VERSION ""

NS_ :

BS_:

BU_: Gateway_25 FCM_A0 FLR SRR_RL External_Tool SRR_FL Steering_E4 VCU_47 CLS_17 ESC_0B EMS_00

BO_ 662 SRR_FL_DETECTION_089_092: 64 SRR_FL
 SG_ DET_RANGE_089 : 24|15@1+ (0.015625,0) [0|500] "m"  SRR_RL
 SG_ DET_RANGE_ERR_089 : 40|7@1+ (0.0075,0) [0|0.9525] "m"  SRR_RL
 SG_ DET_RANGE_VELOCITY_089 : 48|15@1+ (0.0078125,-128) [-128|127.9921875] "m/s"  SRR_RL
 SG_ DET_RANGE_VELOCITY_ERR_089 : 64|8@1+ (0.003,0) [0|0.765] "m/s"  SRR_RL
 SG_ DET_AZIMUTH_089 : 88|13@1+ (0.0004,-1.5708) [-1.5708|1.5708] "rad"  SRR_RL
 SG_ DET_AZIMUTH_ERR_089 : 105|7@1+ (0.00087267,0) [0|0.11082909] "rad"  SRR_RL
 SG_ DET_ELEVATION_089 : 72|8@1+ (0.00275,-0.34925) [-0.34925|0.34925] "rad"  SRR_RL
 SG_ DET_ELEVATION_ERR_089 : 80|6@1+ (0.00174533,0) [0|0.10995579] "rad"  SRR_RL
 SG_ DET_RCS_089 : 128|8@1+ (0.5,-64) [-64|63.5] "dBsm"  SRR_RL
 SG_ DET_BI_STATIC_FLAG_089 : 104|1@1+ (1,0) [0|1] ""  SRR_RL
 SG_ DET_SUPER_RES_TARGET_089 : 87|1@1+ (1,0) [0|1] ""  SRR_RL
 SG_ DET_SNR_089 : 120|8@1+ (0.35156,0) [0|89.6478] "dB"  SRR_RL
 SG_ DET_EXISTENCE_PROB_089 : 112|6@1+ (1.588,0) [0|100] "%"  SRR_RL
 SG_ DET_HVC_FLAG_089 : 86|1@1+ (1,0) [0|1] ""  SRR_RL
 SG_ DET_CONFD_AZIMUTH_089 : 118|2@1+ (1,0) [0|3] ""  SRR_RL
 SG_ DET_CONFD_ELEVATION_089 : 101|2@1+ (1,0) [0|3] ""  SRR_RL
 SG_ DET_PROB_1STAZHYPO_089 : 103|1@1+ (1,0) [0|1] ""  SRR_RL
 SG_ DET_IDM_089 : 63|1@1+ (1,0) [0|1] ""  SRR_RL
 SG_ DET_MTD_089 : 47|1@1+ (1,0) [0|1] ""  SRR_RL
 SG_ DET_BELOW_RAIN_THOLD_089 : 39|1@1+ (1,0) [0|1] ""  SRR_RL
 SG_ DET_RANGE_090 : 136|15@1+ (0.015625,0) [0|500] "m"  SRR_RL
 SG_ DET_RANGE_ERR_090 : 152|7@1+ (0.0075,0) [0|0.9525] "m"  SRR_RL
 SG_ DET_RANGE_VELOCITY_090 : 160|15@1+ (0.0078125,-128) [-128|127.9921875] "m/s"  SRR_RL
 SG_ DET_RANGE_VELOCITY_ERR_090 : 176|8@1+ (0.003,0) [0|0.765] "m/s"  SRR_RL
 SG_ DET_AZIMUTH_090 : 200|13@1+ (0.0004,-1.5708) [-1.5708|1.5708] "rad"  SRR_RL
 SG_ DET_AZIMUTH_ERR_090 : 217|7@1+ (0.00087267,0) [0|0.11082909] "rad"  SRR_RL
 SG_ DET_ELEVATION_090 : 184|8@1+ (0.00275,-0.34925) [-0.34925|0.34925] "rad"  SRR_RL
 SG_ DET_ELEVATION_ERR_090 : 192|6@1+ (0.00174533,0) [0|0.10995579] "rad"  SRR_RL
 SG_ DET_RCS_090 : 240|8@1+ (0.5,-64) [-64|63.5] "dBsm"  SRR_RL
 SG_ DET_BI_STATIC_FLAG_090 : 216|1@1+ (1,0) [0|1] ""  SRR_RL
 SG_ DET_SUPER_RES_TARGET_090 : 199|1@1+ (1,0) [0|1] ""  SRR_RL
 SG_ DET_SNR_090 : 232|8@1+ (0.35156,0) [0|89.6478] "dB"  SRR_RL
 SG_ DET_EXISTENCE_PROB_090 : 224|6@1+ (1.588,0) [0|100] "%"  SRR_RL
 SG_ DET_HVC_FLAG_090 : 198|1@1+ (1,0) [0|1] ""  SRR_RL
 SG_ DET_CONFD_AZIMUTH_090 : 230|2@1+ (1,0) [0|3] ""  SRR_RL
 SG_ DET_CONFD_ELEVATION_090 : 213|2@1+ (1,0) [0|3] ""  SRR_RL
 SG_ DET_PROB_1STAZHYPO_090 : 215|1@1+ (1,0) [0|1] ""  SRR_RL
 SG_ DET_IDM_090 : 175|1@1+ (1,0) [0|1] ""  SRR_RL
 SG_ DET_MTD_090 : 159|1@1+ (1,0) [0|1] ""  SRR_RL
 SG_ DET_BELOW_RAIN_THOLD_090 : 151|1@1+ (1,0) [0|1] ""  SRR_RL
 SG_ DET_RANGE_091 : 248|15@1+ (0.015625,0) [0|500] "m"  SRR_RL
 SG_ DET_RANGE_ERR_091 : 264|7@1+ (0.0075,0) [0|0.9525] "m"  SRR_RL
 SG_ DET_RANGE_VELOCITY_091 : 272|15@1+ (0.0078125,-128) [-128|127.9921875] "m/s"  SRR_RL
 SG_ DET_RANGE_VELOCITY_ERR_091 : 288|8@1+ (0.003,0) [0|0.765] "m/s"  SRR_RL
 SG_ DET_AZIMUTH_091 : 312|13@1+ (0.0004,-1.5708) [-1.5708|1.5708] "rad"  SRR_RL
 SG_ DET_AZIMUTH_ERR_091 : 329|7@1+ (0.00087267,0) [0|0.11082909] "rad"  SRR_RL
 SG_ DET_ELEVATION_091 : 296|8@1+ (0.00275,-0.34925) [-0.34925|0.34925] "rad"  SRR_RL
 SG_ DET_ELEVATION_ERR_091 : 304|6@1+ (0.00174533,0) [0|0.10995579] "rad"  SRR_RL
 SG_ DET_RCS_091 : 352|8@1+ (0.5,-64) [-64|63.5] "dBsm"  SRR_RL
 SG_ DET_BI_STATIC_FLAG_091 : 328|1@1+ (1,0) [0|1] ""  SRR_RL
 SG_ DET_SUPER_RES_TARGET_091 : 311|1@1+ (1,0) [0|1] ""  SRR_RL
 SG_ DET_SNR_091 : 344|8@1+ (0.35156,0) [0|89.6478] "dB"  SRR_RL
 SG_ DET_EXISTENCE_PROB_091 : 336|6@1+ (1.588,0) [0|100] "%"  SRR_RL
 SG_ DET_HVC_FLAG_091 : 310|1@1+ (1,0) [0|1] ""  SRR_RL
 SG_ DET_CONFD_AZIMUTH_091 : 342|2@1+ (1,0) [0|3] ""  SRR_RL
 SG_ DET_CONFD_ELEVATION_091 : 325|2@1+ (1,0) [0|3] ""  SRR_RL
 SG_ DET_PROB_1STAZHYPO_091 : 327|1@1+ (1,0) [0|1] ""  SRR_RL
 SG_ DET_IDM_091 : 287|1@1+ (1,0) [0|1] ""  SRR_RL
 SG_ DET_MTD_091 : 271|1@1+ (1,0) [0|1] ""  SRR_RL
 SG_ DET_BELOW_RAIN_THOLD_091 : 263|1@1+ (1,0) [0|1] ""  SRR_RL
 SG_ DET_RANGE_092 : 360|15@1+ (0.015625,0) [0|500] "m"  SRR_RL
 SG_ DET_RANGE_ERR_092 : 376|7@1+ (0.0075,0) [0|0.9525] "m"  SRR_RL
 SG_ DET_RANGE_VELOCITY_092 : 384|15@1+ (0.0078125,-128) [-128|127.9921875] "m/s"  SRR_RL
 SG_ DET_RANGE_VELOCITY_ERR_092 : 400|8@1+ (0.003,0) [0|0.765] "m/s"  SRR_RL
 SG_ DET_AZIMUTH_092 : 424|13@1+ (0.0004,-1.5708) [-1.5708|1.5708] "rad"  SRR_RL
 SG_ DET_AZIMUTH_ERR_092 : 441|7@1+ (0.00087267,0) [0|0.11082909] "rad"  SRR_RL
 SG_ DET_ELEVATION_092 : 408|8@1+ (0.00275,-0.34925) [-0.34925|0.34925] "rad"  SRR_RL
 SG_ DET_ELEVATION_ERR_092 : 416|6@1+ (0.00174533,0) [0|0.10995579] "rad"  SRR_RL
 SG_ DET_RCS_092 : 464|8@1+ (0.5,-64) [-64|63.5] "dBsm"  SRR_RL
 SG_ DET_BI_STATIC_FLAG_092 : 440|1@1+ (1,0) [0|1] ""  SRR_RL
 SG_ DET_SUPER_RES_TARGET_092 : 423|1@1+ (1,0) [0|1] ""  SRR_RL
 SG_ DET_SNR_092 : 456|8@1+ (0.35156,0) [0|89.6478] "dB"  SRR_RL
 SG_ DET_EXISTENCE_PROB_092 : 448|6@1+ (1.588,0) [0|100] "%"  SRR_RL
 SG_ DET_HVC_FLAG_092 : 422|1@1+ (1,0) [0|1] ""  SRR_RL
 SG_ DET_CONFD_AZIMUTH_092 : 454|2@1+ (1,0) [0|3] ""  SRR_RL
 SG_ DET_CONFD_ELEVATION_092 : 437|2@1+ (1,0) [0|3] ""  SRR_RL
 SG_ DET_MH_SCAN_INDEX_4LSB_089_092 : 476|4@1+ (1,0) [0|15] ""  SRR_RL
 SG_ DET_MH_CYCLE_COUNTER_089_092 : 16|8@1+ (1,0) [0|255] ""  SRR_RL
 SG_ DET_MH_CRC16_089_092 : 0|16@1+ (1,0) [0|65535] ""  SRR_RL
 SG_ DET_PROB_1STAZHYPO_092 : 439|1@1+ (1,0) [0|1] ""  SRR_RL
 SG_ DET_IDM_092 : 399|1@1+ (1,0) [0|1] ""  SRR_RL
 SG_ DET_MTD_092 : 383|1@1+ (1,0) [0|1] ""  SRR_RL
 SG_ DET_BELOW_RAIN_THOLD_092 : 375|1@1+ (1,0) [0|1] ""  SRR_RL

BO_ 663 SRR_FL_DETECTION_093_096: 64 SRR_FL
 SG_ DET_RANGE_093 : 24|15@1+ (0.015625,0) [0|500] "m"  SRR_RL
 SG_ DET_RANGE_ERR_093 : 40|7@1+ (0.0075,0) [0|0.9525] "m"  SRR_RL
 SG_ DET_RANGE_VELOCITY_093 : 48|15@1+ (0.0078125,-128) [-128|127.9921875] "m/s"  SRR_RL
 SG_ DET_RANGE_VELOCITY_ERR_093 : 64|8@1+ (0.003,0) [0|0.765] "m/s"  SRR_RL
 SG_ DET_AZIMUTH_093 : 88|13@1+ (0.0004,-1.5708) [-1.5708|1.5708] "rad"  SRR_RL
 SG_ DET_AZIMUTH_ERR_093 : 105|7@1+ (0.00087267,0) [0|0.11082909] "rad"  SRR_RL
 SG_ DET_ELEVATION_093 : 72|8@1+ (0.00275,-0.34925) [-0.34925|0.34925] "rad"  SRR_RL
 SG_ DET_ELEVATION_ERR_093 : 80|6@1+ (0.00174533,0) [0|0.10995579] "rad"  SRR_RL
 SG_ DET_RCS_093 : 128|8@1+ (0.5,-64) [-64|63.5] "dBsm"  SRR_RL
 SG_ DET_BI_STATIC_FLAG_093 : 104|1@1+ (1,0) [0|1] ""  SRR_RL
 SG_ DET_SUPER_RES_TARGET_093 : 87|1@1+ (1,0) [0|1] ""  SRR_RL
 SG_ DET_SNR_093 : 120|8@1+ (0.35156,0) [0|89.6478] "dB"  SRR_RL
 SG_ DET_EXISTENCE_PROB_093 : 112|6@1+ (1.588,0) [0|100] "%"  SRR_RL
 SG_ DET_HVC_FLAG_093 : 86|1@1+ (1,0) [0|1] ""  SRR_RL
 SG_ DET_CONFD_AZIMUTH_093 : 118|2@1+ (1,0) [0|3] ""  SRR_RL
 SG_ DET_CONFD_ELEVATION_093 : 101|2@1+ (1,0) [0|3] ""  SRR_RL
 SG_ DET_PROB_1STAZHYPO_093 : 103|1@1+ (1,0) [0|1] ""  SRR_RL
 SG_ DET_IDM_093 : 63|1@1+ (1,0) [0|1] ""  SRR_RL
 SG_ DET_MTD_093 : 47|1@1+ (1,0) [0|1] ""  SRR_RL
 SG_ DET_BELOW_RAIN_THOLD_093 : 39|1@1+ (1,0) [0|1] ""  SRR_RL
 SG_ DET_RANGE_094 : 136|15@1+ (0.015625,0) [0|500] "m"  SRR_RL
 SG_ DET_RANGE_ERR_094 : 152|7@1+ (0.0075,0) [0|0.9525] "m"  SRR_RL
 SG_ DET_RANGE_VELOCITY_094 : 160|15@1+ (0.0078125,-128) [-128|127.9921875] "m/s"  SRR_RL
 SG_ DET_RANGE_VELOCITY_ERR_094 : 176|8@1+ (0.003,0) [0|0.765] "m/s"  SRR_RL
 SG_ DET_AZIMUTH_094 : 200|13@1+ (0.0004,-1.5708) [-1.5708|1.5708] "rad"  SRR_RL
 SG_ DET_AZIMUTH_ERR_094 : 217|7@1+ (0.00087267,0) [0|0.11082909] "rad"  SRR_RL
 SG_ DET_ELEVATION_094 : 184|8@1+ (0.00275,-0.34925) [-0.34925|0.34925] "rad"  SRR_RL
 SG_ DET_ELEVATION_ERR_094 : 192|6@1+ (0.00174533,0) [0|0.10995579] "rad"  SRR_RL
 SG_ DET_RCS_094 : 240|8@1+ (0.5,-64) [-64|63.5] "dBsm"  SRR_RL
 SG_ DET_BI_STATIC_FLAG_094 : 216|1@1+ (1,0) [0|1] ""  SRR_RL
 SG_ DET_SUPER_RES_TARGET_094 : 199|1@1+ (1,0) [0|1] ""  SRR_RL
 SG_ DET_SNR_094 : 232|8@1+ (0.35156,0) [0|89.6478] "dB"  SRR_RL
 SG_ DET_EXISTENCE_PROB_094 : 224|6@1+ (1.588,0) [0|100] "%"  SRR_RL
 SG_ DET_HVC_FLAG_094 : 198|1@1+ (1,0) [0|1] ""  SRR_RL
 SG_ DET_CONFD_AZIMUTH_094 : 230|2@1+ (1,0) [0|3] ""  SRR_RL
 SG_ DET_CONFD_ELEVATION_094 : 213|2@1+ (1,0) [0|3] ""  SRR_RL
 SG_ DET_PROB_1STAZHYPO_094 : 215|1@1+ (1,0) [0|1] ""  SRR_RL
 SG_ DET_IDM_094 : 175|1@1+ (1,0) [0|1] ""  SRR_RL
 SG_ DET_MTD_094 : 159|1@1+ (1,0) [0|1] ""  SRR_RL
 SG_ DET_BELOW_RAIN_THOLD_094 : 151|1@1+ (1,0) [0|1] ""  SRR_RL
 SG_ DET_RANGE_095 : 248|15@1+ (0.015625,0) [0|500] "m"  SRR_RL
 SG_ DET_RANGE_ERR_095 : 264|7@1+ (0.0075,0) [0|0.9525] "m"  SRR_RL
 SG_ DET_RANGE_VELOCITY_095 : 272|15@1+ (0.0078125,-128) [-128|127.9921875] "m/s"  SRR_RL
 SG_ DET_RANGE_VELOCITY_ERR_095 : 288|8@1+ (0.003,0) [0|0.765] "m/s"  SRR_RL
 SG_ DET_AZIMUTH_095 : 312|13@1+ (0.0004,-1.5708) [-1.5708|1.5708] "rad"  SRR_RL
 SG_ DET_AZIMUTH_ERR_095 : 329|7@1+ (0.00087267,0) [0|0.11082909] "rad"  SRR_RL
 SG_ DET_ELEVATION_095 : 296|8@1+ (0.00275,-0.34925) [-0.34925|0.34925] "rad"  SRR_RL
 SG_ DET_ELEVATION_ERR_095 : 304|6@1+ (0.00174533,0) [0|0.10995579] "rad"  SRR_RL
 SG_ DET_RCS_095 : 352|8@1+ (0.5,-64) [-64|63.5] "dBsm"  SRR_RL
 SG_ DET_BI_STATIC_FLAG_095 : 328|1@1+ (1,0) [0|1] ""  SRR_RL
 SG_ DET_SUPER_RES_TARGET_095 : 311|1@1+ (1,0) [0|1] ""  SRR_RL
 SG_ DET_SNR_095 : 344|8@1+ (0.35156,0) [0|89.6478] "dB"  SRR_RL
 SG_ DET_EXISTENCE_PROB_095 : 336|6@1+ (1.588,0) [0|100] "%"  SRR_RL
 SG_ DET_HVC_FLAG_095 : 310|1@1+ (1,0) [0|1] ""  SRR_RL
 SG_ DET_CONFD_AZIMUTH_095 : 342|2@1+ (1,0) [0|3] ""  SRR_RL
 SG_ DET_CONFD_ELEVATION_095 : 325|2@1+ (1,0) [0|3] ""  SRR_RL
 SG_ DET_PROB_1STAZHYPO_095 : 327|1@1+ (1,0) [0|1] ""  SRR_RL
 SG_ DET_IDM_095 : 287|1@1+ (1,0) [0|1] ""  SRR_RL
 SG_ DET_MTD_095 : 271|1@1+ (1,0) [0|1] ""  SRR_RL
 SG_ DET_BELOW_RAIN_THOLD_095 : 263|1@1+ (1,0) [0|1] ""  SRR_RL
 SG_ DET_RANGE_096 : 360|15@1+ (0.015625,0) [0|500] "m"  SRR_RL
 SG_ DET_RANGE_ERR_096 : 376|7@1+ (0.0075,0) [0|0.9525] "m"  SRR_RL
 SG_ DET_RANGE_VELOCITY_096 : 384|15@1+ (0.0078125,-128) [-128|127.9921875] "m/s"  SRR_RL
 SG_ DET_RANGE_VELOCITY_ERR_096 : 400|8@1+ (0.003,0) [0|0.765] "m/s"  SRR_RL
 SG_ DET_AZIMUTH_096 : 424|13@1+ (0.0004,-1.5708) [-1.5708|1.5708] "rad"  SRR_RL
 SG_ DET_AZIMUTH_ERR_096 : 441|7@1+ (0.00087267,0) [0|0.11082909] "rad"  SRR_RL
 SG_ DET_ELEVATION_096 : 408|8@1+ (0.00275,-0.34925) [-0.34925|0.34925] "rad"  SRR_RL
 SG_ DET_ELEVATION_ERR_096 : 416|6@1+ (0.00174533,0) [0|0.10995579] "rad"  SRR_RL
 SG_ DET_RCS_096 : 464|8@1+ (0.5,-64) [-64|63.5] "dBsm"  SRR_RL
 SG_ DET_BI_STATIC_FLAG_096 : 440|1@1+ (1,0) [0|1] ""  SRR_RL
 SG_ DET_SUPER_RES_TARGET_096 : 423|1@1+ (1,0) [0|1] ""  SRR_RL
 SG_ DET_SNR_096 : 456|8@1+ (0.35156,0) [0|89.6478] "dB"  SRR_RL
 SG_ DET_EXISTENCE_PROB_096 : 448|6@1+ (1.588,0) [0|100] "%"  SRR_RL
 SG_ DET_HVC_FLAG_096 : 422|1@1+ (1,0) [0|1] ""  SRR_RL
 SG_ DET_CONFD_AZIMUTH_096 : 454|2@1+ (1,0) [0|3] ""  SRR_RL
 SG_ DET_CONFD_ELEVATION_096 : 437|2@1+ (1,0) [0|3] ""  SRR_RL
 SG_ DET_MH_SCAN_INDEX_4LSB_093_096 : 476|4@1+ (1,0) [0|15] ""  SRR_RL
 SG_ DET_MH_CYCLE_COUNTER_093_096 : 16|8@1+ (1,0) [0|255] ""  SRR_RL
 SG_ DET_MH_CRC16_093_096 : 0|16@1+ (1,0) [0|65535] ""  SRR_RL
 SG_ DET_PROB_1STAZHYPO_096 : 439|1@1+ (1,0) [0|1] ""  SRR_RL
 SG_ DET_IDM_096 : 399|1@1+ (1,0) [0|1] ""  SRR_RL
 SG_ DET_MTD_096 : 383|1@1+ (1,0) [0|1] ""  SRR_RL
 SG_ DET_BELOW_RAIN_THOLD_096 : 375|1@1+ (1,0) [0|1] ""  SRR_RL

BO_ 664 SRR_FL_DETECTION_097_100: 64 SRR_FL
 SG_ DET_RANGE_097 : 24|15@1+ (0.015625,0) [0|500] "m"  SRR_RL
 SG_ DET_RANGE_ERR_097 : 40|7@1+ (0.0075,0) [0|0.9525] "m"  SRR_RL
 SG_ DET_RANGE_VELOCITY_097 : 48|15@1+ (0.0078125,-128) [-128|127.9921875] "m/s"  SRR_RL
 SG_ DET_RANGE_VELOCITY_ERR_097 : 64|8@1+ (0.003,0) [0|0.765] "m/s"  SRR_RL
 SG_ DET_AZIMUTH_097 : 88|13@1+ (0.0004,-1.5708) [-1.5708|1.5708] "rad"  SRR_RL
 SG_ DET_AZIMUTH_ERR_097 : 105|7@1+ (0.00087267,0) [0|0.11082909] "rad"  SRR_RL
 SG_ DET_ELEVATION_097 : 72|8@1+ (0.00275,-0.34925) [-0.34925|0.34925] "rad"  SRR_RL
 SG_ DET_ELEVATION_ERR_097 : 80|6@1+ (0.00174533,0) [0|0.10995579] "rad"  SRR_RL
 SG_ DET_RCS_097 : 128|8@1+ (0.5,-64) [-64|63.5] "dBsm"  SRR_RL
 SG_ DET_BI_STATIC_FLAG_097 : 104|1@1+ (1,0) [0|1] ""  SRR_RL
 SG_ DET_SUPER_RES_TARGET_097 : 87|1@1+ (1,0) [0|1] ""  SRR_RL
 SG_ DET_SNR_097 : 120|8@1+ (0.35156,0) [0|89.6478] "dB"  SRR_RL
 SG_ DET_EXISTENCE_PROB_097 : 112|6@1+ (1.588,0) [0|100] "%"  SRR_RL
 SG_ DET_HVC_FLAG_097 : 86|1@1+ (1,0) [0|1] ""  SRR_RL
 SG_ DET_CONFD_AZIMUTH_097 : 118|2@1+ (1,0) [0|3] ""  SRR_RL
 SG_ DET_CONFD_ELEVATION_097 : 101|2@1+ (1,0) [0|3] ""  SRR_RL
 SG_ DET_PROB_1STAZHYPO_097 : 103|1@1+ (1,0) [0|1] ""  SRR_RL
 SG_ DET_IDM_097 : 63|1@1+ (1,0) [0|1] ""  SRR_RL
 SG_ DET_MTD_097 : 47|1@1+ (1,0) [0|1] ""  SRR_RL
 SG_ DET_BELOW_RAIN_THOLD_097 : 39|1@1+ (1,0) [0|1] ""  SRR_RL
 SG_ DET_RANGE_098 : 136|15@1+ (0.015625,0) [0|500] "m"  SRR_RL
 SG_ DET_RANGE_ERR_098 : 152|7@1+ (0.0075,0) [0|0.9525] "m"  SRR_RL
 SG_ DET_RANGE_VELOCITY_098 : 160|15@1+ (0.0078125,-128) [-128|127.9921875] "m/s"  SRR_RL
 SG_ DET_RANGE_VELOCITY_ERR_098 : 176|8@1+ (0.003,0) [0|0.765] "m/s"  SRR_RL
 SG_ DET_AZIMUTH_098 : 200|13@1+ (0.0004,-1.5708) [-1.5708|1.5708] "rad"  SRR_RL
 SG_ DET_AZIMUTH_ERR_098 : 217|7@1+ (0.00087267,0) [0|0.11082909] "rad"  SRR_RL
 SG_ DET_ELEVATION_098 : 184|8@1+ (0.00275,-0.34925) [-0.34925|0.34925] "rad"  SRR_RL
 SG_ DET_ELEVATION_ERR_098 : 192|6@1+ (0.00174533,0) [0|0.10995579] "rad"  SRR_RL
 SG_ DET_RCS_098 : 240|8@1+ (0.5,-64) [-64|63.5] "dBsm"  SRR_RL
 SG_ DET_BI_STATIC_FLAG_098 : 216|1@1+ (1,0) [0|1] ""  SRR_RL
 SG_ DET_SUPER_RES_TARGET_098 : 199|1@1+ (1,0) [0|1] ""  SRR_RL
 SG_ DET_SNR_098 : 232|8@1+ (0.35156,0) [0|89.6478] "dB"  SRR_RL
 SG_ DET_EXISTENCE_PROB_098 : 224|6@1+ (1.588,0) [0|100] "%"  SRR_RL
 SG_ DET_HVC_FLAG_098 : 198|1@1+ (1,0) [0|1] ""  SRR_RL
 SG_ DET_CONFD_AZIMUTH_098 : 230|2@1+ (1,0) [0|3] ""  SRR_RL
 SG_ DET_CONFD_ELEVATION_098 : 213|2@1+ (1,0) [0|3] ""  SRR_RL
 SG_ DET_PROB_1STAZHYPO_098 : 215|1@1+ (1,0) [0|1] ""  SRR_RL
 SG_ DET_IDM_098 : 175|1@1+ (1,0) [0|1] ""  SRR_RL
 SG_ DET_MTD_098 : 159|1@1+ (1,0) [0|1] ""  SRR_RL
 SG_ DET_BELOW_RAIN_THOLD_098 : 151|1@1+ (1,0) [0|1] ""  SRR_RL
 SG_ DET_RANGE_099 : 248|15@1+ (0.015625,0) [0|500] "m"  SRR_RL
 SG_ DET_RANGE_ERR_099 : 264|7@1+ (0.0075,0) [0|0.9525] "m"  SRR_RL
 SG_ DET_RANGE_VELOCITY_099 : 272|15@1+ (0.0078125,-128) [-128|127.9921875] "m/s"  SRR_RL
 SG_ DET_RANGE_VELOCITY_ERR_099 : 288|8@1+ (0.003,0) [0|0.765] "m/s"  SRR_RL
 SG_ DET_AZIMUTH_099 : 312|13@1+ (0.0004,-1.5708) [-1.5708|1.5708] "rad"  SRR_RL
 SG_ DET_AZIMUTH_ERR_099 : 329|7@1+ (0.00087267,0) [0|0.11082909] "rad"  SRR_RL
 SG_ DET_ELEVATION_099 : 296|8@1+ (0.00275,-0.34925) [-0.34925|0.34925] "rad"  SRR_RL
 SG_ DET_ELEVATION_ERR_099 : 304|6@1+ (0.00174533,0) [0|0.10995579] "rad"  SRR_RL
 SG_ DET_RCS_099 : 352|8@1+ (0.5,-64) [-64|63.5] "dBsm"  SRR_RL
 SG_ DET_BI_STATIC_FLAG_099 : 328|1@1+ (1,0) [0|1] ""  SRR_RL
 SG_ DET_SUPER_RES_TARGET_099 : 311|1@1+ (1,0) [0|1] ""  SRR_RL
 SG_ DET_SNR_099 : 344|8@1+ (0.35156,0) [0|89.6478] "dB"  SRR_RL
 SG_ DET_EXISTENCE_PROB_099 : 336|6@1+ (1.588,0) [0|100] "%"  SRR_RL
 SG_ DET_HVC_FLAG_099 : 310|1@1+ (1,0) [0|1] ""  SRR_RL
 SG_ DET_CONFD_AZIMUTH_099 : 342|2@1+ (1,0) [0|3] ""  SRR_RL
 SG_ DET_CONFD_ELEVATION_099 : 325|2@1+ (1,0) [0|3] ""  SRR_RL
 SG_ DET_PROB_1STAZHYPO_099 : 327|1@1+ (1,0) [0|1] ""  SRR_RL
 SG_ DET_IDM_099 : 287|1@1+ (1,0) [0|1] ""  SRR_RL
 SG_ DET_MTD_099 : 271|1@1+ (1,0) [0|1] ""  SRR_RL
 SG_ DET_BELOW_RAIN_THOLD_099 : 263|1@1+ (1,0) [0|1] ""  SRR_RL
 SG_ DET_RANGE_100 : 360|15@1+ (0.015625,0) [0|500] "m"  SRR_RL
 SG_ DET_RANGE_ERR_100 : 376|7@1+ (0.0075,0) [0|0.9525] "m"  SRR_RL
 SG_ DET_RANGE_VELOCITY_100 : 384|15@1+ (0.0078125,-128) [-128|127.9921875] "m/s"  SRR_RL
 SG_ DET_RANGE_VELOCITY_ERR_100 : 400|8@1+ (0.003,0) [0|0.765] "m/s"  SRR_RL
 SG_ DET_AZIMUTH_100 : 424|13@1+ (0.0004,-1.5708) [-1.5708|1.5708] "rad"  SRR_RL
 SG_ DET_AZIMUTH_ERR_100 : 441|7@1+ (0.00087267,0) [0|0.11082909] "rad"  SRR_RL
 SG_ DET_ELEVATION_100 : 408|8@1+ (0.00275,-0.34925) [-0.34925|0.34925] "rad"  SRR_RL
 SG_ DET_ELEVATION_ERR_100 : 416|6@1+ (0.00174533,0) [0|0.10995579] "rad"  SRR_RL
 SG_ DET_RCS_100 : 464|8@1+ (0.5,-64) [-64|63.5] "dBsm"  SRR_RL
 SG_ DET_BI_STATIC_FLAG_100 : 440|1@1+ (1,0) [0|1] ""  SRR_RL
 SG_ DET_SUPER_RES_TARGET_100 : 423|1@1+ (1,0) [0|1] ""  SRR_RL
 SG_ DET_SNR_100 : 456|8@1+ (0.35156,0) [0|89.6478] "dB"  SRR_RL
 SG_ DET_EXISTENCE_PROB_100 : 448|6@1+ (1.588,0) [0|100] "%"  SRR_RL
 SG_ DET_HVC_FLAG_100 : 422|1@1+ (1,0) [0|1] ""  SRR_RL
 SG_ DET_CONFD_AZIMUTH_100 : 454|2@1+ (1,0) [0|3] ""  SRR_RL
 SG_ DET_CONFD_ELEVATION_100 : 437|2@1+ (1,0) [0|3] ""  SRR_RL
 SG_ DET_MH_SCAN_INDEX_4LSB_097_100 : 476|4@1+ (1,0) [0|15] ""  SRR_RL
 SG_ DET_MH_CYCLE_COUNTER_097_100 : 16|8@1+ (1,0) [0|255] ""  SRR_RL
 SG_ DET_MH_CRC16_097_100 : 0|16@1+ (1,0) [0|65535] ""  SRR_RL
 SG_ DET_PROB_1STAZHYPO_100 : 439|1@1+ (1,0) [0|1] ""  SRR_RL
 SG_ DET_IDM_100 : 399|1@1+ (1,0) [0|1] ""  SRR_RL
 SG_ DET_MTD_100 : 383|1@1+ (1,0) [0|1] ""  SRR_RL
 SG_ DET_BELOW_RAIN_THOLD_100 : 375|1@1+ (1,0) [0|1] ""  SRR_RL

BO_ 665 SRR_FL_DETECTION_101_104: 64 SRR_FL
 SG_ DET_RANGE_101 : 24|15@1+ (0.015625,0) [0|500] "m"  SRR_RL
 SG_ DET_RANGE_ERR_101 : 40|7@1+ (0.0075,0) [0|0.9525] "m"  SRR_RL
 SG_ DET_RANGE_VELOCITY_101 : 48|15@1+ (0.0078125,-128) [-128|127.9921875] "m/s"  SRR_RL
 SG_ DET_RANGE_VELOCITY_ERR_101 : 64|8@1+ (0.003,0) [0|0.765] "m/s"  SRR_RL
 SG_ DET_AZIMUTH_101 : 88|13@1+ (0.0004,-1.5708) [-1.5708|1.5708] "rad"  SRR_RL
 SG_ DET_AZIMUTH_ERR_101 : 105|7@1+ (0.00087267,0) [0|0.11082909] "rad"  SRR_RL
 SG_ DET_ELEVATION_101 : 72|8@1+ (0.00275,-0.34925) [-0.34925|0.34925] "rad"  SRR_RL
 SG_ DET_ELEVATION_ERR_101 : 80|6@1+ (0.00174533,0) [0|0.10995579] "rad"  SRR_RL
 SG_ DET_RCS_101 : 128|8@1+ (0.5,-64) [-64|63.5] "dBsm"  SRR_RL
 SG_ DET_BI_STATIC_FLAG_101 : 104|1@1+ (1,0) [0|1] ""  SRR_RL
 SG_ DET_SUPER_RES_TARGET_101 : 87|1@1+ (1,0) [0|1] ""  SRR_RL
 SG_ DET_SNR_101 : 120|8@1+ (0.35156,0) [0|89.6478] "dB"  SRR_RL
 SG_ DET_EXISTENCE_PROB_101 : 112|6@1+ (1.588,0) [0|100] "%"  SRR_RL
 SG_ DET_HVC_FLAG_101 : 86|1@1+ (1,0) [0|1] ""  SRR_RL
 SG_ DET_CONFD_AZIMUTH_101 : 118|2@1+ (1,0) [0|3] ""  SRR_RL
 SG_ DET_CONFD_ELEVATION_101 : 101|2@1+ (1,0) [0|3] ""  SRR_RL
 SG_ DET_PROB_1STAZHYPO_101 : 103|1@1+ (1,0) [0|1] ""  SRR_RL
 SG_ DET_IDM_101 : 63|1@1+ (1,0) [0|1] ""  SRR_RL
 SG_ DET_MTD_101 : 47|1@1+ (1,0) [0|1] ""  SRR_RL
 SG_ DET_BELOW_RAIN_THOLD_101 : 39|1@1+ (1,0) [0|1] ""  SRR_RL
 SG_ DET_RANGE_102 : 136|15@1+ (0.015625,0) [0|500] "m"  SRR_RL
 SG_ DET_RANGE_ERR_102 : 152|7@1+ (0.0075,0) [0|0.9525] "m"  SRR_RL
 SG_ DET_RANGE_VELOCITY_102 : 160|15@1+ (0.0078125,-128) [-128|127.9921875] "m/s"  SRR_RL
 SG_ DET_RANGE_VELOCITY_ERR_102 : 176|8@1+ (0.003,0) [0|0.765] "m/s"  SRR_RL
 SG_ DET_AZIMUTH_102 : 200|13@1+ (0.0004,-1.5708) [-1.5708|1.5708] "rad"  SRR_RL
 SG_ DET_AZIMUTH_ERR_102 : 217|7@1+ (0.00087267,0) [0|0.11082909] "rad"  SRR_RL
 SG_ DET_ELEVATION_102 : 184|8@1+ (0.00275,-0.34925) [-0.34925|0.34925] "rad"  SRR_RL
 SG_ DET_ELEVATION_ERR_102 : 192|6@1+ (0.00174533,0) [0|0.10995579] "rad"  SRR_RL
 SG_ DET_RCS_102 : 240|8@1+ (0.5,-64) [-64|63.5] "dBsm"  SRR_RL
 SG_ DET_BI_STATIC_FLAG_102 : 216|1@1+ (1,0) [0|1] ""  SRR_RL
 SG_ DET_SUPER_RES_TARGET_102 : 199|1@1+ (1,0) [0|1] ""  SRR_RL
 SG_ DET_SNR_102 : 232|8@1+ (0.35156,0) [0|89.6478] "dB"  SRR_RL
 SG_ DET_EXISTENCE_PROB_102 : 224|6@1+ (1.588,0) [0|100] "%"  SRR_RL
 SG_ DET_HVC_FLAG_102 : 198|1@1+ (1,0) [0|1] ""  SRR_RL
 SG_ DET_CONFD_AZIMUTH_102 : 230|2@1+ (1,0) [0|3] ""  SRR_RL
 SG_ DET_CONFD_ELEVATION_102 : 213|2@1+ (1,0) [0|3] ""  SRR_RL
 SG_ DET_PROB_1STAZHYPO_102 : 215|1@1+ (1,0) [0|1] ""  SRR_RL
 SG_ DET_IDM_102 : 175|1@1+ (1,0) [0|1] ""  SRR_RL
 SG_ DET_MTD_102 : 159|1@1+ (1,0) [0|1] ""  SRR_RL
 SG_ DET_BELOW_RAIN_THOLD_102 : 151|1@1+ (1,0) [0|1] ""  SRR_RL
 SG_ DET_RANGE_103 : 248|15@1+ (0.015625,0) [0|500] "m"  SRR_RL
 SG_ DET_RANGE_ERR_103 : 264|7@1+ (0.0075,0) [0|0.9525] "m"  SRR_RL
 SG_ DET_RANGE_VELOCITY_103 : 272|15@1+ (0.0078125,-128) [-128|127.9921875] "m/s"  SRR_RL
 SG_ DET_RANGE_VELOCITY_ERR_103 : 288|8@1+ (0.003,0) [0|0.765] "m/s"  SRR_RL
 SG_ DET_AZIMUTH_103 : 312|13@1+ (0.0004,-1.5708) [-1.5708|1.5708] "rad"  SRR_RL
 SG_ DET_AZIMUTH_ERR_103 : 329|7@1+ (0.00087267,0) [0|0.11082909] "rad"  SRR_RL
 SG_ DET_ELEVATION_103 : 296|8@1+ (0.00275,-0.34925) [-0.34925|0.34925] "rad"  SRR_RL
 SG_ DET_ELEVATION_ERR_103 : 304|6@1+ (0.00174533,0) [0|0.10995579] "rad"  SRR_RL
 SG_ DET_RCS_103 : 352|8@1+ (0.5,-64) [-64|63.5] "dBsm"  SRR_RL
 SG_ DET_BI_STATIC_FLAG_103 : 328|1@1+ (1,0) [0|1] ""  SRR_RL
 SG_ DET_SUPER_RES_TARGET_103 : 311|1@1+ (1,0) [0|1] ""  SRR_RL
 SG_ DET_SNR_103 : 344|8@1+ (0.35156,0) [0|89.6478] "dB"  SRR_RL
 SG_ DET_EXISTENCE_PROB_103 : 336|6@1+ (1.588,0) [0|100] "%"  SRR_RL
 SG_ DET_HVC_FLAG_103 : 310|1@1+ (1,0) [0|1] ""  SRR_RL
 SG_ DET_CONFD_AZIMUTH_103 : 342|2@1+ (1,0) [0|3] ""  SRR_RL
 SG_ DET_CONFD_ELEVATION_103 : 325|2@1+ (1,0) [0|3] ""  SRR_RL
 SG_ DET_PROB_1STAZHYPO_103 : 327|1@1+ (1,0) [0|1] ""  SRR_RL
 SG_ DET_IDM_103 : 287|1@1+ (1,0) [0|1] ""  SRR_RL
 SG_ DET_MTD_103 : 271|1@1+ (1,0) [0|1] ""  SRR_RL
 SG_ DET_BELOW_RAIN_THOLD_103 : 263|1@1+ (1,0) [0|1] ""  SRR_RL
 SG_ DET_RANGE_104 : 360|15@1+ (0.015625,0) [0|500] "m"  SRR_RL
 SG_ DET_RANGE_ERR_104 : 376|7@1+ (0.0075,0) [0|0.9525] "m"  SRR_RL
 SG_ DET_RANGE_VELOCITY_104 : 384|15@1+ (0.0078125,-128) [-128|127.9921875] "m/s"  SRR_RL
 SG_ DET_RANGE_VELOCITY_ERR_104 : 400|8@1+ (0.003,0) [0|0.765] "m/s"  SRR_RL
 SG_ DET_AZIMUTH_104 : 424|13@1+ (0.0004,-1.5708) [-1.5708|1.5708] "rad"  SRR_RL
 SG_ DET_AZIMUTH_ERR_104 : 441|7@1+ (0.00087267,0) [0|0.11082909] "rad"  SRR_RL
 SG_ DET_ELEVATION_104 : 408|8@1+ (0.00275,-0.34925) [-0.34925|0.34925] "rad"  SRR_RL
 SG_ DET_ELEVATION_ERR_104 : 416|6@1+ (0.00174533,0) [0|0.10995579] "rad"  SRR_RL
 SG_ DET_RCS_104 : 464|8@1+ (0.5,-64) [-64|63.5] "dBsm"  SRR_RL
 SG_ DET_BI_STATIC_FLAG_104 : 440|1@1+ (1,0) [0|1] ""  SRR_RL
 SG_ DET_SUPER_RES_TARGET_104 : 423|1@1+ (1,0) [0|1] ""  SRR_RL
 SG_ DET_SNR_104 : 456|8@1+ (0.35156,0) [0|89.6478] "dB"  SRR_RL
 SG_ DET_EXISTENCE_PROB_104 : 448|6@1+ (1.588,0) [0|100] "%"  SRR_RL
 SG_ DET_HVC_FLAG_104 : 422|1@1+ (1,0) [0|1] ""  SRR_RL
 SG_ DET_CONFD_AZIMUTH_104 : 454|2@1+ (1,0) [0|3] ""  SRR_RL
 SG_ DET_CONFD_ELEVATION_104 : 437|2@1+ (1,0) [0|3] ""  SRR_RL
 SG_ DET_MH_SCAN_INDEX_4LSB_101_104 : 476|4@1+ (1,0) [0|15] ""  SRR_RL
 SG_ DET_MH_CYCLE_COUNTER_101_104 : 16|8@1+ (1,0) [0|255] ""  SRR_RL
 SG_ DET_MH_CRC16_101_104 : 0|16@1+ (1,0) [0|65535] ""  SRR_RL
 SG_ DET_PROB_1STAZHYPO_104 : 439|1@1+ (1,0) [0|1] ""  SRR_RL
 SG_ DET_IDM_104 : 399|1@1+ (1,0) [0|1] ""  SRR_RL
 SG_ DET_MTD_104 : 383|1@1+ (1,0) [0|1] ""  SRR_RL
 SG_ DET_BELOW_RAIN_THOLD_104 : 375|1@1+ (1,0) [0|1] ""  SRR_RL

BO_ 666 SRR_FL_DETECTION_105_108: 64 SRR_FL
 SG_ DET_RANGE_105 : 24|15@1+ (0.015625,0) [0|500] "m"  SRR_RL
 SG_ DET_RANGE_ERR_105 : 40|7@1+ (0.0075,0) [0|0.9525] "m"  SRR_RL
 SG_ DET_RANGE_VELOCITY_105 : 48|15@1+ (0.0078125,-128) [-128|127.9921875] "m/s"  SRR_RL
 SG_ DET_RANGE_VELOCITY_ERR_105 : 64|8@1+ (0.003,0) [0|0.765] "m/s"  SRR_RL
 SG_ DET_AZIMUTH_105 : 88|13@1+ (0.0004,-1.5708) [-1.5708|1.5708] "rad"  SRR_RL
 SG_ DET_AZIMUTH_ERR_105 : 105|7@1+ (0.00087267,0) [0|0.11082909] "rad"  SRR_RL
 SG_ DET_ELEVATION_105 : 72|8@1+ (0.00275,-0.34925) [-0.34925|0.34925] "rad"  SRR_RL
 SG_ DET_ELEVATION_ERR_105 : 80|6@1+ (0.00174533,0) [0|0.10995579] "rad"  SRR_RL
 SG_ DET_RCS_105 : 128|8@1+ (0.5,-64) [-64|63.5] "dBsm"  SRR_RL
 SG_ DET_BI_STATIC_FLAG_105 : 104|1@1+ (1,0) [0|1] ""  SRR_RL
 SG_ DET_SUPER_RES_TARGET_105 : 87|1@1+ (1,0) [0|1] ""  SRR_RL
 SG_ DET_SNR_105 : 120|8@1+ (0.35156,0) [0|89.6478] "dB"  SRR_RL
 SG_ DET_EXISTENCE_PROB_105 : 112|6@1+ (1.588,0) [0|100] "%"  SRR_RL
 SG_ DET_HVC_FLAG_105 : 86|1@1+ (1,0) [0|1] ""  SRR_RL
 SG_ DET_CONFD_AZIMUTH_105 : 118|2@1+ (1,0) [0|3] ""  SRR_RL
 SG_ DET_CONFD_ELEVATION_105 : 101|2@1+ (1,0) [0|3] ""  SRR_RL
 SG_ DET_PROB_1STAZHYPO_105 : 103|1@1+ (1,0) [0|1] ""  SRR_RL
 SG_ DET_IDM_105 : 63|1@1+ (1,0) [0|1] ""  SRR_RL
 SG_ DET_MTD_105 : 47|1@1+ (1,0) [0|1] ""  SRR_RL
 SG_ DET_BELOW_RAIN_THOLD_105 : 39|1@1+ (1,0) [0|1] ""  SRR_RL
 SG_ DET_RANGE_106 : 136|15@1+ (0.015625,0) [0|500] "m"  SRR_RL
 SG_ DET_RANGE_ERR_106 : 152|7@1+ (0.0075,0) [0|0.9525] "m"  SRR_RL
 SG_ DET_RANGE_VELOCITY_106 : 160|15@1+ (0.0078125,-128) [-128|127.9921875] "m/s"  SRR_RL
 SG_ DET_RANGE_VELOCITY_ERR_106 : 176|8@1+ (0.003,0) [0|0.765] "m/s"  SRR_RL
 SG_ DET_AZIMUTH_106 : 200|13@1+ (0.0004,-1.5708) [-1.5708|1.5708] "rad"  SRR_RL
 SG_ DET_AZIMUTH_ERR_106 : 217|7@1+ (0.00087267,0) [0|0.11082909] "rad"  SRR_RL
 SG_ DET_ELEVATION_106 : 184|8@1+ (0.00275,-0.34925) [-0.34925|0.34925] "rad"  SRR_RL
 SG_ DET_ELEVATION_ERR_106 : 192|6@1+ (0.00174533,0) [0|0.10995579] "rad"  SRR_RL
 SG_ DET_RCS_106 : 240|8@1+ (0.5,-64) [-64|63.5] "dBsm"  SRR_RL
 SG_ DET_BI_STATIC_FLAG_106 : 216|1@1+ (1,0) [0|1] ""  SRR_RL
 SG_ DET_SUPER_RES_TARGET_106 : 199|1@1+ (1,0) [0|1] ""  SRR_RL
 SG_ DET_SNR_106 : 232|8@1+ (0.35156,0) [0|89.6478] "dB"  SRR_RL
 SG_ DET_EXISTENCE_PROB_106 : 224|6@1+ (1.588,0) [0|100] "%"  SRR_RL
 SG_ DET_HVC_FLAG_106 : 198|1@1+ (1,0) [0|1] ""  SRR_RL
 SG_ DET_CONFD_AZIMUTH_106 : 230|2@1+ (1,0) [0|3] ""  SRR_RL
 SG_ DET_CONFD_ELEVATION_106 : 213|2@1+ (1,0) [0|3] ""  SRR_RL
 SG_ DET_PROB_1STAZHYPO_106 : 215|1@1+ (1,0) [0|1] ""  SRR_RL
 SG_ DET_IDM_106 : 175|1@1+ (1,0) [0|1] ""  SRR_RL
 SG_ DET_MTD_106 : 159|1@1+ (1,0) [0|1] ""  SRR_RL
 SG_ DET_BELOW_RAIN_THOLD_106 : 151|1@1+ (1,0) [0|1] ""  SRR_RL
 SG_ DET_RANGE_107 : 248|15@1+ (0.015625,0) [0|500] "m"  SRR_RL
 SG_ DET_RANGE_ERR_107 : 264|7@1+ (0.0075,0) [0|0.9525] "m"  SRR_RL
 SG_ DET_RANGE_VELOCITY_107 : 272|15@1+ (0.0078125,-128) [-128|127.9921875] "m/s"  SRR_RL
 SG_ DET_RANGE_VELOCITY_ERR_107 : 288|8@1+ (0.003,0) [0|0.765] "m/s"  SRR_RL
 SG_ DET_AZIMUTH_107 : 312|13@1+ (0.0004,-1.5708) [-1.5708|1.5708] "rad"  SRR_RL
 SG_ DET_AZIMUTH_ERR_107 : 329|7@1+ (0.00087267,0) [0|0.11082909] "rad"  SRR_RL
 SG_ DET_ELEVATION_107 : 296|8@1+ (0.00275,-0.34925) [-0.34925|0.34925] "rad"  SRR_RL
 SG_ DET_ELEVATION_ERR_107 : 304|6@1+ (0.00174533,0) [0|0.10995579] "rad"  SRR_RL
 SG_ DET_RCS_107 : 352|8@1+ (0.5,-64) [-64|63.5] "dBsm"  SRR_RL
 SG_ DET_BI_STATIC_FLAG_107 : 328|1@1+ (1,0) [0|1] ""  SRR_RL
 SG_ DET_SUPER_RES_TARGET_107 : 311|1@1+ (1,0) [0|1] ""  SRR_RL
 SG_ DET_SNR_107 : 344|8@1+ (0.35156,0) [0|89.6478] "dB"  SRR_RL
 SG_ DET_EXISTENCE_PROB_107 : 336|6@1+ (1.588,0) [0|100] "%"  SRR_RL
 SG_ DET_HVC_FLAG_107 : 310|1@1+ (1,0) [0|1] ""  SRR_RL
 SG_ DET_CONFD_AZIMUTH_107 : 342|2@1+ (1,0) [0|3] ""  SRR_RL
 SG_ DET_CONFD_ELEVATION_107 : 325|2@1+ (1,0) [0|3] ""  SRR_RL
 SG_ DET_PROB_1STAZHYPO_107 : 327|1@1+ (1,0) [0|1] ""  SRR_RL
 SG_ DET_IDM_107 : 287|1@1+ (1,0) [0|1] ""  SRR_RL
 SG_ DET_MTD_107 : 271|1@1+ (1,0) [0|1] ""  SRR_RL
 SG_ DET_BELOW_RAIN_THOLD_107 : 263|1@1+ (1,0) [0|1] ""  SRR_RL
 SG_ DET_RANGE_108 : 360|15@1+ (0.015625,0) [0|500] "m"  SRR_RL
 SG_ DET_RANGE_ERR_108 : 376|7@1+ (0.0075,0) [0|0.9525] "m"  SRR_RL
 SG_ DET_RANGE_VELOCITY_108 : 384|15@1+ (0.0078125,-128) [-128|127.9921875] "m/s"  SRR_RL
 SG_ DET_RANGE_VELOCITY_ERR_108 : 400|8@1+ (0.003,0) [0|0.765] "m/s"  SRR_RL
 SG_ DET_AZIMUTH_108 : 424|13@1+ (0.0004,-1.5708) [-1.5708|1.5708] "rad"  SRR_RL
 SG_ DET_AZIMUTH_ERR_108 : 441|7@1+ (0.00087267,0) [0|0.11082909] "rad"  SRR_RL
 SG_ DET_ELEVATION_108 : 408|8@1+ (0.00275,-0.34925) [-0.34925|0.34925] "rad"  SRR_RL
 SG_ DET_ELEVATION_ERR_108 : 416|6@1+ (0.00174533,0) [0|0.10995579] "rad"  SRR_RL
 SG_ DET_RCS_108 : 464|8@1+ (0.5,-64) [-64|63.5] "dBsm"  SRR_RL
 SG_ DET_BI_STATIC_FLAG_108 : 440|1@1+ (1,0) [0|1] ""  SRR_RL
 SG_ DET_SUPER_RES_TARGET_108 : 423|1@1+ (1,0) [0|1] ""  SRR_RL
 SG_ DET_SNR_108 : 456|8@1+ (0.35156,0) [0|89.6478] "dB"  SRR_RL
 SG_ DET_EXISTENCE_PROB_108 : 448|6@1+ (1.588,0) [0|100] "%"  SRR_RL
 SG_ DET_HVC_FLAG_108 : 422|1@1+ (1,0) [0|1] ""  SRR_RL
 SG_ DET_CONFD_AZIMUTH_108 : 454|2@1+ (1,0) [0|3] ""  SRR_RL
 SG_ DET_CONFD_ELEVATION_108 : 437|2@1+ (1,0) [0|3] ""  SRR_RL
 SG_ DET_MH_SCAN_INDEX_4LSB_105_108 : 476|4@1+ (1,0) [0|15] ""  SRR_RL
 SG_ DET_MH_CYCLE_COUNTER_105_108 : 16|8@1+ (1,0) [0|255] ""  SRR_RL
 SG_ DET_MH_CRC16_105_108 : 0|16@1+ (1,0) [0|65535] ""  SRR_RL
 SG_ DET_PROB_1STAZHYPO_108 : 439|1@1+ (1,0) [0|1] ""  SRR_RL
 SG_ DET_IDM_108 : 399|1@1+ (1,0) [0|1] ""  SRR_RL
 SG_ DET_MTD_108 : 383|1@1+ (1,0) [0|1] ""  SRR_RL
 SG_ DET_BELOW_RAIN_THOLD_108 : 375|1@1+ (1,0) [0|1] ""  SRR_RL

BO_ 667 SRR_FL_DETECTION_109_112: 64 SRR_FL
 SG_ DET_RANGE_109 : 24|15@1+ (0.015625,0) [0|500] "m"  SRR_RL
 SG_ DET_RANGE_ERR_109 : 40|7@1+ (0.0075,0) [0|0.9525] "m"  SRR_RL
 SG_ DET_RANGE_VELOCITY_109 : 48|15@1+ (0.0078125,-128) [-128|127.9921875] "m/s"  SRR_RL
 SG_ DET_RANGE_VELOCITY_ERR_109 : 64|8@1+ (0.003,0) [0|0.765] "m/s"  SRR_RL
 SG_ DET_AZIMUTH_109 : 88|13@1+ (0.0004,-1.5708) [-1.5708|1.5708] "rad"  SRR_RL
 SG_ DET_AZIMUTH_ERR_109 : 105|7@1+ (0.00087267,0) [0|0.11082909] "rad"  SRR_RL
 SG_ DET_ELEVATION_109 : 72|8@1+ (0.00275,-0.34925) [-0.34925|0.34925] "rad"  SRR_RL
 SG_ DET_ELEVATION_ERR_109 : 80|6@1+ (0.00174533,0) [0|0.10995579] "rad"  SRR_RL
 SG_ DET_RCS_109 : 128|8@1+ (0.5,-64) [-64|63.5] "dBsm"  SRR_RL
 SG_ DET_BI_STATIC_FLAG_109 : 104|1@1+ (1,0) [0|1] ""  SRR_RL
 SG_ DET_SUPER_RES_TARGET_109 : 87|1@1+ (1,0) [0|1] ""  SRR_RL
 SG_ DET_SNR_109 : 120|8@1+ (0.35156,0) [0|89.6478] "dB"  SRR_RL
 SG_ DET_EXISTENCE_PROB_109 : 112|6@1+ (1.588,0) [0|100] "%"  SRR_RL
 SG_ DET_HVC_FLAG_109 : 86|1@1+ (1,0) [0|1] ""  SRR_RL
 SG_ DET_CONFD_AZIMUTH_109 : 118|2@1+ (1,0) [0|3] ""  SRR_RL
 SG_ DET_CONFD_ELEVATION_109 : 101|2@1+ (1,0) [0|3] ""  SRR_RL
 SG_ DET_PROB_1STAZHYPO_109 : 103|1@1+ (1,0) [0|1] ""  SRR_RL
 SG_ DET_IDM_109 : 63|1@1+ (1,0) [0|1] ""  SRR_RL
 SG_ DET_MTD_109 : 47|1@1+ (1,0) [0|1] ""  SRR_RL
 SG_ DET_BELOW_RAIN_THOLD_109 : 39|1@1+ (1,0) [0|1] ""  SRR_RL
 SG_ DET_RANGE_110 : 136|15@1+ (0.015625,0) [0|500] "m"  SRR_RL
 SG_ DET_RANGE_ERR_110 : 152|7@1+ (0.0075,0) [0|0.9525] "m"  SRR_RL
 SG_ DET_RANGE_VELOCITY_110 : 160|15@1+ (0.0078125,-128) [-128|127.9921875] "m/s"  SRR_RL
 SG_ DET_RANGE_VELOCITY_ERR_110 : 176|8@1+ (0.003,0) [0|0.765] "m/s"  SRR_RL
 SG_ DET_AZIMUTH_110 : 200|13@1+ (0.0004,-1.5708) [-1.5708|1.5708] "rad"  SRR_RL
 SG_ DET_AZIMUTH_ERR_110 : 217|7@1+ (0.00087267,0) [0|0.11082909] "rad"  SRR_RL
 SG_ DET_ELEVATION_110 : 184|8@1+ (0.00275,-0.34925) [-0.34925|0.34925] "rad"  SRR_RL
 SG_ DET_ELEVATION_ERR_110 : 192|6@1+ (0.00174533,0) [0|0.10995579] "rad"  SRR_RL
 SG_ DET_RCS_110 : 240|8@1+ (0.5,-64) [-64|63.5] "dBsm"  SRR_RL
 SG_ DET_BI_STATIC_FLAG_110 : 216|1@1+ (1,0) [0|1] ""  SRR_RL
 SG_ DET_SUPER_RES_TARGET_110 : 199|1@1+ (1,0) [0|1] ""  SRR_RL
 SG_ DET_SNR_110 : 232|8@1+ (0.35156,0) [0|89.6478] "dB"  SRR_RL
 SG_ DET_EXISTENCE_PROB_110 : 224|6@1+ (1.588,0) [0|100] "%"  SRR_RL
 SG_ DET_HVC_FLAG_110 : 198|1@1+ (1,0) [0|1] ""  SRR_RL
 SG_ DET_CONFD_AZIMUTH_110 : 230|2@1+ (1,0) [0|3] ""  SRR_RL
 SG_ DET_CONFD_ELEVATION_110 : 213|2@1+ (1,0) [0|3] ""  SRR_RL
 SG_ DET_PROB_1STAZHYPO_110 : 215|1@1+ (1,0) [0|1] ""  SRR_RL
 SG_ DET_IDM_110 : 175|1@1+ (1,0) [0|1] ""  SRR_RL
 SG_ DET_MTD_110 : 159|1@1+ (1,0) [0|1] ""  SRR_RL
 SG_ DET_BELOW_RAIN_THOLD_110 : 151|1@1+ (1,0) [0|1] ""  SRR_RL
 SG_ DET_RANGE_111 : 248|15@1+ (0.015625,0) [0|500] "m"  SRR_RL
 SG_ DET_RANGE_ERR_111 : 264|7@1+ (0.0075,0) [0|0.9525] "m"  SRR_RL
 SG_ DET_RANGE_VELOCITY_111 : 272|15@1+ (0.0078125,-128) [-128|127.9921875] "m/s"  SRR_RL
 SG_ DET_RANGE_VELOCITY_ERR_111 : 288|8@1+ (0.003,0) [0|0.765] "m/s"  SRR_RL
 SG_ DET_AZIMUTH_111 : 312|13@1+ (0.0004,-1.5708) [-1.5708|1.5708] "rad"  SRR_RL
 SG_ DET_AZIMUTH_ERR_111 : 329|7@1+ (0.00087267,0) [0|0.11082909] "rad"  SRR_RL
 SG_ DET_ELEVATION_111 : 296|8@1+ (0.00275,-0.34925) [-0.34925|0.34925] "rad"  SRR_RL
 SG_ DET_ELEVATION_ERR_111 : 304|6@1+ (0.00174533,0) [0|0.10995579] "rad"  SRR_RL
 SG_ DET_RCS_111 : 352|8@1+ (0.5,-64) [-64|63.5] "dBsm"  SRR_RL
 SG_ DET_BI_STATIC_FLAG_111 : 328|1@1+ (1,0) [0|1] ""  SRR_RL
 SG_ DET_SUPER_RES_TARGET_111 : 311|1@1+ (1,0) [0|1] ""  SRR_RL
 SG_ DET_SNR_111 : 344|8@1+ (0.35156,0) [0|89.6478] "dB"  SRR_RL
 SG_ DET_EXISTENCE_PROB_111 : 336|6@1+ (1.588,0) [0|100] "%"  SRR_RL
 SG_ DET_HVC_FLAG_111 : 310|1@1+ (1,0) [0|1] ""  SRR_RL
 SG_ DET_CONFD_AZIMUTH_111 : 342|2@1+ (1,0) [0|3] ""  SRR_RL
 SG_ DET_CONFD_ELEVATION_111 : 325|2@1+ (1,0) [0|3] ""  SRR_RL
 SG_ DET_PROB_1STAZHYPO_111 : 327|1@1+ (1,0) [0|1] ""  SRR_RL
 SG_ DET_IDM_111 : 287|1@1+ (1,0) [0|1] ""  SRR_RL
 SG_ DET_MTD_111 : 271|1@1+ (1,0) [0|1] ""  SRR_RL
 SG_ DET_BELOW_RAIN_THOLD_111 : 263|1@1+ (1,0) [0|1] ""  SRR_RL
 SG_ DET_RANGE_112 : 360|15@1+ (0.015625,0) [0|500] "m"  SRR_RL
 SG_ DET_RANGE_ERR_112 : 376|7@1+ (0.0075,0) [0|0.9525] "m"  SRR_RL
 SG_ DET_RANGE_VELOCITY_112 : 384|15@1+ (0.0078125,-128) [-128|127.9921875] "m/s"  SRR_RL
 SG_ DET_RANGE_VELOCITY_ERR_112 : 400|8@1+ (0.003,0) [0|0.765] "m/s"  SRR_RL
 SG_ DET_AZIMUTH_112 : 424|13@1+ (0.0004,-1.5708) [-1.5708|1.5708] "rad"  SRR_RL
 SG_ DET_AZIMUTH_ERR_112 : 441|7@1+ (0.00087267,0) [0|0.11082909] "rad"  SRR_RL
 SG_ DET_ELEVATION_112 : 408|8@1+ (0.00275,-0.34925) [-0.34925|0.34925] "rad"  SRR_RL
 SG_ DET_ELEVATION_ERR_112 : 416|6@1+ (0.00174533,0) [0|0.10995579] "rad"  SRR_RL
 SG_ DET_RCS_112 : 464|8@1+ (0.5,-64) [-64|63.5] "dBsm"  SRR_RL
 SG_ DET_BI_STATIC_FLAG_112 : 440|1@1+ (1,0) [0|1] ""  SRR_RL
 SG_ DET_SUPER_RES_TARGET_112 : 423|1@1+ (1,0) [0|1] ""  SRR_RL
 SG_ DET_SNR_112 : 456|8@1+ (0.35156,0) [0|89.6478] "dB"  SRR_RL
 SG_ DET_EXISTENCE_PROB_112 : 448|6@1+ (1.588,0) [0|100] "%"  SRR_RL
 SG_ DET_HVC_FLAG_112 : 422|1@1+ (1,0) [0|1] ""  SRR_RL
 SG_ DET_CONFD_AZIMUTH_112 : 454|2@1+ (1,0) [0|3] ""  SRR_RL
 SG_ DET_CONFD_ELEVATION_112 : 437|2@1+ (1,0) [0|3] ""  SRR_RL
 SG_ DET_MH_SCAN_INDEX_4LSB_109_112 : 476|4@1+ (1,0) [0|15] ""  SRR_RL
 SG_ DET_MH_CYCLE_COUNTER_109_112 : 16|8@1+ (1,0) [0|255] ""  SRR_RL
 SG_ DET_MH_CRC16_109_112 : 0|16@1+ (1,0) [0|65535] ""  SRR_RL
 SG_ DET_PROB_1STAZHYPO_112 : 439|1@1+ (1,0) [0|1] ""  SRR_RL
 SG_ DET_IDM_112 : 399|1@1+ (1,0) [0|1] ""  SRR_RL
 SG_ DET_MTD_112 : 383|1@1+ (1,0) [0|1] ""  SRR_RL
 SG_ DET_BELOW_RAIN_THOLD_112 : 375|1@1+ (1,0) [0|1] ""  SRR_RL

BO_ 668 SRR_FL_DETECTION_113_116: 64 SRR_FL
 SG_ DET_RANGE_113 : 24|15@1+ (0.015625,0) [0|500] "m"  SRR_RL
 SG_ DET_RANGE_ERR_113 : 40|7@1+ (0.0075,0) [0|0.9525] "m"  SRR_RL
 SG_ DET_RANGE_VELOCITY_113 : 48|15@1+ (0.0078125,-128) [-128|127.9921875] "m/s"  SRR_RL
 SG_ DET_RANGE_VELOCITY_ERR_113 : 64|8@1+ (0.003,0) [0|0.765] "m/s"  SRR_RL
 SG_ DET_AZIMUTH_113 : 88|13@1+ (0.0004,-1.5708) [-1.5708|1.5708] "rad"  SRR_RL
 SG_ DET_AZIMUTH_ERR_113 : 105|7@1+ (0.00087267,0) [0|0.11082909] "rad"  SRR_RL
 SG_ DET_ELEVATION_113 : 72|8@1+ (0.00275,-0.34925) [-0.34925|0.34925] "rad"  SRR_RL
 SG_ DET_ELEVATION_ERR_113 : 80|6@1+ (0.00174533,0) [0|0.10995579] "rad"  SRR_RL
 SG_ DET_RCS_113 : 128|8@1+ (0.5,-64) [-64|63.5] "dBsm"  SRR_RL
 SG_ DET_BI_STATIC_FLAG_113 : 104|1@1+ (1,0) [0|1] ""  SRR_RL
 SG_ DET_SUPER_RES_TARGET_113 : 87|1@1+ (1,0) [0|1] ""  SRR_RL
 SG_ DET_SNR_113 : 120|8@1+ (0.35156,0) [0|89.6478] "dB"  SRR_RL
 SG_ DET_EXISTENCE_PROB_113 : 112|6@1+ (1.588,0) [0|100] "%"  SRR_RL
 SG_ DET_HVC_FLAG_113 : 86|1@1+ (1,0) [0|1] ""  SRR_RL
 SG_ DET_CONFD_AZIMUTH_113 : 118|2@1+ (1,0) [0|3] ""  SRR_RL
 SG_ DET_CONFD_ELEVATION_113 : 101|2@1+ (1,0) [0|3] ""  SRR_RL
 SG_ DET_PROB_1STAZHYPO_113 : 103|1@1+ (1,0) [0|1] ""  SRR_RL
 SG_ DET_IDM_113 : 63|1@1+ (1,0) [0|1] ""  SRR_RL
 SG_ DET_MTD_113 : 47|1@1+ (1,0) [0|1] ""  SRR_RL
 SG_ DET_BELOW_RAIN_THOLD_113 : 39|1@1+ (1,0) [0|1] ""  SRR_RL
 SG_ DET_RANGE_114 : 136|15@1+ (0.015625,0) [0|500] "m"  SRR_RL
 SG_ DET_RANGE_ERR_114 : 152|7@1+ (0.0075,0) [0|0.9525] "m"  SRR_RL
 SG_ DET_RANGE_VELOCITY_114 : 160|15@1+ (0.0078125,-128) [-128|127.9921875] "m/s"  SRR_RL
 SG_ DET_RANGE_VELOCITY_ERR_114 : 176|8@1+ (0.003,0) [0|0.765] "m/s"  SRR_RL
 SG_ DET_AZIMUTH_114 : 200|13@1+ (0.0004,-1.5708) [-1.5708|1.5708] "rad"  SRR_RL
 SG_ DET_AZIMUTH_ERR_114 : 217|7@1+ (0.00087267,0) [0|0.11082909] "rad"  SRR_RL
 SG_ DET_ELEVATION_114 : 184|8@1+ (0.00275,-0.34925) [-0.34925|0.34925] "rad"  SRR_RL
 SG_ DET_ELEVATION_ERR_114 : 192|6@1+ (0.00174533,0) [0|0.10995579] "rad"  SRR_RL
 SG_ DET_RCS_114 : 240|8@1+ (0.5,-64) [-64|63.5] "dBsm"  SRR_RL
 SG_ DET_BI_STATIC_FLAG_114 : 216|1@1+ (1,0) [0|1] ""  SRR_RL
 SG_ DET_SUPER_RES_TARGET_114 : 199|1@1+ (1,0) [0|1] ""  SRR_RL
 SG_ DET_SNR_114 : 232|8@1+ (0.35156,0) [0|89.6478] "dB"  SRR_RL
 SG_ DET_EXISTENCE_PROB_114 : 224|6@1+ (1.588,0) [0|100] "%"  SRR_RL
 SG_ DET_HVC_FLAG_114 : 198|1@1+ (1,0) [0|1] ""  SRR_RL
 SG_ DET_CONFD_AZIMUTH_114 : 230|2@1+ (1,0) [0|3] ""  SRR_RL
 SG_ DET_CONFD_ELEVATION_114 : 213|2@1+ (1,0) [0|3] ""  SRR_RL
 SG_ DET_PROB_1STAZHYPO_114 : 215|1@1+ (1,0) [0|1] ""  SRR_RL
 SG_ DET_IDM_114 : 175|1@1+ (1,0) [0|1] ""  SRR_RL
 SG_ DET_MTD_114 : 159|1@1+ (1,0) [0|1] ""  SRR_RL
 SG_ DET_BELOW_RAIN_THOLD_114 : 151|1@1+ (1,0) [0|1] ""  SRR_RL
 SG_ DET_RANGE_115 : 248|15@1+ (0.015625,0) [0|500] "m"  SRR_RL
 SG_ DET_RANGE_ERR_115 : 264|7@1+ (0.0075,0) [0|0.9525] "m"  SRR_RL
 SG_ DET_RANGE_VELOCITY_115 : 272|15@1+ (0.0078125,-128) [-128|127.9921875] "m/s"  SRR_RL
 SG_ DET_RANGE_VELOCITY_ERR_115 : 288|8@1+ (0.003,0) [0|0.765] "m/s"  SRR_RL
 SG_ DET_AZIMUTH_115 : 312|13@1+ (0.0004,-1.5708) [-1.5708|1.5708] "rad"  SRR_RL
 SG_ DET_AZIMUTH_ERR_115 : 329|7@1+ (0.00087267,0) [0|0.11082909] "rad"  SRR_RL
 SG_ DET_ELEVATION_115 : 296|8@1+ (0.00275,-0.34925) [-0.34925|0.34925] "rad"  SRR_RL
 SG_ DET_ELEVATION_ERR_115 : 304|6@1+ (0.00174533,0) [0|0.10995579] "rad"  SRR_RL
 SG_ DET_RCS_115 : 352|8@1+ (0.5,-64) [-64|63.5] "dBsm"  SRR_RL
 SG_ DET_BI_STATIC_FLAG_115 : 328|1@1+ (1,0) [0|1] ""  SRR_RL
 SG_ DET_SUPER_RES_TARGET_115 : 311|1@1+ (1,0) [0|1] ""  SRR_RL
 SG_ DET_SNR_115 : 344|8@1+ (0.35156,0) [0|89.6478] "dB"  SRR_RL
 SG_ DET_EXISTENCE_PROB_115 : 336|6@1+ (1.588,0) [0|100] "%"  SRR_RL
 SG_ DET_HVC_FLAG_115 : 310|1@1+ (1,0) [0|1] ""  SRR_RL
 SG_ DET_CONFD_AZIMUTH_115 : 342|2@1+ (1,0) [0|3] ""  SRR_RL
 SG_ DET_CONFD_ELEVATION_115 : 325|2@1+ (1,0) [0|3] ""  SRR_RL
 SG_ DET_PROB_1STAZHYPO_115 : 327|1@1+ (1,0) [0|1] ""  SRR_RL
 SG_ DET_IDM_115 : 287|1@1+ (1,0) [0|1] ""  SRR_RL
 SG_ DET_MTD_115 : 271|1@1+ (1,0) [0|1] ""  SRR_RL
 SG_ DET_BELOW_RAIN_THOLD_115 : 263|1@1+ (1,0) [0|1] ""  SRR_RL
 SG_ DET_RANGE_116 : 360|15@1+ (0.015625,0) [0|500] "m"  SRR_RL
 SG_ DET_RANGE_ERR_116 : 376|7@1+ (0.0075,0) [0|0.9525] "m"  SRR_RL
 SG_ DET_RANGE_VELOCITY_116 : 384|15@1+ (0.0078125,-128) [-128|127.9921875] "m/s"  SRR_RL
 SG_ DET_RANGE_VELOCITY_ERR_116 : 400|8@1+ (0.003,0) [0|0.765] "m/s"  SRR_RL
 SG_ DET_AZIMUTH_116 : 424|13@1+ (0.0004,-1.5708) [-1.5708|1.5708] "rad"  SRR_RL
 SG_ DET_AZIMUTH_ERR_116 : 441|7@1+ (0.00087267,0) [0|0.11082909] "rad"  SRR_RL
 SG_ DET_ELEVATION_116 : 408|8@1+ (0.00275,-0.34925) [-0.34925|0.34925] "rad"  SRR_RL
 SG_ DET_ELEVATION_ERR_116 : 416|6@1+ (0.00174533,0) [0|0.10995579] "rad"  SRR_RL
 SG_ DET_RCS_116 : 464|8@1+ (0.5,-64) [-64|63.5] "dBsm"  SRR_RL
 SG_ DET_BI_STATIC_FLAG_116 : 440|1@1+ (1,0) [0|1] ""  SRR_RL
 SG_ DET_SUPER_RES_TARGET_116 : 423|1@1+ (1,0) [0|1] ""  SRR_RL
 SG_ DET_SNR_116 : 456|8@1+ (0.35156,0) [0|89.6478] "dB"  SRR_RL
 SG_ DET_EXISTENCE_PROB_116 : 448|6@1+ (1.588,0) [0|100] "%"  SRR_RL
 SG_ DET_HVC_FLAG_116 : 422|1@1+ (1,0) [0|1] ""  SRR_RL
 SG_ DET_CONFD_AZIMUTH_116 : 454|2@1+ (1,0) [0|3] ""  SRR_RL
 SG_ DET_CONFD_ELEVATION_116 : 437|2@1+ (1,0) [0|3] ""  SRR_RL
 SG_ DET_MH_SCAN_INDEX_4LSB_113_116 : 476|4@1+ (1,0) [0|15] ""  SRR_RL
 SG_ DET_MH_CYCLE_COUNTER_113_116 : 16|8@1+ (1,0) [0|255] ""  SRR_RL
 SG_ DET_MH_CRC16_113_116 : 0|16@1+ (1,0) [0|65535] ""  SRR_RL
 SG_ DET_PROB_1STAZHYPO_116 : 439|1@1+ (1,0) [0|1] ""  SRR_RL
 SG_ DET_IDM_116 : 399|1@1+ (1,0) [0|1] ""  SRR_RL
 SG_ DET_MTD_116 : 383|1@1+ (1,0) [0|1] ""  SRR_RL
 SG_ DET_BELOW_RAIN_THOLD_116 : 375|1@1+ (1,0) [0|1] ""  SRR_RL

BO_ 669 SRR_FL_DETECTION_117_120: 64 SRR_FL
 SG_ DET_RANGE_117 : 24|15@1+ (0.015625,0) [0|500] "m"  SRR_RL
 SG_ DET_RANGE_ERR_117 : 40|7@1+ (0.0075,0) [0|0.9525] "m"  SRR_RL
 SG_ DET_RANGE_VELOCITY_117 : 48|15@1+ (0.0078125,-128) [-128|127.9921875] "m/s"  SRR_RL
 SG_ DET_RANGE_VELOCITY_ERR_117 : 64|8@1+ (0.003,0) [0|0.765] "m/s"  SRR_RL
 SG_ DET_AZIMUTH_117 : 88|13@1+ (0.0004,-1.5708) [-1.5708|1.5708] "rad"  SRR_RL
 SG_ DET_AZIMUTH_ERR_117 : 105|7@1+ (0.00087267,0) [0|0.11082909] "rad"  SRR_RL
 SG_ DET_ELEVATION_117 : 72|8@1+ (0.00275,-0.34925) [-0.34925|0.34925] "rad"  SRR_RL
 SG_ DET_ELEVATION_ERR_117 : 80|6@1+ (0.00174533,0) [0|0.10995579] "rad"  SRR_RL
 SG_ DET_RCS_117 : 128|8@1+ (0.5,-64) [-64|63.5] "dBsm"  SRR_RL
 SG_ DET_BI_STATIC_FLAG_117 : 104|1@1+ (1,0) [0|1] ""  SRR_RL
 SG_ DET_SUPER_RES_TARGET_117 : 87|1@1+ (1,0) [0|1] ""  SRR_RL
 SG_ DET_SNR_117 : 120|8@1+ (0.35156,0) [0|89.6478] "dB"  SRR_RL
 SG_ DET_EXISTENCE_PROB_117 : 112|6@1+ (1.588,0) [0|100] "%"  SRR_RL
 SG_ DET_HVC_FLAG_117 : 86|1@1+ (1,0) [0|1] ""  SRR_RL
 SG_ DET_CONFD_AZIMUTH_117 : 118|2@1+ (1,0) [0|3] ""  SRR_RL
 SG_ DET_CONFD_ELEVATION_117 : 101|2@1+ (1,0) [0|3] ""  SRR_RL
 SG_ DET_PROB_1STAZHYPO_117 : 103|1@1+ (1,0) [0|1] ""  SRR_RL
 SG_ DET_IDM_117 : 63|1@1+ (1,0) [0|1] ""  SRR_RL
 SG_ DET_MTD_117 : 47|1@1+ (1,0) [0|1] ""  SRR_RL
 SG_ DET_BELOW_RAIN_THOLD_117 : 39|1@1+ (1,0) [0|1] ""  SRR_RL
 SG_ DET_RANGE_118 : 136|15@1+ (0.015625,0) [0|500] "m"  SRR_RL
 SG_ DET_RANGE_ERR_118 : 152|7@1+ (0.0075,0) [0|0.9525] "m"  SRR_RL
 SG_ DET_RANGE_VELOCITY_118 : 160|15@1+ (0.0078125,-128) [-128|127.9921875] "m/s"  SRR_RL
 SG_ DET_RANGE_VELOCITY_ERR_118 : 176|8@1+ (0.003,0) [0|0.765] "m/s"  SRR_RL
 SG_ DET_AZIMUTH_118 : 200|13@1+ (0.0004,-1.5708) [-1.5708|1.5708] "rad"  SRR_RL
 SG_ DET_AZIMUTH_ERR_118 : 217|7@1+ (0.00087267,0) [0|0.11082909] "rad"  SRR_RL
 SG_ DET_ELEVATION_118 : 184|8@1+ (0.00275,-0.34925) [-0.34925|0.34925] "rad"  SRR_RL
 SG_ DET_ELEVATION_ERR_118 : 192|6@1+ (0.00174533,0) [0|0.10995579] "rad"  SRR_RL
 SG_ DET_RCS_118 : 240|8@1+ (0.5,-64) [-64|63.5] "dBsm"  SRR_RL
 SG_ DET_BI_STATIC_FLAG_118 : 216|1@1+ (1,0) [0|1] ""  SRR_RL
 SG_ DET_SUPER_RES_TARGET_118 : 199|1@1+ (1,0) [0|1] ""  SRR_RL
 SG_ DET_SNR_118 : 232|8@1+ (0.35156,0) [0|89.6478] "dB"  SRR_RL
 SG_ DET_EXISTENCE_PROB_118 : 224|6@1+ (1.588,0) [0|100] "%"  SRR_RL
 SG_ DET_HVC_FLAG_118 : 198|1@1+ (1,0) [0|1] ""  SRR_RL
 SG_ DET_CONFD_AZIMUTH_118 : 230|2@1+ (1,0) [0|3] ""  SRR_RL
 SG_ DET_CONFD_ELEVATION_118 : 213|2@1+ (1,0) [0|3] ""  SRR_RL
 SG_ DET_PROB_1STAZHYPO_118 : 215|1@1+ (1,0) [0|1] ""  SRR_RL
 SG_ DET_IDM_118 : 175|1@1+ (1,0) [0|1] ""  SRR_RL
 SG_ DET_MTD_118 : 159|1@1+ (1,0) [0|1] ""  SRR_RL
 SG_ DET_BELOW_RAIN_THOLD_118 : 151|1@1+ (1,0) [0|1] ""  SRR_RL
 SG_ DET_RANGE_119 : 248|15@1+ (0.015625,0) [0|500] "m"  SRR_RL
 SG_ DET_RANGE_ERR_119 : 264|7@1+ (0.0075,0) [0|0.9525] "m"  SRR_RL
 SG_ DET_RANGE_VELOCITY_119 : 272|15@1+ (0.0078125,-128) [-128|127.9921875] "m/s"  SRR_RL
 SG_ DET_RANGE_VELOCITY_ERR_119 : 288|8@1+ (0.003,0) [0|0.765] "m/s"  SRR_RL
 SG_ DET_AZIMUTH_119 : 312|13@1+ (0.0004,-1.5708) [-1.5708|1.5708] "rad"  SRR_RL
 SG_ DET_AZIMUTH_ERR_119 : 329|7@1+ (0.00087267,0) [0|0.11082909] "rad"  SRR_RL
 SG_ DET_ELEVATION_119 : 296|8@1+ (0.00275,-0.34925) [-0.34925|0.34925] "rad"  SRR_RL
 SG_ DET_ELEVATION_ERR_119 : 304|6@1+ (0.00174533,0) [0|0.10995579] "rad"  SRR_RL
 SG_ DET_RCS_119 : 352|8@1+ (0.5,-64) [-64|63.5] "dBsm"  SRR_RL
 SG_ DET_BI_STATIC_FLAG_119 : 328|1@1+ (1,0) [0|1] ""  SRR_RL
 SG_ DET_SUPER_RES_TARGET_119 : 311|1@1+ (1,0) [0|1] ""  SRR_RL
 SG_ DET_SNR_119 : 344|8@1+ (0.35156,0) [0|89.6478] "dB"  SRR_RL
 SG_ DET_EXISTENCE_PROB_119 : 336|6@1+ (1.588,0) [0|100] "%"  SRR_RL
 SG_ DET_HVC_FLAG_119 : 310|1@1+ (1,0) [0|1] ""  SRR_RL
 SG_ DET_CONFD_AZIMUTH_119 : 342|2@1+ (1,0) [0|3] ""  SRR_RL
 SG_ DET_CONFD_ELEVATION_119 : 325|2@1+ (1,0) [0|3] ""  SRR_RL
 SG_ DET_PROB_1STAZHYPO_119 : 327|1@1+ (1,0) [0|1] ""  SRR_RL
 SG_ DET_IDM_119 : 287|1@1+ (1,0) [0|1] ""  SRR_RL
 SG_ DET_MTD_119 : 271|1@1+ (1,0) [0|1] ""  SRR_RL
 SG_ DET_BELOW_RAIN_THOLD_119 : 263|1@1+ (1,0) [0|1] ""  SRR_RL
 SG_ DET_RANGE_120 : 360|15@1+ (0.015625,0) [0|500] "m"  SRR_RL
 SG_ DET_RANGE_ERR_120 : 376|7@1+ (0.0075,0) [0|0.9525] "m"  SRR_RL
 SG_ DET_RANGE_VELOCITY_120 : 384|15@1+ (0.0078125,-128) [-128|127.9921875] "m/s"  SRR_RL
 SG_ DET_RANGE_VELOCITY_ERR_120 : 400|8@1+ (0.003,0) [0|0.765] "m/s"  SRR_RL
 SG_ DET_AZIMUTH_120 : 424|13@1+ (0.0004,-1.5708) [-1.5708|1.5708] "rad"  SRR_RL
 SG_ DET_AZIMUTH_ERR_120 : 441|7@1+ (0.00087267,0) [0|0.11082909] "rad"  SRR_RL
 SG_ DET_ELEVATION_120 : 408|8@1+ (0.00275,-0.34925) [-0.34925|0.34925] "rad"  SRR_RL
 SG_ DET_ELEVATION_ERR_120 : 416|6@1+ (0.00174533,0) [0|0.10995579] "rad"  SRR_RL
 SG_ DET_RCS_120 : 464|8@1+ (0.5,-64) [-64|63.5] "dBsm"  SRR_RL
 SG_ DET_BI_STATIC_FLAG_120 : 440|1@1+ (1,0) [0|1] ""  SRR_RL
 SG_ DET_SUPER_RES_TARGET_120 : 423|1@1+ (1,0) [0|1] ""  SRR_RL
 SG_ DET_SNR_120 : 456|8@1+ (0.35156,0) [0|89.6478] "dB"  SRR_RL
 SG_ DET_EXISTENCE_PROB_120 : 448|6@1+ (1.588,0) [0|100] "%"  SRR_RL
 SG_ DET_HVC_FLAG_120 : 422|1@1+ (1,0) [0|1] ""  SRR_RL
 SG_ DET_CONFD_AZIMUTH_120 : 454|2@1+ (1,0) [0|3] ""  SRR_RL
 SG_ DET_CONFD_ELEVATION_120 : 437|2@1+ (1,0) [0|3] ""  SRR_RL
 SG_ DET_MH_SCAN_INDEX_4LSB_117_120 : 476|4@1+ (1,0) [0|15] ""  SRR_RL
 SG_ DET_MH_CYCLE_COUNTER_117_120 : 16|8@1+ (1,0) [0|255] ""  SRR_RL
 SG_ DET_MH_CRC16_117_120 : 0|16@1+ (1,0) [0|65535] ""  SRR_RL
 SG_ DET_PROB_1STAZHYPO_120 : 439|1@1+ (1,0) [0|1] ""  SRR_RL
 SG_ DET_IDM_120 : 399|1@1+ (1,0) [0|1] ""  SRR_RL
 SG_ DET_MTD_120 : 383|1@1+ (1,0) [0|1] ""  SRR_RL
 SG_ DET_BELOW_RAIN_THOLD_120 : 375|1@1+ (1,0) [0|1] ""  SRR_RL

BO_ 670 SRR_FL_DETECTION_121_124: 64 SRR_FL
 SG_ DET_RANGE_121 : 24|15@1+ (0.015625,0) [0|500] "m"  SRR_RL
 SG_ DET_RANGE_ERR_121 : 40|7@1+ (0.0075,0) [0|0.9525] "m"  SRR_RL
 SG_ DET_RANGE_VELOCITY_121 : 48|15@1+ (0.0078125,-128) [-128|127.9921875] "m/s"  SRR_RL
 SG_ DET_RANGE_VELOCITY_ERR_121 : 64|8@1+ (0.003,0) [0|0.765] "m/s"  SRR_RL
 SG_ DET_AZIMUTH_121 : 88|13@1+ (0.0004,-1.5708) [-1.5708|1.5708] "rad"  SRR_RL
 SG_ DET_AZIMUTH_ERR_121 : 105|7@1+ (0.00087267,0) [0|0.11082909] "rad"  SRR_RL
 SG_ DET_ELEVATION_121 : 72|8@1+ (0.00275,-0.34925) [-0.34925|0.34925] "rad"  SRR_RL
 SG_ DET_ELEVATION_ERR_121 : 80|6@1+ (0.00174533,0) [0|0.10995579] "rad"  SRR_RL
 SG_ DET_RCS_121 : 128|8@1+ (0.5,-64) [-64|63.5] "dBsm"  SRR_RL
 SG_ DET_BI_STATIC_FLAG_121 : 104|1@1+ (1,0) [0|1] ""  SRR_RL
 SG_ DET_SUPER_RES_TARGET_121 : 87|1@1+ (1,0) [0|1] ""  SRR_RL
 SG_ DET_SNR_121 : 120|8@1+ (0.35156,0) [0|89.6478] "dB"  SRR_RL
 SG_ DET_EXISTENCE_PROB_121 : 112|6@1+ (1.588,0) [0|100] "%"  SRR_RL
 SG_ DET_HVC_FLAG_121 : 86|1@1+ (1,0) [0|1] ""  SRR_RL
 SG_ DET_CONFD_AZIMUTH_121 : 118|2@1+ (1,0) [0|3] ""  SRR_RL
 SG_ DET_CONFD_ELEVATION_121 : 101|2@1+ (1,0) [0|3] ""  SRR_RL
 SG_ DET_PROB_1STAZHYPO_121 : 103|1@1+ (1,0) [0|1] ""  SRR_RL
 SG_ DET_IDM_121 : 63|1@1+ (1,0) [0|1] ""  SRR_RL
 SG_ DET_MTD_121 : 47|1@1+ (1,0) [0|1] ""  SRR_RL
 SG_ DET_BELOW_RAIN_THOLD_121 : 39|1@1+ (1,0) [0|1] ""  SRR_RL
 SG_ DET_RANGE_122 : 136|15@1+ (0.015625,0) [0|500] "m"  SRR_RL
 SG_ DET_RANGE_ERR_122 : 152|7@1+ (0.0075,0) [0|0.9525] "m"  SRR_RL
 SG_ DET_RANGE_VELOCITY_122 : 160|15@1+ (0.0078125,-128) [-128|127.9921875] "m/s"  SRR_RL
 SG_ DET_RANGE_VELOCITY_ERR_122 : 176|8@1+ (0.003,0) [0|0.765] "m/s"  SRR_RL
 SG_ DET_AZIMUTH_122 : 200|13@1+ (0.0004,-1.5708) [-1.5708|1.5708] "rad"  SRR_RL
 SG_ DET_AZIMUTH_ERR_122 : 217|7@1+ (0.00087267,0) [0|0.11082909] "rad"  SRR_RL
 SG_ DET_ELEVATION_122 : 184|8@1+ (0.00275,-0.34925) [-0.34925|0.34925] "rad"  SRR_RL
 SG_ DET_ELEVATION_ERR_122 : 192|6@1+ (0.00174533,0) [0|0.10995579] "rad"  SRR_RL
 SG_ DET_RCS_122 : 240|8@1+ (0.5,-64) [-64|63.5] "dBsm"  SRR_RL
 SG_ DET_BI_STATIC_FLAG_122 : 216|1@1+ (1,0) [0|1] ""  SRR_RL
 SG_ DET_SUPER_RES_TARGET_122 : 199|1@1+ (1,0) [0|1] ""  SRR_RL
 SG_ DET_SNR_122 : 232|8@1+ (0.35156,0) [0|89.6478] "dB"  SRR_RL
 SG_ DET_EXISTENCE_PROB_122 : 224|6@1+ (1.588,0) [0|100] "%"  SRR_RL
 SG_ DET_HVC_FLAG_122 : 198|1@1+ (1,0) [0|1] ""  SRR_RL
 SG_ DET_CONFD_AZIMUTH_122 : 230|2@1+ (1,0) [0|3] ""  SRR_RL
 SG_ DET_CONFD_ELEVATION_122 : 213|2@1+ (1,0) [0|3] ""  SRR_RL
 SG_ DET_PROB_1STAZHYPO_122 : 215|1@1+ (1,0) [0|1] ""  SRR_RL
 SG_ DET_IDM_122 : 175|1@1+ (1,0) [0|1] ""  SRR_RL
 SG_ DET_MTD_122 : 159|1@1+ (1,0) [0|1] ""  SRR_RL
 SG_ DET_BELOW_RAIN_THOLD_122 : 151|1@1+ (1,0) [0|1] ""  SRR_RL
 SG_ DET_RANGE_123 : 248|15@1+ (0.015625,0) [0|500] "m"  SRR_RL
 SG_ DET_RANGE_ERR_123 : 264|7@1+ (0.0075,0) [0|0.9525] "m"  SRR_RL
 SG_ DET_RANGE_VELOCITY_123 : 272|15@1+ (0.0078125,-128) [-128|127.9921875] "m/s"  SRR_RL
 SG_ DET_RANGE_VELOCITY_ERR_123 : 288|8@1+ (0.003,0) [0|0.765] "m/s"  SRR_RL
 SG_ DET_AZIMUTH_123 : 312|13@1+ (0.0004,-1.5708) [-1.5708|1.5708] "rad"  SRR_RL
 SG_ DET_AZIMUTH_ERR_123 : 329|7@1+ (0.00087267,0) [0|0.11082909] "rad"  SRR_RL
 SG_ DET_ELEVATION_123 : 296|8@1+ (0.00275,-0.34925) [-0.34925|0.34925] "rad"  SRR_RL
 SG_ DET_ELEVATION_ERR_123 : 304|6@1+ (0.00174533,0) [0|0.10995579] "rad"  SRR_RL
 SG_ DET_RCS_123 : 352|8@1+ (0.5,-64) [-64|63.5] "dBsm"  SRR_RL
 SG_ DET_BI_STATIC_FLAG_123 : 328|1@1+ (1,0) [0|1] ""  SRR_RL
 SG_ DET_SUPER_RES_TARGET_123 : 311|1@1+ (1,0) [0|1] ""  SRR_RL
 SG_ DET_SNR_123 : 344|8@1+ (0.35156,0) [0|89.6478] "dB"  SRR_RL
 SG_ DET_EXISTENCE_PROB_123 : 336|6@1+ (1.588,0) [0|100] "%"  SRR_RL
 SG_ DET_HVC_FLAG_123 : 310|1@1+ (1,0) [0|1] ""  SRR_RL
 SG_ DET_CONFD_AZIMUTH_123 : 342|2@1+ (1,0) [0|3] ""  SRR_RL
 SG_ DET_CONFD_ELEVATION_123 : 325|2@1+ (1,0) [0|3] ""  SRR_RL
 SG_ DET_PROB_1STAZHYPO_123 : 327|1@1+ (1,0) [0|1] ""  SRR_RL
 SG_ DET_IDM_123 : 287|1@1+ (1,0) [0|1] ""  SRR_RL
 SG_ DET_MTD_123 : 271|1@1+ (1,0) [0|1] ""  SRR_RL
 SG_ DET_BELOW_RAIN_THOLD_123 : 263|1@1+ (1,0) [0|1] ""  SRR_RL
 SG_ DET_RANGE_124 : 360|15@1+ (0.015625,0) [0|500] "m"  SRR_RL
 SG_ DET_RANGE_ERR_124 : 376|7@1+ (0.0075,0) [0|0.9525] "m"  SRR_RL
 SG_ DET_RANGE_VELOCITY_124 : 384|15@1+ (0.0078125,-128) [-128|127.9921875] "m/s"  SRR_RL
 SG_ DET_RANGE_VELOCITY_ERR_124 : 400|8@1+ (0.003,0) [0|0.765] "m/s"  SRR_RL
 SG_ DET_AZIMUTH_124 : 424|13@1+ (0.0004,-1.5708) [-1.5708|1.5708] "rad"  SRR_RL
 SG_ DET_AZIMUTH_ERR_124 : 441|7@1+ (0.00087267,0) [0|0.11082909] "rad"  SRR_RL
 SG_ DET_ELEVATION_124 : 408|8@1+ (0.00275,-0.34925) [-0.34925|0.34925] "rad"  SRR_RL
 SG_ DET_ELEVATION_ERR_124 : 416|6@1+ (0.00174533,0) [0|0.10995579] "rad"  SRR_RL
 SG_ DET_RCS_124 : 464|8@1+ (0.5,-64) [-64|63.5] "dBsm"  SRR_RL
 SG_ DET_BI_STATIC_FLAG_124 : 440|1@1+ (1,0) [0|1] ""  SRR_RL
 SG_ DET_SUPER_RES_TARGET_124 : 423|1@1+ (1,0) [0|1] ""  SRR_RL
 SG_ DET_SNR_124 : 456|8@1+ (0.35156,0) [0|89.6478] "dB"  SRR_RL
 SG_ DET_EXISTENCE_PROB_124 : 448|6@1+ (1.588,0) [0|100] "%"  SRR_RL
 SG_ DET_HVC_FLAG_124 : 422|1@1+ (1,0) [0|1] ""  SRR_RL
 SG_ DET_CONFD_AZIMUTH_124 : 454|2@1+ (1,0) [0|3] ""  SRR_RL
 SG_ DET_CONFD_ELEVATION_124 : 437|2@1+ (1,0) [0|3] ""  SRR_RL
 SG_ DET_MH_SCAN_INDEX_4LSB_121_124 : 476|4@1+ (1,0) [0|15] ""  SRR_RL
 SG_ DET_MH_CYCLE_COUNTER_121_124 : 16|8@1+ (1,0) [0|255] ""  SRR_RL
 SG_ DET_MH_CRC16_121_124 : 0|16@1+ (1,0) [0|65535] ""  SRR_RL
 SG_ DET_PROB_1STAZHYPO_124 : 439|1@1+ (1,0) [0|1] ""  SRR_RL
 SG_ DET_IDM_124 : 399|1@1+ (1,0) [0|1] ""  SRR_RL
 SG_ DET_MTD_124 : 383|1@1+ (1,0) [0|1] ""  SRR_RL
 SG_ DET_BELOW_RAIN_THOLD_124 : 375|1@1+ (1,0) [0|1] ""  SRR_RL

BO_ 671 SRR_FL_DETECTION_125_128: 64 SRR_FL
 SG_ DET_RANGE_125 : 24|15@1+ (0.015625,0) [0|500] "m"  SRR_RL
 SG_ DET_RANGE_ERR_125 : 40|7@1+ (0.0075,0) [0|0.9525] "m"  SRR_RL
 SG_ DET_RANGE_VELOCITY_125 : 48|15@1+ (0.0078125,-128) [-128|127.9921875] "m/s"  SRR_RL
 SG_ DET_RANGE_VELOCITY_ERR_125 : 64|8@1+ (0.003,0) [0|0.765] "m/s"  SRR_RL
 SG_ DET_AZIMUTH_125 : 88|13@1+ (0.0004,-1.5708) [-1.5708|1.5708] "rad"  SRR_RL
 SG_ DET_AZIMUTH_ERR_125 : 105|7@1+ (0.00087267,0) [0|0.11082909] "rad"  SRR_RL
 SG_ DET_ELEVATION_125 : 72|8@1+ (0.00275,-0.34925) [-0.34925|0.34925] "rad"  SRR_RL
 SG_ DET_ELEVATION_ERR_125 : 80|6@1+ (0.00174533,0) [0|0.10995579] "rad"  SRR_RL
 SG_ DET_RCS_125 : 128|8@1+ (0.5,-64) [-64|63.5] "dBsm"  SRR_RL
 SG_ DET_BI_STATIC_FLAG_125 : 104|1@1+ (1,0) [0|1] ""  SRR_RL
 SG_ DET_SUPER_RES_TARGET_125 : 87|1@1+ (1,0) [0|1] ""  SRR_RL
 SG_ DET_SNR_125 : 120|8@1+ (0.35156,0) [0|89.6478] "dB"  SRR_RL
 SG_ DET_EXISTENCE_PROB_125 : 112|6@1+ (1.588,0) [0|100] "%"  SRR_RL
 SG_ DET_HVC_FLAG_125 : 86|1@1+ (1,0) [0|1] ""  SRR_RL
 SG_ DET_CONFD_AZIMUTH_125 : 118|2@1+ (1,0) [0|3] ""  SRR_RL
 SG_ DET_CONFD_ELEVATION_125 : 101|2@1+ (1,0) [0|3] ""  SRR_RL
 SG_ DET_PROB_1STAZHYPO_125 : 103|1@1+ (1,0) [0|1] ""  SRR_RL
 SG_ DET_IDM_125 : 63|1@1+ (1,0) [0|1] ""  SRR_RL
 SG_ DET_MTD_125 : 47|1@1+ (1,0) [0|1] ""  SRR_RL
 SG_ DET_BELOW_RAIN_THOLD_125 : 39|1@1+ (1,0) [0|1] ""  SRR_RL
 SG_ DET_RANGE_126 : 136|15@1+ (0.015625,0) [0|500] "m"  SRR_RL
 SG_ DET_RANGE_ERR_126 : 152|7@1+ (0.0075,0) [0|0.9525] "m"  SRR_RL
 SG_ DET_RANGE_VELOCITY_126 : 160|15@1+ (0.0078125,-128) [-128|127.9921875] "m/s"  SRR_RL
 SG_ DET_RANGE_VELOCITY_ERR_126 : 176|8@1+ (0.003,0) [0|0.765] "m/s"  SRR_RL
 SG_ DET_AZIMUTH_126 : 200|13@1+ (0.0004,-1.5708) [-1.5708|1.5708] "rad"  SRR_RL
 SG_ DET_AZIMUTH_ERR_126 : 217|7@1+ (0.00087267,0) [0|0.11082909] "rad"  SRR_RL
 SG_ DET_ELEVATION_126 : 184|8@1+ (0.00275,-0.34925) [-0.34925|0.34925] "rad"  SRR_RL
 SG_ DET_ELEVATION_ERR_126 : 192|6@1+ (0.00174533,0) [0|0.10995579] "rad"  SRR_RL
 SG_ DET_RCS_126 : 240|8@1+ (0.5,-64) [-64|63.5] "dBsm"  SRR_RL
 SG_ DET_BI_STATIC_FLAG_126 : 216|1@1+ (1,0) [0|1] ""  SRR_RL
 SG_ DET_SUPER_RES_TARGET_126 : 199|1@1+ (1,0) [0|1] ""  SRR_RL
 SG_ DET_SNR_126 : 232|8@1+ (0.35156,0) [0|89.6478] "dB"  SRR_RL
 SG_ DET_EXISTENCE_PROB_126 : 224|6@1+ (1.588,0) [0|100] "%"  SRR_RL
 SG_ DET_HVC_FLAG_126 : 198|1@1+ (1,0) [0|1] ""  SRR_RL
 SG_ DET_CONFD_AZIMUTH_126 : 230|2@1+ (1,0) [0|3] ""  SRR_RL
 SG_ DET_CONFD_ELEVATION_126 : 213|2@1+ (1,0) [0|3] ""  SRR_RL
 SG_ DET_PROB_1STAZHYPO_126 : 215|1@1+ (1,0) [0|1] ""  SRR_RL
 SG_ DET_IDM_126 : 175|1@1+ (1,0) [0|1] ""  SRR_RL
 SG_ DET_MTD_126 : 159|1@1+ (1,0) [0|1] ""  SRR_RL
 SG_ DET_BELOW_RAIN_THOLD_126 : 151|1@1+ (1,0) [0|1] ""  SRR_RL
 SG_ DET_RANGE_127 : 248|15@1+ (0.015625,0) [0|500] "m"  SRR_RL
 SG_ DET_RANGE_ERR_127 : 264|7@1+ (0.0075,0) [0|0.9525] "m"  SRR_RL
 SG_ DET_RANGE_VELOCITY_127 : 272|15@1+ (0.0078125,-128) [-128|127.9921875] "m/s"  SRR_RL
 SG_ DET_RANGE_VELOCITY_ERR_127 : 288|8@1+ (0.003,0) [0|0.765] "m/s"  SRR_RL
 SG_ DET_AZIMUTH_127 : 312|13@1+ (0.0004,-1.5708) [-1.5708|1.5708] "rad"  SRR_RL
 SG_ DET_AZIMUTH_ERR_127 : 329|7@1+ (0.00087267,0) [0|0.11082909] "rad"  SRR_RL
 SG_ DET_ELEVATION_127 : 296|8@1+ (0.00275,-0.34925) [-0.34925|0.34925] "rad"  SRR_RL
 SG_ DET_ELEVATION_ERR_127 : 304|6@1+ (0.00174533,0) [0|0.10995579] "rad"  SRR_RL
 SG_ DET_RCS_127 : 352|8@1+ (0.5,-64) [-64|63.5] "dBsm"  SRR_RL
 SG_ DET_BI_STATIC_FLAG_127 : 328|1@1+ (1,0) [0|1] ""  SRR_RL
 SG_ DET_SUPER_RES_TARGET_127 : 311|1@1+ (1,0) [0|1] ""  SRR_RL
 SG_ DET_SNR_127 : 344|8@1+ (0.35156,0) [0|89.6478] "dB"  SRR_RL
 SG_ DET_EXISTENCE_PROB_127 : 336|6@1+ (1.588,0) [0|100] "%"  SRR_RL
 SG_ DET_HVC_FLAG_127 : 310|1@1+ (1,0) [0|1] ""  SRR_RL
 SG_ DET_CONFD_AZIMUTH_127 : 342|2@1+ (1,0) [0|3] ""  SRR_RL
 SG_ DET_CONFD_ELEVATION_127 : 325|2@1+ (1,0) [0|3] ""  SRR_RL
 SG_ DET_PROB_1STAZHYPO_127 : 327|1@1+ (1,0) [0|1] ""  SRR_RL
 SG_ DET_IDM_127 : 287|1@1+ (1,0) [0|1] ""  SRR_RL
 SG_ DET_MTD_127 : 271|1@1+ (1,0) [0|1] ""  SRR_RL
 SG_ DET_BELOW_RAIN_THOLD_127 : 263|1@1+ (1,0) [0|1] ""  SRR_RL
 SG_ DET_RANGE_128 : 360|15@1+ (0.015625,0) [0|500] "m"  SRR_RL
 SG_ DET_RANGE_ERR_128 : 376|7@1+ (0.0075,0) [0|0.9525] "m"  SRR_RL
 SG_ DET_RANGE_VELOCITY_128 : 384|15@1+ (0.0078125,-128) [-128|127.9921875] "m/s"  SRR_RL
 SG_ DET_RANGE_VELOCITY_ERR_128 : 400|8@1+ (0.003,0) [0|0.765] "m/s"  SRR_RL
 SG_ DET_AZIMUTH_128 : 424|13@1+ (0.0004,-1.5708) [-1.5708|1.5708] "rad"  SRR_RL
 SG_ DET_AZIMUTH_ERR_128 : 441|7@1+ (0.00087267,0) [0|0.11082909] "rad"  SRR_RL
 SG_ DET_ELEVATION_128 : 408|8@1+ (0.00275,-0.34925) [-0.34925|0.34925] "rad"  SRR_RL
 SG_ DET_ELEVATION_ERR_128 : 416|6@1+ (0.00174533,0) [0|0.10995579] "rad"  SRR_RL
 SG_ DET_RCS_128 : 464|8@1+ (0.5,-64) [-64|63.5] "dBsm"  SRR_RL
 SG_ DET_BI_STATIC_FLAG_128 : 440|1@1+ (1,0) [0|1] ""  SRR_RL
 SG_ DET_SUPER_RES_TARGET_128 : 423|1@1+ (1,0) [0|1] ""  SRR_RL
 SG_ DET_SNR_128 : 456|8@1+ (0.35156,0) [0|89.6478] "dB"  SRR_RL
 SG_ DET_EXISTENCE_PROB_128 : 448|6@1+ (1.588,0) [0|100] "%"  SRR_RL
 SG_ DET_HVC_FLAG_128 : 422|1@1+ (1,0) [0|1] ""  SRR_RL
 SG_ DET_CONFD_AZIMUTH_128 : 454|2@1+ (1,0) [0|3] ""  SRR_RL
 SG_ DET_CONFD_ELEVATION_128 : 437|2@1+ (1,0) [0|3] ""  SRR_RL
 SG_ DET_MH_SCAN_INDEX_4LSB_125_128 : 476|4@1+ (1,0) [0|15] ""  SRR_RL
 SG_ DET_MH_CYCLE_COUNTER_125_128 : 16|8@1+ (1,0) [0|255] ""  SRR_RL
 SG_ DET_MH_CRC16_125_128 : 0|16@1+ (1,0) [0|65535] ""  SRR_RL
 SG_ DET_PROB_1STAZHYPO_128 : 439|1@1+ (1,0) [0|1] ""  SRR_RL
 SG_ DET_IDM_128 : 399|1@1+ (1,0) [0|1] ""  SRR_RL
 SG_ DET_MTD_128 : 383|1@1+ (1,0) [0|1] ""  SRR_RL
 SG_ DET_BELOW_RAIN_THOLD_128 : 375|1@1+ (1,0) [0|1] ""  SRR_RL

BO_ 2564469232 SRR_FL_DIAG_REQ_PHYS_OBD1: 64 FLR
 SG_ Dummy_signal : 0|64@1+ (1,0) [0|1.84467440737096E+19] ""  SRR_FL

BO_ 2564469233 SRR_FL_DIAG_REQ_PHYS_OBD2: 64 FLR
 SG_ Dummy_signal : 0|64@1+ (1,0) [0|1.84467440737096E+19] ""  SRR_FL

BO_ 40 SRR_FL_XCP_CTO_REQ: 64 External_Tool
 SG_ STS_XCP_REQ_CTO_Byte1 : 15|8@0+ (1,0) [0|255] ""  SRR_FL
 SG_ STS_XCP_REQ_CTO_Byte2 : 23|8@0+ (1,0) [0|255] ""  SRR_FL
 SG_ STS_XCP_REQ_CTO_Byte3 : 31|8@0+ (1,0) [0|255] ""  SRR_FL
 SG_ STS_XCP_REQ_CTO_Byte4 : 39|8@0+ (1,0) [0|255] ""  SRR_FL
 SG_ STS_XCP_REQ_CTO_Byte5 : 47|8@0+ (1,0) [0|255] ""  SRR_FL
 SG_ STS_XCP_REQ_CTO_Byte6 : 55|8@0+ (1,0) [0|255] ""  SRR_FL
 SG_ STS_XCP_REQ_CTO_Byte7 : 63|8@0+ (1,0) [0|255] ""  SRR_FL
 SG_ STS_XCP_REQ_CTO_Byte8 : 71|8@0+ (1,0) [0|255] ""  SRR_FL
 SG_ STS_XCP_REQ_CTO_Byte9 : 79|8@0+ (1,0) [0|255] ""  SRR_FL
 SG_ STS_XCP_REQ_CTO_Byte10 : 87|8@0+ (1,0) [0|255] ""  SRR_FL
 SG_ STS_XCP_REQ_CTO_Byte11 : 95|8@0+ (1,0) [0|255] ""  SRR_FL
 SG_ STS_XCP_REQ_CTO_Byte12 : 103|8@0+ (1,0) [0|255] ""  SRR_FL
 SG_ STS_XCP_REQ_CTO_Byte13 : 111|8@0+ (1,0) [0|255] ""  SRR_FL
 SG_ STS_XCP_REQ_CTO_Byte14 : 119|8@0+ (1,0) [0|255] ""  SRR_FL
 SG_ STS_XCP_REQ_CTO_Byte15 : 127|8@0+ (1,0) [0|255] ""  SRR_FL
 SG_ STS_XCP_REQ_CTO_Byte16 : 135|8@0+ (1,0) [0|255] ""  SRR_FL
 SG_ STS_XCP_REQ_CTO_Byte17 : 143|8@0+ (1,0) [0|255] ""  SRR_FL
 SG_ STS_XCP_REQ_CTO_Byte18 : 151|8@0+ (1,0) [0|255] ""  SRR_FL
 SG_ STS_XCP_REQ_CTO_Byte19 : 159|8@0+ (1,0) [0|255] ""  SRR_FL
 SG_ STS_XCP_REQ_CTO_Byte20 : 167|8@0+ (1,0) [0|255] ""  SRR_FL
 SG_ STS_XCP_REQ_CTO_Byte21 : 175|8@0+ (1,0) [0|255] ""  SRR_FL
 SG_ STS_XCP_REQ_CTO_Byte22 : 183|8@0+ (1,0) [0|255] ""  SRR_FL
 SG_ STS_XCP_REQ_CTO_Byte23 : 191|8@0+ (1,0) [0|255] ""  SRR_FL
 SG_ STS_XCP_REQ_CTO_Byte24 : 199|8@0+ (1,0) [0|255] ""  SRR_FL
 SG_ STS_XCP_REQ_CTO_Byte25 : 207|8@0+ (1,0) [0|255] ""  SRR_FL
 SG_ STS_XCP_REQ_CTO_Byte26 : 215|8@0+ (1,0) [0|255] ""  SRR_FL
 SG_ STS_XCP_REQ_CTO_Byte27 : 223|8@0+ (1,0) [0|255] ""  SRR_FL
 SG_ STS_XCP_REQ_CTO_Byte28 : 231|8@0+ (1,0) [0|255] ""  SRR_FL
 SG_ STS_XCP_REQ_CTO_Byte29 : 239|8@0+ (1,0) [0|255] ""  SRR_FL
 SG_ STS_XCP_REQ_CTO_Byte30 : 247|8@0+ (1,0) [0|255] ""  SRR_FL
 SG_ STS_XCP_REQ_CTO_Byte31 : 255|8@0+ (1,0) [0|255] ""  SRR_FL
 SG_ STS_XCP_REQ_CTO_Byte32 : 263|8@0+ (1,0) [0|255] ""  SRR_FL
 SG_ STS_XCP_REQ_CTO_Byte33 : 271|8@0+ (1,0) [0|255] ""  SRR_FL
 SG_ STS_XCP_REQ_CTO_Byte34 : 279|8@0+ (1,0) [0|255] ""  SRR_FL
 SG_ STS_XCP_REQ_CTO_Byte35 : 287|8@0+ (1,0) [0|255] ""  SRR_FL
 SG_ STS_XCP_REQ_CTO_Byte36 : 295|8@0+ (1,0) [0|255] ""  SRR_FL
 SG_ STS_XCP_REQ_CTO_Byte37 : 303|8@0+ (1,0) [0|255] ""  SRR_FL
 SG_ STS_XCP_REQ_CTO_Byte38 : 311|8@0+ (1,0) [0|255] ""  SRR_FL
 SG_ STS_XCP_REQ_CTO_Byte39 : 319|8@0+ (1,0) [0|255] ""  SRR_FL
 SG_ STS_XCP_REQ_CTO_Byte40 : 327|8@0+ (1,0) [0|255] ""  SRR_FL
 SG_ STS_XCP_REQ_CTO_Byte41 : 335|8@0+ (1,0) [0|255] ""  SRR_FL
 SG_ STS_XCP_REQ_CTO_Byte42 : 343|8@0+ (1,0) [0|255] ""  SRR_FL
 SG_ STS_XCP_REQ_CTO_Byte43 : 351|8@0+ (1,0) [0|255] ""  SRR_FL
 SG_ STS_XCP_REQ_CTO_Byte44 : 359|8@0+ (1,0) [0|255] ""  SRR_FL
 SG_ STS_XCP_REQ_CTO_Byte45 : 367|8@0+ (1,0) [0|255] ""  SRR_FL
 SG_ STS_XCP_REQ_CTO_Byte46 : 375|8@0+ (1,0) [0|255] ""  SRR_FL
 SG_ STS_XCP_REQ_CTO_Byte47 : 383|8@0+ (1,0) [0|255] ""  SRR_FL
 SG_ STS_XCP_REQ_CTO_Byte48 : 391|8@0+ (1,0) [0|255] ""  SRR_FL
 SG_ STS_XCP_REQ_CTO_Byte49 : 399|8@0+ (1,0) [0|255] ""  SRR_FL
 SG_ STS_XCP_REQ_CTO_Byte50 : 407|8@0+ (1,0) [0|255] ""  SRR_FL
 SG_ STS_XCP_REQ_CTO_Byte51 : 415|8@0+ (1,0) [0|255] ""  SRR_FL
 SG_ STS_XCP_REQ_CTO_Byte52 : 423|8@0+ (1,0) [0|255] ""  SRR_FL
 SG_ STS_XCP_REQ_CTO_Byte53 : 431|8@0+ (1,0) [0|255] ""  SRR_FL
 SG_ STS_XCP_REQ_CTO_Byte54 : 439|8@0+ (1,0) [0|255] ""  SRR_FL
 SG_ STS_XCP_REQ_CTO_Byte55 : 447|8@0+ (1,0) [0|255] ""  SRR_FL
 SG_ STS_XCP_REQ_CTO_Byte56 : 455|8@0+ (1,0) [0|255] ""  SRR_FL
 SG_ STS_XCP_REQ_CTO_Byte57 : 463|8@0+ (1,0) [0|255] ""  SRR_FL
 SG_ STS_XCP_REQ_CTO_Byte58 : 471|8@0+ (1,0) [0|255] ""  SRR_FL
 SG_ STS_XCP_REQ_CTO_Byte59 : 479|8@0+ (1,0) [0|255] ""  SRR_FL
 SG_ STS_XCP_REQ_CTO_Byte60 : 487|8@0+ (1,0) [0|255] ""  SRR_FL
 SG_ STS_XCP_REQ_CTO_Byte61 : 495|8@0+ (1,0) [0|255] ""  SRR_FL
 SG_ STS_XCP_REQ_CTO_Byte62 : 503|8@0+ (1,0) [0|255] ""  SRR_FL
 SG_ STS_XCP_REQ_CTO_Byte63 : 511|8@0+ (1,0) [0|255] ""  SRR_FL
 SG_ STS_PID : 7|8@0+ (1,0) [0|255] ""  SRR_FL

BO_ 2566834865 DM1_B1: 22 SRR_FL
 SG_ DTC5 : 144|32@1+ (1,0) [0|4294967295] ""  FLR
 SG_ DTC4 : 112|32@1+ (1,0) [0|4294967295] ""  FLR
 SG_ DTC3 : 80|32@1+ (1,0) [0|4294967295] ""  FLR
 SG_ DTC2 : 48|32@1+ (1,0) [0|4294967295] ""  FLR
 SG_ DTC1 : 16|32@1+ (1,0) [0|4294967295] ""  FLR
 SG_ AmberWarningLampStatus : 2|2@1+ (1,0) [0|3] ""  FLR

BO_ 2566834864 DM1_B0: 22 SRR_RL
 SG_ DTC5 : 144|32@1+ (1,0) [0|4294967295] ""  FLR
 SG_ DTC4 : 112|32@1+ (1,0) [0|4294967295] ""  FLR
 SG_ DTC3 : 80|32@1+ (1,0) [0|4294967295] ""  FLR
 SG_ DTC2 : 48|32@1+ (1,0) [0|4294967295] ""  FLR
 SG_ DTC1 : 16|32@1+ (1,0) [0|4294967295] ""  FLR
 SG_ AmberWarningLampStatus : 2|2@1+ (1,0) [0|3] ""  FLR

BO_ 2566834896 DM1_D0: 22 Vector__XXX
 SG_ DTC5 : 144|32@1+ (1,0) [0|4294967295] "" Vector__XXX
 SG_ DTC4 : 112|32@1+ (1,0) [0|4294967295] "" Vector__XXX
 SG_ DTC3 : 80|32@1+ (1,0) [0|4294967295] "" Vector__XXX
 SG_ DTC2 : 48|32@1+ (1,0) [0|4294967295] "" Vector__XXX
 SG_ DTC1 : 16|32@1+ (1,0) [0|4294967295] "" Vector__XXX
 SG_ AmberWarningLampStatus : 2|2@1+ (1,0) [0|3] "" Vector__XXX

BO_ 2566834920 DM1_E8: 22 Vector__XXX
 SG_ DTC5 : 144|32@1+ (1,0) [0|4294967295] "" Vector__XXX
 SG_ DTC4 : 112|32@1+ (1,0) [0|4294967295] "" Vector__XXX
 SG_ DTC3 : 80|32@1+ (1,0) [0|4294967295] "" Vector__XXX
 SG_ DTC2 : 48|32@1+ (1,0) [0|4294967295] "" Vector__XXX
 SG_ DTC1 : 16|32@1+ (1,0) [0|4294967295] "" Vector__XXX
 SG_ AmberWarningLampStatus : 2|2@1+ (1,0) [0|3] "" Vector__XXX

BO_ 2566834848 DM1_A0: 22 Vector__XXX
 SG_ DTC5 : 144|32@1+ (1,0) [0|4294967295] "" Vector__XXX
 SG_ DTC4 : 112|32@1+ (1,0) [0|4294967295] "" Vector__XXX
 SG_ DTC3 : 80|32@1+ (1,0) [0|4294967295] "" Vector__XXX
 SG_ DTC2 : 48|32@1+ (1,0) [0|4294967295] "" Vector__XXX
 SG_ DTC1 : 16|32@1+ (1,0) [0|4294967295] "" Vector__XXX
 SG_ AmberWarningLampStatus : 2|2@1+ (1,0) [0|3] "" Vector__XXX

BO_ 2566832407 VHDR: 8 CLS_17
 SG_ HghRsolutionTotalVehicleDistance : 32|32@1+ (5,0) [0|21474836475] "meter" Vector__XXX

BO_ 2564882209 CM1: 8 CLS_17
 SG_ SelectedMaxVehicleSpeedLimit : 56|8@1+ (1,0) [0|250] "" Vector__XXX
 SG_ RqCabZoneHeating : 54|2@1+ (1,0) [0|3] "" Vector__XXX
 SG_ RqEngZoneHeating : 52|2@1+ (1,0) [0|3] "" Vector__XXX
 SG_ AuxHeaterModeRq : 48|4@1+ (1,0) [0|15] "" Vector__XXX
 SG_ EngAutomaticStartEnableSwitch : 46|2@1+ (1,0) [0|3] "" Vector__XXX
 SG_ AtomaticGearShiftingEnableSwitch : 44|2@1+ (1,0) [0|3] "" Vector__XXX
 SG_ AFTRegenForceSw : 42|2@1+ (1,0) [0|3] "" Vector__XXX
 SG_ AFTRegenInhSw : 40|2@1+ (1,0) [0|3] "" Vector__XXX
 SG_ VhclLmtngSpdGovernorEnableSwitch : 38|2@1+ (1,0) [0|3] "" Vector__XXX
 SG_ VhclLmtngSpdGvrnrIncrementSwitch : 36|2@1+ (1,0) [0|3] "" Vector__XXX
 SG_ VhclLmtngSpdGvrnrDecrementSwitch : 34|2@1+ (1,0) [0|3] "" Vector__XXX
 SG_ ParkBrakeCmd : 32|2@1+ (1,0) [0|3] "" Vector__XXX
 SG_ SeatBeltSwitch : 30|2@1+ (1,0) [0|3] "" Vector__XXX
 SG_ OperatorSeatDirectionSwitch : 28|2@1+ (1,0) [0|3] "" Vector__XXX
 SG_ BatteryMainSwitchHoldRq : 26|2@1+ (1,0) [0|3] "" Vector__XXX
 SG_ AuxHeaterCoolantPumpRq : 24|2@1+ (1,0) [0|3] "" Vector__XXX
 SG_ CabInteriorTempCmd : 8|16@1+ (0.03125,-273) [-273|1734.96875] "�C" Vector__XXX
 SG_ RequestedPercentFanSpeed : 0|8@1+ (0.4,0) [0|100] "%" Vector__XXX

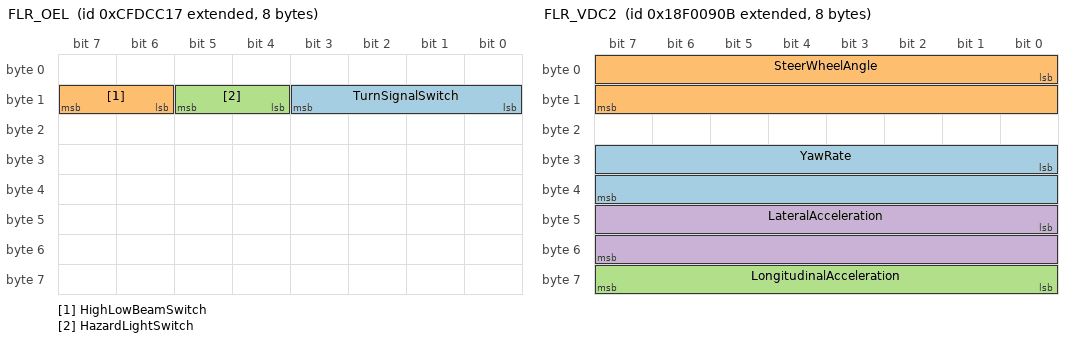
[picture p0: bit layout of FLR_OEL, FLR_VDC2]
BO_ 2365443095 FLR_OEL: 8 FLR
 SG_ TurnSignalSwitch : 8|4@1+ (1,0) [0|15] ""  SRR_RL,SRR_FL
 SG_ HighLowBeamSwitch : 14|2@1+ (1,0) [0|3] ""  SRR_RL,SRR_FL
 SG_ HazardLightSwitch : 12|2@1+ (1,0) [0|3] ""  SRR_RL,SRR_FL

BO_ 2565867787 FLR_VDC2: 8 FLR
 SG_ YawRate : 24|16@1+ (0.00012207,-3.92) [-3.92|3.92] ""  SRR_RL,SRR_FL
 SG_ SteerWheelAngle : 0|16@1+ (0.00097656,-31.374) [-31.374|31.374] ""  SRR_RL,SRR_FL
 SG_ LongitudinalAcceleration : 56|8@1+ (0.1,-12.5) [-12.5|12.5] ""  SRR_RL,SRR_FL
 SG_ LateralAcceleration : 40|16@1+ (0.00048828,-15.687) [-15.687|15.687] ""  SRR_RL,SRR_FL

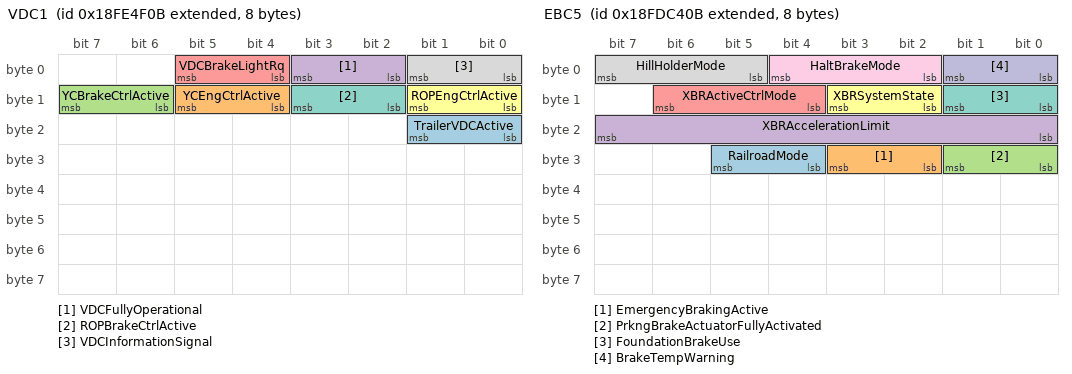
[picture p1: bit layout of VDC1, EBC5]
BO_ 2566803211 VDC1: 8 ESC_0B
 SG_ TrailerVDCActive : 16|2@1+ (1,0) [0|3] "" Vector__XXX
 SG_ YCEngCtrlActive : 12|2@1+ (1,0) [0|3] "" Vector__XXX
 SG_ YCBrakeCtrlActive : 14|2@1+ (1,0) [0|3] "" Vector__XXX
 SG_ VDCFullyOperational : 2|2@1+ (1,0) [0|3] "" Vector__XXX
 SG_ VDCBrakeLightRq : 4|2@1+ (1,0) [0|3] "" Vector__XXX
 SG_ ROPEngCtrlActive : 8|2@1+ (1,0) [0|3] "" Vector__XXX
 SG_ ROPBrakeCtrlActive : 10|2@1+ (1,0) [0|3] "" Vector__XXX
 SG_ VDCInformationSignal : 0|2@1+ (1,0) [0|3] "" Vector__XXX

BO_ 2298375691 FLR_HRW: 8 Vector__XXX
 SG_ RearAxleRightWheelSpeed : 48|16@1+ (0.00390625,0) [0|250.996] "kmph" Vector__XXX
 SG_ RearAxleLeftWheelSpeed : 32|16@1+ (0.00390625,0) [0|250.996] "kmph" Vector__XXX
 SG_ FrontAxleRightWheelSpeed : 16|16@1+ (0.00390625,0) [0|250.996] "kmph" Vector__XXX
 SG_ FrontAxleLeftWheelSpeed : 0|16@1+ (0.00390625,0) [0|250.996] "kmph" Vector__XXX

BO_ 2566767627 EBC5: 8 ESC_0B
 SG_ RailroadMode : 28|2@1+ (1,0) [0|3] "" Vector__XXX
 SG_ EmergencyBrakingActive : 26|2@1+ (1,0) [0|3] "" Vector__XXX
 SG_ PrkngBrakeActuatorFullyActivated : 24|2@1+ (1,0) [0|3] "" Vector__XXX
 SG_ XBRAccelerationLimit : 16|8@1+ (0.1,-12.5) [-10|10] "m/s�" Vector__XXX
 SG_ XBRActiveCtrlMode : 12|3@1+ (1,0) [0|15] "" Vector__XXX
 SG_ XBRSystemState : 10|2@1+ (1,0) [0|3] "" Vector__XXX
 SG_ FoundationBrakeUse : 8|2@1+ (1,0) [0|3] "" Vector__XXX
 SG_ HillHolderMode : 5|3@1+ (1,0) [0|7] "" Vector__XXX
 SG_ HaltBrakeMode : 2|3@1+ (1,0) [0|7] "" Vector__XXX
 SG_ BrakeTempWarning : 0|2@1+ (1,0) [0|3] "" Vector__XXX

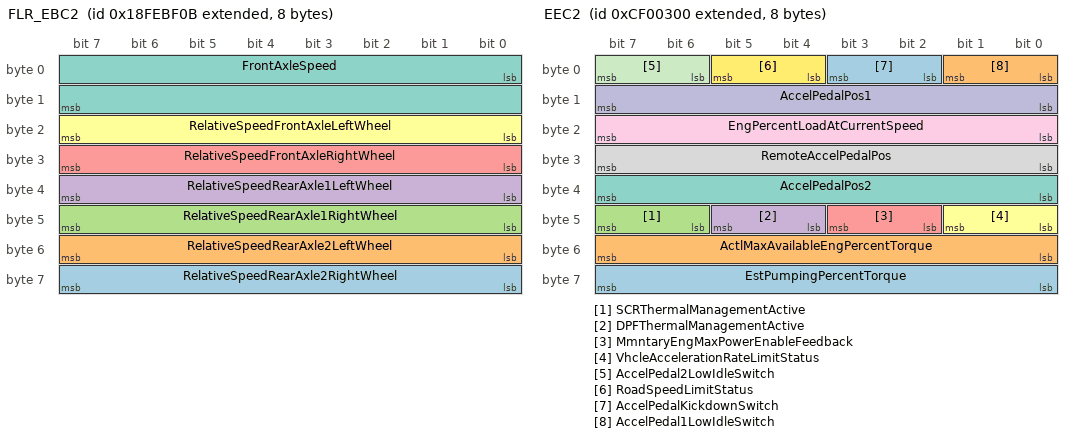
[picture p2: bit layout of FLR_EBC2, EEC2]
BO_ 2566831883 FLR_EBC2: 8 Vector__XXX
 SG_ RelativeSpeedRearAxle2RightWheel : 56|8@1+ (0.0625,-7.8125) [-7.8125|7.8125] "km/h" Vector__XXX
 SG_ RelativeSpeedRearAxle2LeftWheel : 48|8@1+ (0.0625,-7.8125) [-7.8125|7.8125] "km/h" Vector__XXX
 SG_ RelativeSpeedRearAxle1RightWheel : 40|8@1+ (0.0625,-7.8125) [-7.8125|7.8125] "kmph" Vector__XXX
 SG_ RelativeSpeedRearAxle1LeftWheel : 32|8@1+ (0.0625,-7.8125) [-7.8125|7.8125] "kmph" Vector__XXX
 SG_ RelativeSpeedFrontAxleRightWheel : 24|8@1+ (0.0625,-7.8125) [-7.8125|7.8125] "kmph" Vector__XXX
 SG_ RelativeSpeedFrontAxleLeftWheel : 16|8@1+ (0.0625,-7.8125) [-7.8125|7.8125] "kmph" Vector__XXX
 SG_ FrontAxleSpeed : 0|16@1+ (0.0039,0) [0|250.996] "kmph" Vector__XXX

BO_ 2565865739 FLR_EBC1: 8 Vector__XXX
 SG_ RailroadModeSw : 56|2@1+ (1,0) [0|3] "" Vector__XXX
 SG_ TrctrMntdTrailerABSWarningSignal : 62|2@1+ (1,0) [0|3] "" Vector__XXX
 SG_ TrailerABSStatus : 60|2@1+ (1,0) [0|3] "" Vector__XXX
 SG_ HaltBrakeSwitch : 58|2@1+ (1,0) [0|3] "" Vector__XXX
 SG_ SrcAddrssOfCntrllngDvcFrBrkeCtrl : 48|8@1+ (1,0) [0|253] "" Vector__XXX
 SG_ ATC_ASRInformationSignal : 46|2@1+ (1,0) [0|3] "" Vector__XXX
 SG_ ABS_EBSAmberWarningSignal : 44|2@1+ (1,0) [0|3] "" Vector__XXX
 SG_ EBSRedWarningSignal : 42|2@1+ (1,0) [0|3] "" Vector__XXX
 SG_ ABSFullyOperational : 40|2@1+ (1,0) [0|3] "" Vector__XXX
 SG_ EngRetarderSelection : 32|8@1+ (0.4,0) [0|100] "%" Vector__XXX
 SG_ RemoteAccelEnableSwitch : 30|2@1+ (1,0) [0|3] "" Vector__XXX
 SG_ EngAuxShutdownSwitch : 28|2@1+ (1,0) [0|3] "" Vector__XXX
 SG_ EngDerateSwitch : 26|2@1+ (1,0) [0|3] "" Vector__XXX
 SG_ AccelInterlockSwitch : 24|2@1+ (1,0) [0|3] "" Vector__XXX
 SG_ TractionCtrlOverrideSwitch : 22|2@1+ (1,0) [0|3] "" Vector__XXX
 SG_ ASRHillHolderSwitch : 20|2@1+ (1,0) [0|3] "" Vector__XXX
 SG_ ASROffroadSwitch : 18|2@1+ (1,0) [0|3] "" Vector__XXX
 SG_ ABSOffroadSwitch : 16|2@1+ (1,0) [0|3] "" Vector__XXX
 SG_ BrakePedalPos : 8|8@1+ (0.4,0) [0|100] "%" Vector__XXX
 SG_ EBSBrakeSwitch : 6|2@1+ (1,0) [0|3] "" Vector__XXX
 SG_ AntiLockBrakingActive : 4|2@1+ (1,0) [0|3] "" Vector__XXX
 SG_ ASRBrakeCtrlActive : 2|2@1+ (1,0) [0|3] "" Vector__XXX
 SG_ ASREngCtrlActive : 0|2@1+ (1,0) [0|3] "" Vector__XXX

BO_ 2565866752 FLR_ETC2_00: 8 FLR
 SG_ TransCurrentGear_00 : 24|8@1+ (1,-125) [-125|125] ""  SRR_RL,SRR_FL

BO_ 2565866755 FLR_ETC2_03: 8 FLR
 SG_ TransCurrentGear_03 : 24|8@1+ (1,-125) [-125|125] ""  SRR_RL,SRR_FL

BO_ 2364539648 EEC2: 8 EMS_00
 SG_ EstPumpingPercentTorque : 56|8@1+ (1,-125) [-125|125] "%" Vector__XXX
 SG_ ActlMaxAvailableEngPercentTorque : 48|8@1+ (0.4,0) [0|100] "%" Vector__XXX
 SG_ SCRThermalManagementActive : 46|2@1+ (1,0) [0|3] "" Vector__XXX
 SG_ DPFThermalManagementActive : 44|2@1+ (1,0) [0|3] "" Vector__XXX
 SG_ MmntaryEngMaxPowerEnableFeedback : 42|2@1+ (1,0) [0|3] "" Vector__XXX
 SG_ VhcleAccelerationRateLimitStatus : 40|2@1+ (1,0) [0|3] "" Vector__XXX
 SG_ AccelPedalPos2 : 32|8@1+ (0.4,0) [0|100] "%" Vector__XXX
 SG_ RemoteAccelPedalPos : 24|8@1+ (0.4,0) [0|100] "%" Vector__XXX
 SG_ EngPercentLoadAtCurrentSpeed : 16|8@1+ (1,0) [0|125] "%" Vector__XXX
 SG_ AccelPedalPos1 : 8|8@1+ (0.4,0) [0|100] "%" Vector__XXX
 SG_ AccelPedal2LowIdleSwitch : 6|2@1+ (1,0) [0|3] "" Vector__XXX
 SG_ RoadSpeedLimitStatus : 4|2@1+ (1,0) [0|3] "" Vector__XXX
 SG_ AccelPedalKickdownSwitch : 2|2@1+ (1,0) [0|3] "" Vector__XXX
 SG_ AccelPedal1LowIdleSwitch : 0|2@1+ (1,0) [0|3] "" Vector__XXX

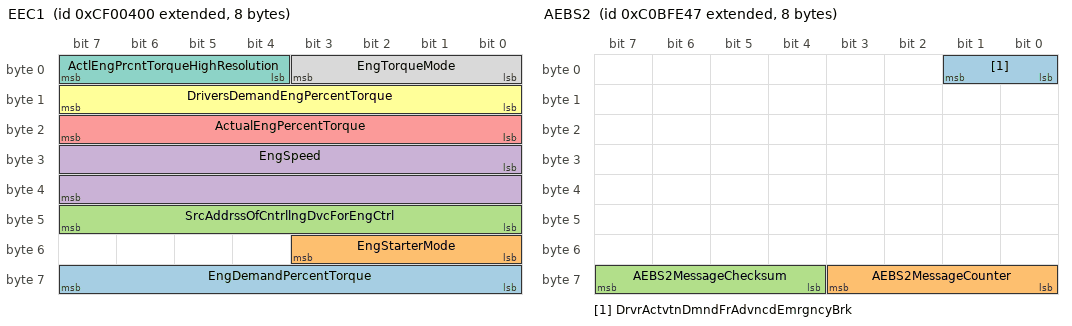
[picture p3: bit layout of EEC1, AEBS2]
BO_ 2364539904 EEC1: 8 EMS_00
 SG_ EngDemandPercentTorque : 56|8@1+ (1,-125) [-125|125] "%" Vector__XXX
 SG_ EngStarterMode : 48|4@1+ (1,0) [0|15] "" Vector__XXX
 SG_ SrcAddrssOfCntrllngDvcForEngCtrl : 40|8@1+ (1,0) [0|253] "" Vector__XXX
 SG_ EngSpeed : 24|16@1+ (0.125,0) [0|8031.875] "rpm" Vector__XXX
 SG_ ActualEngPercentTorque : 16|8@1+ (1,-125) [0|125] "%" Vector__XXX
 SG_ DriversDemandEngPercentTorque : 8|8@1+ (1,-125) [0|125] "%" Vector__XXX
 SG_ ActlEngPrcntTorqueHighResolution : 4|4@1+ (0.125,0) [0|0.875] "%" Vector__XXX
 SG_ EngTorqueMode : 0|4@1+ (1,0) [0|15] "" Vector__XXX

BO_ 2566844672 FLR_CCVS1: 8 FLR
 SG_ FLR_BrakeSwitch : 28|2@1+ (1,0) [0|3] ""  SRR_RL,SRR_FL
 SG_ FLR_WheelBasedVehicleSpeed : 8|16@1+ (0.00390625,0) [0|250.99609375] "km/h"  SRR_RL,SRR_FL
 SG_ FLR_ParkingBrakeSwitch : 2|2@1+ (1,0) [0|3] ""  SRR_RL,SRR_FL

BO_ 2566769991 OWW: 8 VCU_47
 SG_ FrontOperatorWiperSwitch : 4|4@1+ (1,0) [0|15] "state" Vector__XXX

BO_ 2561277511 FLIC: 8 VCU_47
 SG_ LaneDepartureWarningEnableCmd : 0|2@1+ (1,0) [0|3] "" Vector__XXX

BO_ 2349596231 AEBS2: 8 VCU_47
 SG_ DrvrActvtnDmndFrAdvncdEmrgncyBrk : 0|2@1+ (1,0) [0|3] "" Vector__XXX
 SG_ AEBS2MessageCounter : 56|4@1+ (1,0) [0|15] "" Vector__XXX
 SG_ AEBS2MessageChecksum : 60|4@1+ (1,0) [0|15] "" Vector__XXX

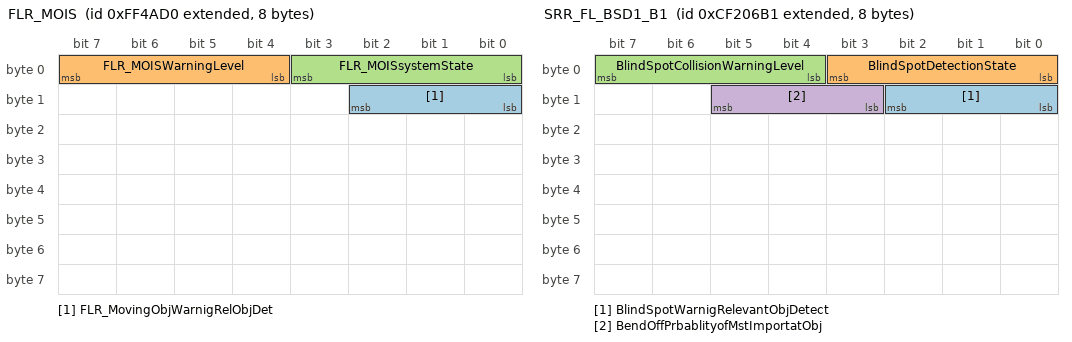
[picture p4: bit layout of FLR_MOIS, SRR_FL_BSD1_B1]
BO_ 2164214480 FLR_MOIS: 8 Vector__XXX
 SG_ FLR_MovingObjWarnigRelObjDet : 8|3@1+ (1,0) [0|7] "" Vector__XXX
 SG_ FLR_MOISWarningLevel : 4|4@1+ (1,0) [0|15] "" Vector__XXX
 SG_ FLR_MOISsystemState : 0|4@1+ (1,0) [0|15] "" Vector__XXX

BO_ 2364671665 SRR_FL_BSD1_B1: 8 Vector__XXX
 SG_ BlindSpotWarnigRelevantObjDetect : 8|3@1+ (1,0) [0|7] "" Vector__XXX
 SG_ BlindSpotDetectionState : 0|4@1+ (1,0) [0|15] "" Vector__XXX
 SG_ BlindSpotCollisionWarningLevel : 4|4@1+ (1,0) [0|15] "" Vector__XXX
 SG_ BendOffPrbablityofMstImportatObj : 11|3@1+ (1,0) [0|7] "" Vector__XXX

BO_ 2364671664 SRR_RL_BSD1_B0: 8 SRR_RL
 SG_ BlindSpotDetectionState : 0|4@1+ (1,0) [0|15] ""  FLR
 SG_ BlindSpotCollisionWarningLevel : 4|4@1+ (1,0) [0|15] ""  FLR

BO_ 2566890672 SRR_RL_prop_ADAS_BSIS_info: 8 SRR_RL
 SG_ BlindSpotDetectionState : 0|4@1+ (1,0) [0|15] ""  FLR
 SG_ BlindSpotCollisionWarningLevel : 4|4@1+ (1,0) [0|15] ""  FLR

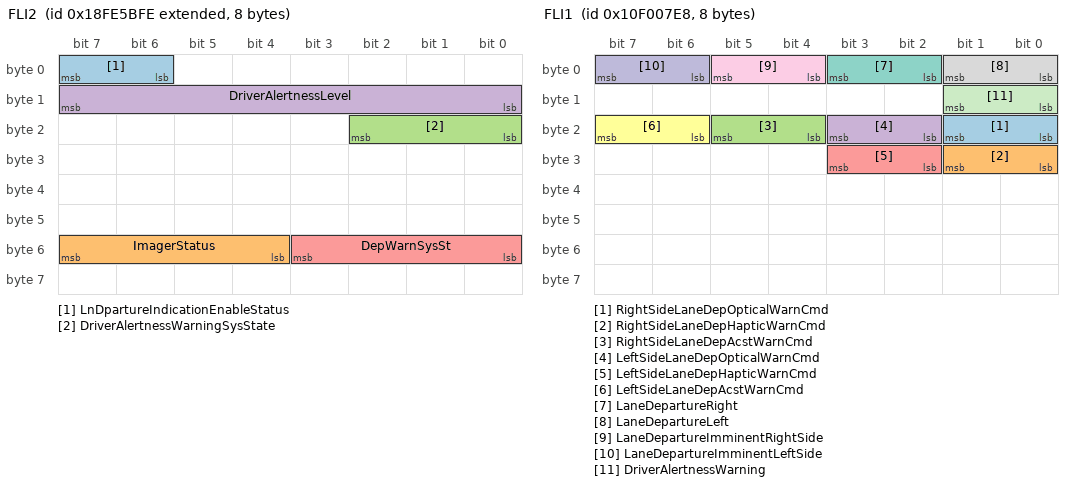
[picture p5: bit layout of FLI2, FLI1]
BO_ 2566806526 FLI2: 8 Vector__XXX
 SG_ LnDpartureIndicationEnableStatus : 6|2@1+ (1,0) [0|3] "" Vector__XXX
 SG_ ImagerStatus : 52|4@1+ (1,0) [0|15] "" Vector__XXX
 SG_ DriverAlertnessWarningSysState : 16|3@1+ (1,0) [0|7] "state" Vector__XXX
 SG_ DriverAlertnessLevel : 8|8@1+ (0.4,0) [0|100] "%" Vector__XXX
 SG_ DepWarnSysSt : 48|4@1+ (1,0) [0|15] "" Vector__XXX

BO_ 284166120 FLI1: 8 Vector__XXX
 SG_ RightSideLaneDepOpticalWarnCmd : 16|2@1+ (1,0) [0|3] "" Vector__XXX
 SG_ RightSideLaneDepHapticWarnCmd : 24|2@1+ (1,0) [0|3] "" Vector__XXX
 SG_ RightSideLaneDepAcstWarnCmd : 20|2@1+ (1,0) [0|3] "" Vector__XXX
 SG_ LeftSideLaneDepOpticalWarnCmd : 18|2@1+ (1,0) [0|3] "" Vector__XXX
 SG_ LeftSideLaneDepHapticWarnCmd : 26|2@1+ (1,0) [0|3] "" Vector__XXX
 SG_ LeftSideLaneDepAcstWarnCmd : 22|2@1+ (1,0) [0|3] "" Vector__XXX
 SG_ LaneDepartureRight : 2|2@1+ (1,0) [0|3] "" Vector__XXX
 SG_ LaneDepartureLeft : 0|2@1+ (1,0) [0|3] "" Vector__XXX
 SG_ LaneDepartureImminentRightSide : 4|2@1+ (1,0) [0|3] "" Vector__XXX
 SG_ LaneDepartureImminentLeftSide : 6|2@1+ (1,0) [0|3] "" Vector__XXX
 SG_ DriverAlertnessWarning : 8|2@1+ (1,0) [0|3] "" Vector__XXX

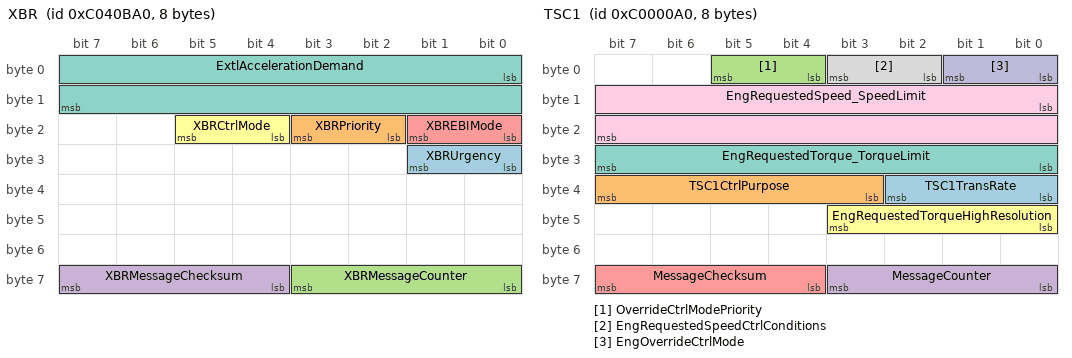
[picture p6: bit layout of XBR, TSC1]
BO_ 201591712 XBR: 8 Vector__XXX
 SG_ XBRUrgency : 24|2@1+ (0.4,0) [0|100] "%"  ESC_0B
 SG_ XBRPriority : 18|2@1+ (1,0) [0|3] "state"  ESC_0B
 SG_ XBRMessageCounter : 56|4@1+ (1,0) [0|15] "count"  ESC_0B
 SG_ XBRMessageChecksum : 60|4@1+ (1,0) [0|15] "count"  ESC_0B
 SG_ XBREBIMode : 16|2@1+ (1,0) [0|3] "state"  ESC_0B
 SG_ XBRCtrlMode : 20|2@1+ (1,0) [0|3] "state"  ESC_0B
 SG_ ExtlAccelerationDemand : 0|16@1+ (0.00048828125,-15.687) [-15.687|15.687511719] "m/s�"  ESC_0B

BO_ 201326752 TSC1: 8 Vector__XXX
 SG_ TSC1TransRate : 32|3@1+ (1,0) [0|7] "state"  EMS_00
 SG_ TSC1CtrlPurpose : 35|5@1+ (1,0) [0|31] "state"  EMS_00
 SG_ OverrideCtrlModePriority : 4|2@1+ (1,0) [0|3] "state"  EMS_00
 SG_ MessageCounter : 56|4@1+ (1,0) [0|15] "count"  EMS_00
 SG_ MessageChecksum : 60|4@1+ (1,0) [0|15] "count"  EMS_00
 SG_ EngRequestedTorqueHighResolution : 40|4@1+ (0.125,0) [0|1.625] "%"  EMS_00
 SG_ EngRequestedTorque_TorqueLimit : 24|8@1+ (1,-125) [-125|125] "%"  EMS_00
 SG_ EngRequestedSpeedCtrlConditions : 2|2@1+ (1,0) [0|3] "state"  EMS_00
 SG_ EngRequestedSpeed_SpeedLimit : 8|16@1+ (0.125,0) [0|8031.875] "rpm"  EMS_00
 SG_ EngOverrideCtrlMode : 0|2@1+ (1,0) [0|3] "state"  EMS_00

BO_ 201457568 TC1: 8 Vector__XXX
 SG_ AutoNeutralReq : 48|2@1+ (1,0) [0|3] "" Vector__XXX
 SG_ TransMode8 : 62|2@1+ (1,0) [0|3] "" Vector__XXX
 SG_ TransMode7 : 60|2@1+ (1,0) [0|3] "" Vector__XXX
 SG_ TransMode6 : 58|2@1+ (1,0) [0|3] "" Vector__XXX
 SG_ TransMode5 : 56|2@1+ (1,0) [0|3] "" Vector__XXX
 SG_ TrnsShftSlectorDisplayModeSwitch : 54|2@1+ (1,0) [0|3] "" Vector__XXX
 SG_ TransRequestedLaunchGear : 50|4@1+ (1,0) [0|15] "" Vector__XXX
 SG_ TransMode4 : 46|2@1+ (1,0) [0|3] "" Vector__XXX
 SG_ TransMode3 : 44|2@1+ (1,0) [0|3] "" Vector__XXX
 SG_ TransMode2 : 42|2@1+ (1,0) [0|3] "" Vector__XXX
 SG_ TransMode1 : 40|2@1+ (1,0) [0|3] "" Vector__XXX
 SG_ TransLoadReductionInhibitRq : 38|2@1+ (1,0) [0|3] "" Vector__XXX
 SG_ DisengageDiffLockRqCentralRear : 36|2@1+ (1,0) [0|3] "" Vector__XXX
 SG_ DisengageDiffLockRqCentralFront : 34|2@1+ (1,0) [0|3] "" Vector__XXX
 SG_ DisengageDiffLockRqCentral : 32|2@1+ (1,0) [0|3] "" Vector__XXX
 SG_ DisengageDiffLockRqRearAxle2 : 30|2@1+ (1,0) [0|3] "" Vector__XXX
 SG_ DisengageDiffLockRqRearAxle1 : 28|2@1+ (1,0) [0|3] "" Vector__XXX
 SG_ DisengageDiffLockRqFrontAxle2 : 26|2@1+ (1,0) [0|3] "" Vector__XXX
 SG_ DisengageDiffLockRqFrontAxle1 : 24|2@1+ (1,0) [0|3] "" Vector__XXX
 SG_ TransRequestedGear : 16|8@1+ (1,-125) [-64|64] "" Vector__XXX
 SG_ RequestedPercentClutchSlip : 8|8@1+ (0.4,0) [0|100] "%" Vector__XXX
 SG_ TransReverseGearShiftInhibitRq : 6|2@1+ (1,0) [0|3] "" Vector__XXX
 SG_ DisengageDrivelineRq : 4|2@1+ (1,0) [0|3] "" Vector__XXX
 SG_ TrnsTrqeConverterLockupDisableRq : 2|2@1+ (1,0) [0|3] "" Vector__XXX
 SG_ TransGearShiftInhibitRq : 0|2@1+ (1,0) [0|3] "" Vector__XXX

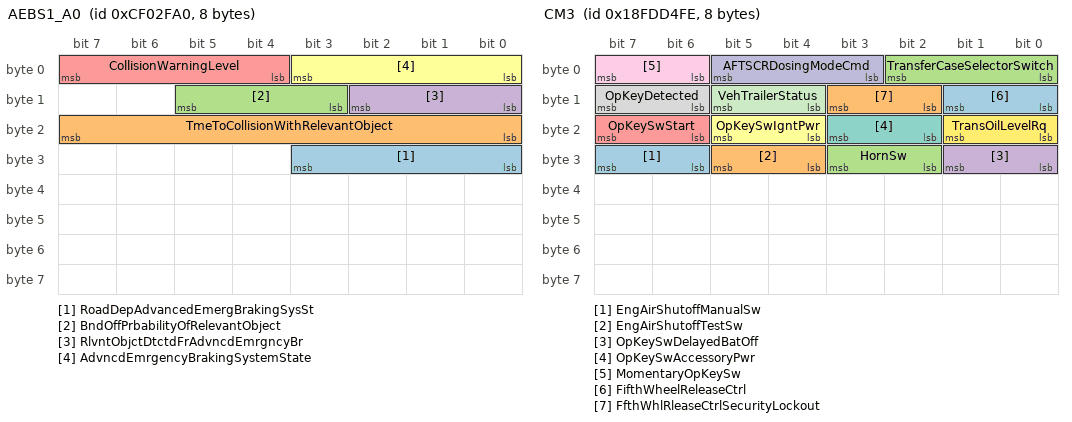
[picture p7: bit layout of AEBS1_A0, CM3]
BO_ 217067424 AEBS1_A0: 8 Vector__XXX
 SG_ RoadDepAdvancedEmergBrakingSysSt : 24|4@1+ (1,0) [0|15] "" Vector__XXX
 SG_ TmeToCollisionWithRelevantObject : 16|8@1+ (0.05,0) [0|12.5] "second" Vector__XXX
 SG_ BndOffPrbabilityOfRelevantObject : 11|3@1+ (1,0) [0|7] "" Vector__XXX
 SG_ RlvntObjctDtctdFrAdvncdEmrgncyBr : 8|3@1+ (1,0) [0|7] "" Vector__XXX
 SG_ CollisionWarningLevel : 4|4@1+ (1,0) [0|15] "state" Vector__XXX
 SG_ AdvncdEmrgencyBrakingSystemState : 0|4@1+ (1,0) [0|15] "state" Vector__XXX

BO_ 419288318 CM3: 8 Vector__XXX
 SG_ EngAirShutoffManualSw : 30|2@1+ (1,0) [0|3] "" Vector__XXX
 SG_ EngAirShutoffTestSw : 28|2@1+ (1,0) [0|3] "" Vector__XXX
 SG_ HornSw : 26|2@1+ (1,0) [0|3] "" Vector__XXX
 SG_ OpKeySwDelayedBatOff : 24|2@1+ (1,0) [0|3] "" Vector__XXX
 SG_ OpKeySwStart : 22|2@1+ (1,0) [0|3] "" Vector__XXX
 SG_ OpKeySwIgntPwr : 20|2@1+ (1,0) [0|3] "" Vector__XXX
 SG_ OpKeySwAccessoryPwr : 18|2@1+ (1,0) [0|3] "" Vector__XXX
 SG_ OpKeyDetected : 14|2@1+ (1,0) [0|3] "" Vector__XXX
 SG_ MomentaryOpKeySw : 6|2@1+ (1,0) [0|3] "" Vector__XXX
 SG_ AFTSCRDosingModeCmd : 3|3@1+ (1,0) [0|7] "" Vector__XXX
 SG_ VehTrailerStatus : 12|2@1+ (1,0) [0|3] "" Vector__XXX
 SG_ TransOilLevelRq : 16|2@1+ (1,0) [0|3] "" Vector__XXX
 SG_ FifthWheelReleaseCtrl : 8|2@1+ (1,0) [0|3] "" Vector__XXX
 SG_ FfthWhlRleaseCtrlSecurityLockout : 10|2@1+ (1,0) [0|3] "" Vector__XXX
 SG_ TransferCaseSelectorSwitch : 0|3@1+ (1,0) [0|7] "" Vector__XXX

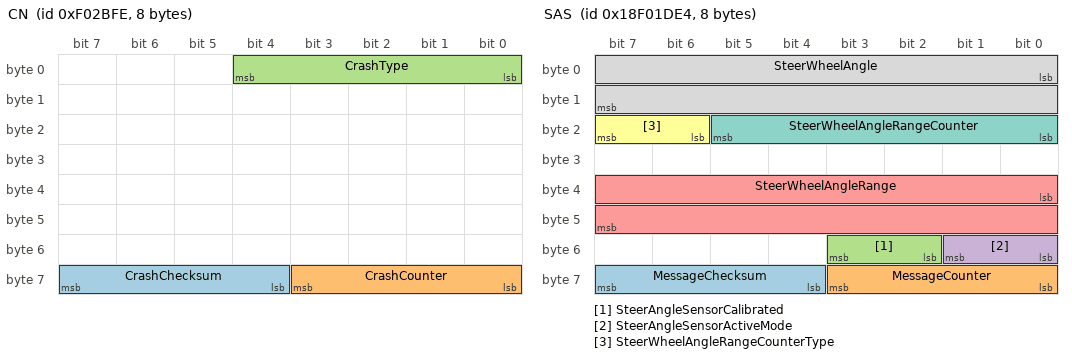
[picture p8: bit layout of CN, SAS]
BO_ 15739902 CN: 8 Vector__XXX
 SG_ CrashChecksum : 60|4@1+ (1,0) [0|15] "" Vector__XXX
 SG_ CrashCounter : 56|4@1+ (1,0) [0|15] "" Vector__XXX
 SG_ CrashType : 0|5@1+ (1,0) [0|0] "" Vector__XXX

BO_ 418389476 SAS: 8 Steering_E4
 SG_ MessageChecksum : 60|4@1+ (1,0) [0|15] "" Vector__XXX
 SG_ MessageCounter : 56|4@1+ (1,0) [0|15] "" Vector__XXX
 SG_ SteerAngleSensorCalibrated : 50|2@1+ (1,0) [0|3] "" Vector__XXX
 SG_ SteerAngleSensorActiveMode : 48|2@1+ (1,0) [0|3] "" Vector__XXX
 SG_ SteerWheelAngleRange : 32|16@1+ (0.0009765625,-31.374) [0|31.374] "rad" Vector__XXX
 SG_ SteerWheelAngleRangeCounterType : 22|2@1+ (1,0) [0|3] "" Vector__XXX
 SG_ SteerWheelAngleRangeCounter : 16|6@1+ (1,-32) [-32|29] "ranges" Vector__XXX
 SG_ SteerWheelAngle : 0|16@1+ (0.0009765625,-31.374) [-31.374|31.374] "rad" Vector__XXX

BO_ 419276286 DC2: 8 Vector__XXX
 SG_ EnableStatusOfDoor10 : 58|2@1+ (1,0) [0|3] "" Vector__XXX
 SG_ OpenStatusOfDoor10 : 56|2@1+ (1,0) [0|3] "" Vector__XXX
 SG_ LockStatusOfDoor10 : 54|2@1+ (1,0) [0|3] "" Vector__XXX
 SG_ EnableStatusOfDoor9 : 52|2@1+ (1,0) [0|3] "" Vector__XXX
 SG_ OpenStatusOfDoor9 : 50|2@1+ (1,0) [0|3] "" Vector__XXX
 SG_ LockStatusOfDoor9 : 48|2@1+ (1,0) [0|3] "" Vector__XXX
 SG_ EnableStatusOfDoor8 : 46|2@1+ (1,0) [0|3] "" Vector__XXX
 SG_ OpenStatusOfDoor8 : 44|2@1+ (1,0) [0|3] "" Vector__XXX
 SG_ LockStatusOfDoor8 : 42|2@1+ (1,0) [0|3] "" Vector__XXX
 SG_ EnableStatusOfDoor7 : 40|2@1+ (1,0) [0|3] "" Vector__XXX
 SG_ OpenStatusOfDoor7 : 38|2@1+ (1,0) [0|3] "" Vector__XXX
 SG_ LockStatusOfDoor7 : 36|2@1+ (1,0) [0|3] "" Vector__XXX
 SG_ EnableStatusOfDoor6 : 34|2@1+ (1,0) [0|3] "" Vector__XXX
 SG_ OpenStatusOfDoor6 : 32|2@1+ (1,0) [0|3] "" Vector__XXX
 SG_ LockStatusOfDoor6 : 30|2@1+ (1,0) [0|3] "" Vector__XXX
 SG_ EnableStatusOfDoor5 : 28|2@1+ (1,0) [0|3] "" Vector__XXX
 SG_ OpenStatusOfDoor5 : 26|2@1+ (1,0) [0|3] "" Vector__XXX
 SG_ LockStatusOfDoor5 : 24|2@1+ (1,0) [0|3] "" Vector__XXX
 SG_ EnableStatusOfDoor4 : 22|2@1+ (1,0) [0|3] "" Vector__XXX
 SG_ OpenStatusOfDoor4 : 20|2@1+ (1,0) [0|3] "" Vector__XXX
 SG_ LockStatusOfDoor4 : 18|2@1+ (1,0) [0|3] "" Vector__XXX
 SG_ EnableStatusOfDoor3 : 16|2@1+ (1,0) [0|3] "" Vector__XXX
 SG_ OpenStatusOfDoor3 : 14|2@1+ (1,0) [0|3] "" Vector__XXX
 SG_ LockStatusOfDoor3 : 12|2@1+ (1,0) [0|3] "" Vector__XXX
 SG_ EnableStatusOfDoor2 : 10|2@1+ (1,0) [0|3] "" Vector__XXX
 SG_ OpenStatusOfDoor2 : 8|2@1+ (1,0) [0|3] "" Vector__XXX
 SG_ LockStatusOfDoor2 : 6|2@1+ (1,0) [0|3] "" Vector__XXX
 SG_ EnableStatusOfDoor1 : 4|2@1+ (1,0) [0|3] "" Vector__XXX
 SG_ OpenStatusOfDoor1 : 2|2@1+ (1,0) [0|3] "" Vector__XXX
 SG_ LockStatusOfDoor1 : 0|2@1+ (1,0) [0|3] "" Vector__XXX

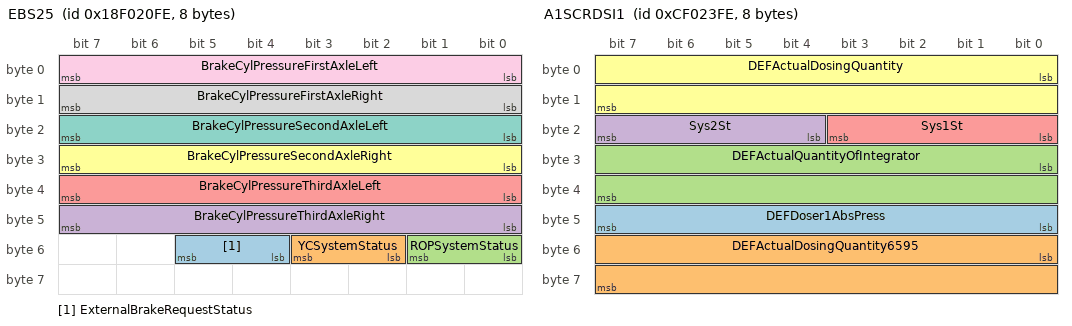
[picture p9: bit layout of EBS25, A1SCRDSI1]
BO_ 418390270 EBS25: 8 Vector__XXX
 SG_ ExternalBrakeRequestStatus : 52|2@1+ (1,0) [0|3] "" Vector__XXX
 SG_ YCSystemStatus : 50|2@1+ (1,0) [0|3] "" Vector__XXX
 SG_ ROPSystemStatus : 48|2@1+ (1,0) [0|3] "" Vector__XXX
 SG_ BrakeCylPressureThirdAxleRight : 40|8@1+ (5,0) [0|1250] "kPa" Vector__XXX
 SG_ BrakeCylPressureThirdAxleLeft : 32|8@1+ (5,0) [0|1250] "kPa" Vector__XXX
 SG_ BrakeCylPressureSecondAxleRight : 24|8@1+ (5,0) [0|1250] "kPa" Vector__XXX
 SG_ BrakeCylPressureSecondAxleLeft : 16|8@1+ (5,0) [0|1250] "kPa" Vector__XXX
 SG_ BrakeCylPressureFirstAxleRight : 8|8@1+ (5,0) [0|1250] "kPa" Vector__XXX
 SG_ BrakeCylPressureFirstAxleLeft : 0|8@1+ (5,0) [0|1250] "kPa" Vector__XXX

BO_ 217064446 A1SCRDSI1: 8 Vector__XXX
 SG_ DEFDoser1AbsPress : 40|8@1+ (8,0) [0|2000] "kPa" Vector__XXX
 SG_ DEFActualDosingQuantity6595 : 48|16@1+ (0.05,0) [0|3212.75] "g/min" Vector__XXX
 SG_ DEFActualQuantityOfIntegrator : 24|16@1+ (0.1,0) [0|6425.5] "g" Vector__XXX
 SG_ Sys2St : 20|4@1+ (1,0) [0|15] "" Vector__XXX
 SG_ Sys1St : 16|4@1+ (1,0) [0|15] "" Vector__XXX
 SG_ DEFActualDosingQuantity : 0|16@1+ (0.3,0) [0|19276.5] "g/h" Vector__XXX

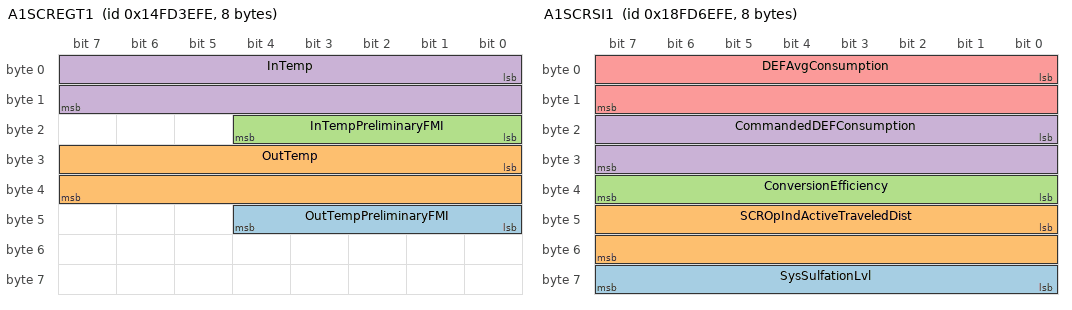
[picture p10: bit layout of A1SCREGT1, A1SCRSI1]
BO_ 352141054 A1SCREGT1: 8 Vector__XXX
 SG_ OutTempPreliminaryFMI : 40|5@1+ (1,0) [0|31] "" Vector__XXX
 SG_ OutTemp : 24|16@1+ (0.03125,-273) [-273|1734.96875] "�C" Vector__XXX
 SG_ InTempPreliminaryFMI : 16|5@1+ (1,0) [0|31] "" Vector__XXX
 SG_ InTemp : 0|16@1+ (0.03125,-273) [-273|1734.96875] "�C" Vector__XXX

BO_ 419262206 A1SCRSI1: 8 Vector__XXX
 SG_ SysSulfationLvl : 56|8@1+ (1,0) [0|250] "%" Vector__XXX
 SG_ SCROpIndActiveTraveledDist : 40|16@1+ (1,0) [0|64255] "km" Vector__XXX
 SG_ ConversionEfficiency : 32|8@1+ (0.4,0) [0|100] "%" Vector__XXX
 SG_ CommandedDEFConsumption : 16|16@1+ (0.05,0) [0|3212.75] "l/h" Vector__XXX
 SG_ DEFAvgConsumption : 0|16@1+ (0.05,0) [0|3212.75] "l/h" Vector__XXX

BO_ 419172606 AMB3: 8 Vector__XXX
 SG_ EngPwrDerateRelHumidityDiff : 24|16@1+ (0.01,-321.27) [-100|100] "%" Vector__XXX
 SG_ EngIn2AirTemp : 16|8@1+ (1,-40) [-40|210] "�C" Vector__XXX
 SG_ BarometricAbsPress2 : 0|16@1+ (0.1,0) [0|6425.5] "kPa" Vector__XXX

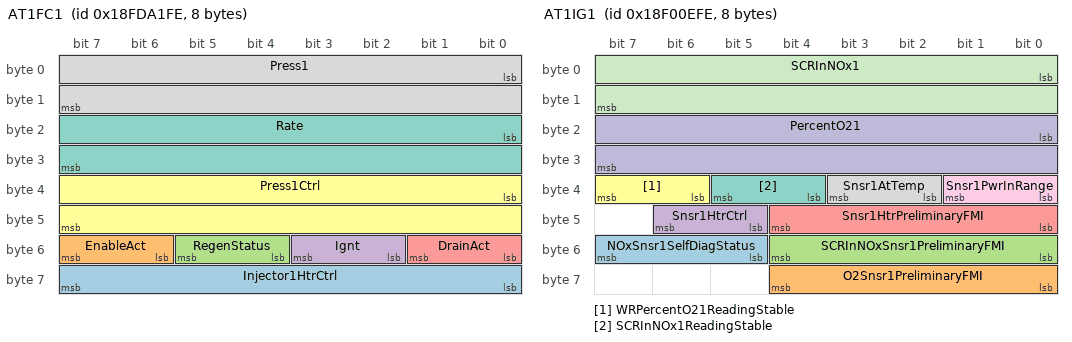
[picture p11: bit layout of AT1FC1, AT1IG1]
BO_ 419275262 AT1FC1: 8 Vector__XXX
 SG_ Injector1HtrCtrl : 56|8@1+ (0.4,0) [0|100] "%" Vector__XXX
 SG_ EnableAct : 54|2@1+ (1,0) [0|3] "" Vector__XXX
 SG_ RegenStatus : 52|2@1+ (1,0) [0|3] "" Vector__XXX
 SG_ Ignt : 50|2@1+ (1,0) [0|3] "" Vector__XXX
 SG_ DrainAct : 48|2@1+ (1,0) [0|3] "" Vector__XXX
 SG_ Press1Ctrl : 32|16@1+ (0.0025,0) [0|160.6375] "%" Vector__XXX
 SG_ Rate : 16|16@1+ (0.05,0) [0|3212.75] "l/h" Vector__XXX
 SG_ Press1 : 0|16@1+ (0.1,0) [0|6425.5] "kPa" Vector__XXX

BO_ 419272958 AT1HI1: 8 Vector__XXX
 SG_ DPFAvgDistBetweenActiveRegens : 288|32@1+ (0.125,0) [0|526385151.88] "km" Vector__XXX
 SG_ DPFAvgTimeBetweenActiveRegens : 256|32@1+ (1,0) [0|4211081215] "s" Vector__XXX
 SG_ DPFTotalNumOfActiveRegenManReq : 224|32@1+ (1,0) [0|4211081215] "" Vector__XXX
 SG_ DPFTotalNumOfActiveRegenInhReq : 192|32@1+ (1,0) [0|4211081215] "" Vector__XXX
 SG_ DPFTotalNumOfPassiveRegens : 160|32@1+ (1,0) [0|4211081215] "" Vector__XXX
 SG_ DPFTotalPassiveRegenTime : 128|32@1+ (1,0) [0|4211081215] "s" Vector__XXX
 SG_ TotalNumOfActiveRegens : 96|32@1+ (1,0) [0|4211081215] "" Vector__XXX
 SG_ TotalDisabledTime : 64|32@1+ (1,0) [0|4211081215] "s" Vector__XXX
 SG_ TotalRegenTime : 32|32@1+ (1,0) [0|4211081215] "s" Vector__XXX
 SG_ TotalFuelUsed : 0|32@1+ (0.5,0) [0|2105540607.5] "l" Vector__XXX

BO_ 418385662 AT1IG1: 8 Vector__XXX
 SG_ NOxSnsr1SelfDiagStatus : 53|3@1+ (1,0) [0|7] "" Vector__XXX
 SG_ O2Snsr1PreliminaryFMI : 56|5@1+ (1,0) [0|31] "" Vector__XXX
 SG_ SCRInNOxSnsr1PreliminaryFMI : 48|5@1+ (1,0) [0|31] "" Vector__XXX
 SG_ Snsr1HtrCtrl : 45|2@1+ (1,0) [0|3] "" Vector__XXX
 SG_ Snsr1HtrPreliminaryFMI : 40|5@1+ (1,0) [0|31] "" Vector__XXX
 SG_ WRPercentO21ReadingStable : 38|2@1+ (1,0) [0|3] "" Vector__XXX
 SG_ SCRInNOx1ReadingStable : 36|2@1+ (1,0) [0|3] "" Vector__XXX
 SG_ Snsr1AtTemp : 34|2@1+ (1,0) [0|3] "" Vector__XXX
 SG_ Snsr1PwrInRange : 32|2@1+ (1,0) [0|3] "" Vector__XXX
 SG_ PercentO21 : 16|16@1+ (0.000514,-12) [-12|21.02707] "%" Vector__XXX
 SG_ SCRInNOx1 : 0|16@1+ (0.05,-200) [-200|3012.75] "ppm" Vector__XXX

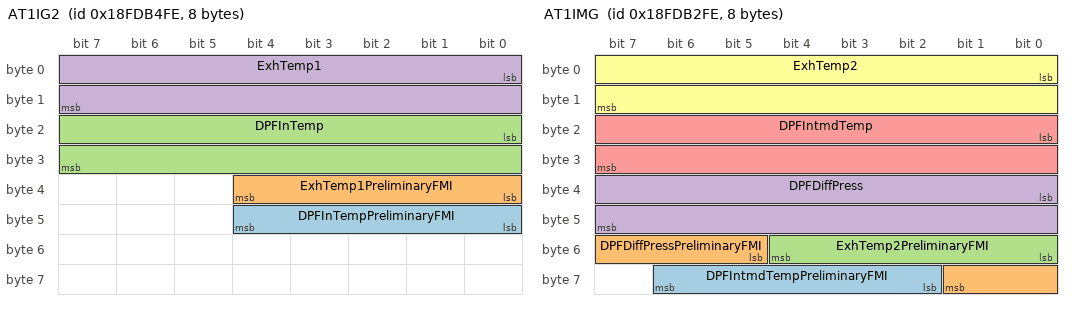
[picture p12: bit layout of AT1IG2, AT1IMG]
BO_ 419280126 AT1IG2: 8 Vector__XXX
 SG_ DPFInTempPreliminaryFMI : 40|5@1+ (1,0) [0|31] "" Vector__XXX
 SG_ ExhTemp1PreliminaryFMI : 32|5@1+ (1,0) [0|31] "" Vector__XXX
 SG_ DPFInTemp : 16|16@1+ (0.03125,-273) [-273|1734.96875] "�C" Vector__XXX
 SG_ ExhTemp1 : 0|16@1+ (0.03125,-273) [-273|1734.96875] "�C" Vector__XXX

BO_ 217911806 AT1IGC1: 8 Vector__XXX
 SG_ NOxSnsrOpHours : 40|16@1+ (1,0) [0|64255] "h" Vector__XXX
 SG_ NOxSnsrNewPartDeviationNOxOffset : 32|8@1+ (1,-125) [-125|125] "ppm" Vector__XXX
 SG_ NOxSnsrNewPartDeviationNOxGain : 16|16@1+ (0.1,-100) [-100|100] "%" Vector__XXX
 SG_ NOxSnsrHtrRatio : 0|16@1+ (0.001,0) [0|64.255] "" Vector__XXX

BO_ 419279614 AT1IMG: 8 Vector__XXX
 SG_ DPFIntmdTempPreliminaryFMI : 58|5@1+ (1,0) [0|31] "" Vector__XXX
 SG_ DPFDiffPressPreliminaryFMI : 53|5@1+ (1,0) [0|31] "" Vector__XXX
 SG_ ExhTemp2PreliminaryFMI : 48|5@1+ (1,0) [0|31] "" Vector__XXX
 SG_ DPFDiffPress : 32|16@1+ (0.1,0) [0|6425.5] "kPa" Vector__XXX
 SG_ DPFIntmdTemp : 16|16@1+ (0.03125,-273) [-273|1734.96875] "�C" Vector__XXX
 SG_ ExhTemp2 : 0|16@1+ (0.03125,-273) [-273|1734.96875] "�C" Vector__XXX

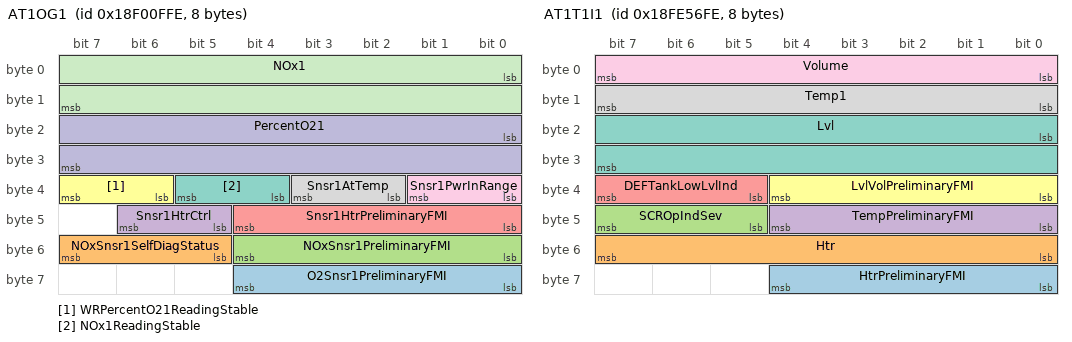
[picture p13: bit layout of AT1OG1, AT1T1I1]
BO_ 418385918 AT1OG1: 8 Vector__XXX
 SG_ O2Snsr1PreliminaryFMI : 56|5@1+ (1,0) [0|31] "" Vector__XXX
 SG_ NOxSnsr1SelfDiagStatus : 53|3@1+ (1,0) [0|7] "" Vector__XXX
 SG_ NOxSnsr1PreliminaryFMI : 48|5@1+ (1,0) [0|31] "" Vector__XXX
 SG_ Snsr1HtrCtrl : 45|2@1+ (1,0) [0|3] "" Vector__XXX
 SG_ Snsr1HtrPreliminaryFMI : 40|5@1+ (1,0) [0|31] "" Vector__XXX
 SG_ WRPercentO21ReadingStable : 38|2@1+ (1,0) [0|3] "" Vector__XXX
 SG_ NOx1ReadingStable : 36|2@1+ (1,0) [0|3] "" Vector__XXX
 SG_ Snsr1AtTemp : 34|2@1+ (1,0) [0|3] "" Vector__XXX
 SG_ Snsr1PwrInRange : 32|2@1+ (1,0) [0|3] "" Vector__XXX
 SG_ PercentO21 : 16|16@1+ (0.000514,-12) [-12|21.02707] "%" Vector__XXX
 SG_ NOx1 : 0|16@1+ (0.05,-200) [-200|3012.75] "ppm" Vector__XXX

BO_ 217911294 AT1OGC1: 8 Vector__XXX
 SG_ NOxSnsrOpHours : 40|16@1+ (1,0) [0|64255] "h" Vector__XXX
 SG_ NOxSnsrNewPartDeviationNOxOffset : 32|8@1+ (1,-125) [-125|125] "ppm" Vector__XXX
 SG_ NOxSnsrNewPartDeviationNOxGain : 16|16@1+ (0.1,-100) [-100|100] "%" Vector__XXX
 SG_ NOxSnsrHtrRatio : 0|16@1+ (0.001,0) [0|64.255] "" Vector__XXX

BO_ 419265534 AT1S1: 8 Vector__XXX
 SG_ DPFSootLoadRegenThreshold : 48|16@1+ (0.0025,0) [0|160.6375] "%" Vector__XXX
 SG_ DPFTimeSinceLastActiveRegen : 16|32@1+ (1,0) [0|4211081215] "s" Vector__XXX
 SG_ DPFAshLoadPercent : 8|8@1+ (1,0) [0|250] "%" Vector__XXX
 SG_ DPFSootLoadPercent : 0|8@1+ (1,0) [0|250] "%" Vector__XXX

BO_ 419321598 AT1T1I1: 8 Vector__XXX
 SG_ HtrPreliminaryFMI : 56|5@1+ (1,0) [0|31] "" Vector__XXX
 SG_ Htr : 48|8@1+ (0.4,0) [0|100] "%" Vector__XXX
 SG_ SCROpIndSev : 45|3@1+ (1,0) [0|7] "" Vector__XXX
 SG_ TempPreliminaryFMI : 40|5@1+ (1,0) [0|31] "" Vector__XXX
 SG_ DEFTankLowLvlInd : 37|3@1+ (1,0) [0|7] "" Vector__XXX
 SG_ LvlVolPreliminaryFMI : 32|5@1+ (1,0) [0|31] "" Vector__XXX
 SG_ Lvl : 16|16@1+ (0.1,0) [0|6425.5] "mm" Vector__XXX
 SG_ Temp1 : 8|8@1+ (1,-40) [-40|210] "�C" Vector__XXX
 SG_ Volume : 0|8@1+ (0.4,0) [0|100] "%" Vector__XXX

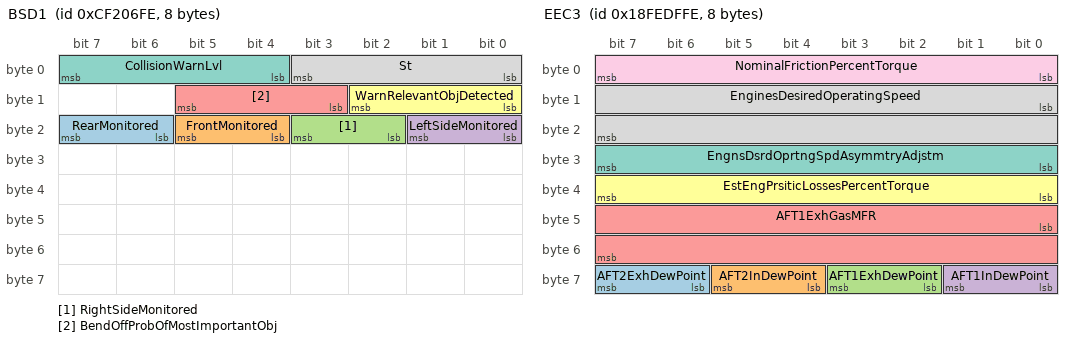
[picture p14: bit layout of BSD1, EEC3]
BO_ 217188094 BSD1: 8 Vector__XXX
 SG_ RearMonitored : 22|2@1+ (1,0) [0|3] "" Vector__XXX
 SG_ FrontMonitored : 20|2@1+ (1,0) [0|3] "" Vector__XXX
 SG_ RightSideMonitored : 18|2@1+ (1,0) [0|3] "" Vector__XXX
 SG_ LeftSideMonitored : 16|2@1+ (1,0) [0|3] "" Vector__XXX
 SG_ BendOffProbOfMostImportantObj : 11|3@1+ (1,0) [0|7] "" Vector__XXX
 SG_ WarnRelevantObjDetected : 8|3@1+ (1,0) [0|7] "" Vector__XXX
 SG_ CollisionWarnLvl : 4|4@1+ (1,0) [0|15] "" Vector__XXX
 SG_ St : 0|4@1+ (1,0) [0|15] "" Vector__XXX

BO_ 419235584 DLCC1: 8 Vector__XXX
 SG_ EngAirShutoffLamp : 50|2@1+ (1,0) [0|3] "" Vector__XXX
 SG_ EngIntercoolerTempHiLamp : 48|2@1+ (1,0) [0|3] "" Vector__XXX
 SG_ EngFuelTempHiLamp : 46|2@1+ (1,0) [0|3] "" Vector__XXX
 SG_ EngOilTempHiLamp : 44|2@1+ (1,0) [0|3] "" Vector__XXX
 SG_ EngStopStartEnabledLamp : 42|2@1+ (1,0) [0|3] "" Vector__XXX
 SG_ EngStopStartAutoStartFailedLamp : 40|2@1+ (1,0) [0|3] "" Vector__XXX
 SG_ EngStopStartAutoStopActiveLamp : 38|2@1+ (1,0) [0|3] "" Vector__XXX
 SG_ EngIdleMnmgtPendingEventLamp : 36|2@1+ (1,0) [0|3] "" Vector__XXX
 SG_ VhclAccelerationRateLimitLampCmd : 34|2@1+ (1,0) [0|3] "" Vector__XXX
 SG_ EngSpeedVeryHighLampCmd : 32|2@1+ (1,0) [0|3] "" Vector__XXX
 SG_ EngSpeedHighLampCmd : 30|2@1+ (1,0) [0|3] "" Vector__XXX
 SG_ EngCtrlModule3ReadyForUseLampCmd : 28|2@1+ (1,0) [0|3] "" Vector__XXX
 SG_ EngCtrlModule2ReadyForUseLampCmd : 26|2@1+ (1,0) [0|3] "" Vector__XXX
 SG_ EngCtrlModule1ReadyForUseLampCmd : 24|2@1+ (1,0) [0|3] "" Vector__XXX
 SG_ EngFuelFilterRestrictedLampCmd : 22|2@1+ (1,0) [0|3] "" Vector__XXX
 SG_ EngAirFilterRestrictionLampCmd : 20|2@1+ (1,0) [0|3] "" Vector__XXX
 SG_ EngIdleManagementActiveLampCmd : 18|2@1+ (1,0) [0|3] "" Vector__XXX
 SG_ EngCoolantLevelLowLampCmd : 16|2@1+ (1,0) [0|3] "" Vector__XXX
 SG_ EngCoolantTempHighLampCmd : 14|2@1+ (1,0) [0|3] "" Vector__XXX
 SG_ EngOilPressLowLampCmd : 12|2@1+ (1,0) [0|3] "" Vector__XXX
 SG_ CmprssnBrkEnblSwtchIndctrLampCmd : 10|2@1+ (1,0) [0|3] "" Vector__XXX
 SG_ EngBrakeActiveLampCmd : 8|2@1+ (1,0) [0|3] "" Vector__XXX
 SG_ OBDMalfunctionIndicatorLampCmd : 6|2@1+ (1,0) [0|3] "" Vector__XXX
 SG_ EngRedStopLampCmd : 4|2@1+ (1,0) [0|3] "" Vector__XXX
 SG_ EngAmberWarningLampCmd : 2|2@1+ (1,0) [0|3] "" Vector__XXX
 SG_ EngProtectLampCmd : 0|2@1+ (1,0) [0|3] "" Vector__XXX

BO_ 419351294 DM01: 22 Vector__XXX
 SG_ FlashRedStopLamp : 12|2@1+ (1,0) [0|3] "" Vector__XXX
 SG_ FlashProtectLamp : 8|2@1+ (1,0) [0|3] "" Vector__XXX
 SG_ FlashMalfuncIndicatorLamp : 14|2@1+ (1,0) [0|3] "" Vector__XXX
 SG_ FlashAmberWarningLamp : 10|2@1+ (1,0) [0|3] "" Vector__XXX
 SG_ MalfunctionIndicatorLampStatus : 6|2@1+ (1,0) [0|3] "" Vector__XXX
 SG_ AmberWarningLampStatus : 2|2@1+ (1,0) [0|3] "" Vector__XXX
 SG_ RedStopLampState : 4|2@1+ (1,0) [0|3] "" Vector__XXX
 SG_ ProtectLampStatus : 0|2@1+ (1,0) [0|3] "" Vector__XXX
 SG_ DTC5 : 144|32@1+ (1,0) [0|4294967295] "" Vector__XXX
 SG_ DTC4 : 112|32@1+ (1,0) [0|4294967295] "" Vector__XXX
 SG_ DTC3 : 80|32@1+ (1,0) [0|4294967295] "" Vector__XXX
 SG_ DTC2 : 48|32@1+ (1,0) [0|4294967295] "" Vector__XXX
 SG_ DTC1 : 16|32@1+ (1,0) [0|4294967295] "" Vector__XXX

BO_ 419265790 DPFC1: 8 Vector__XXX
 SG_ ActiveRegenInhibitedDueThresher : 62|2@1+ (1,0) [0|3] "" Vector__XXX
 SG_ ActiveRegenAvailabilityStatus : 3|2@1+ (1,0) [0|3] "" Vector__XXX
 SG_ DslPrtcltFltrActvRgnrtnInhbt5629 : 58|2@1+ (1,0) [0|3] "" Vector__XXX
 SG_ AFT1DPFCondNotMetForActiveRegen : 60|2@1+ (1,0) [0|3] "" Vector__XXX
 SG_ HydrocarbonDoserPurgingEnable : 56|2@1+ (1,0) [0|3] "" Vector__XXX
 SG_ DslPrtcltFltrActvRgnrtnFrcdSttus : 53|3@1+ (1,0) [0|7] "" Vector__XXX
 SG_ ExhaustSystemHighTempLampCmd : 50|3@1+ (1,0) [0|7] "" Vector__XXX
 SG_ DslPrtcltFltrAtmtcActvRgnrtnIntt : 48|2@1+ (1,0) [0|3] "" Vector__XXX
 SG_ DslPrtcltFltrActvRgnrtnInhbt3717 : 46|2@1+ (1,0) [0|3] "" Vector__XXX
 SG_ DslPrtcltFltrActvRgnrtnInhbtdDTE : 44|2@1+ (1,0) [0|3] "" Vector__XXX
 SG_ DslPrtcltFltrActvRgnrtnInhbt3715 : 42|2@1+ (1,0) [0|3] "" Vector__XXX
 SG_ DslPrtcltFltrActvRgnrtnInhbtdDTT : 40|2@1+ (1,0) [0|3] "" Vector__XXX
 SG_ DslPrtcltFltrActvRgnrtnInhbt3713 : 38|2@1+ (1,0) [0|3] "" Vector__XXX
 SG_ DslPrtcltFltrActvRgnrtnInhbt3712 : 36|2@1+ (1,0) [0|3] "" Vector__XXX
 SG_ DslPrtcltFltrActvRgnrtnInhbtdDTL : 34|2@1+ (1,0) [0|3] "" Vector__XXX
 SG_ DslPrtcltFltrActvRgnrtnInhbt3710 : 32|2@1+ (1,0) [0|3] "" Vector__XXX
 SG_ DslPrtcltFltrActvRgnrtnInhbtdDTV : 30|2@1+ (1,0) [0|3] "" Vector__XXX
 SG_ DslPrtcltFltrActvRgnrtnInhbtdDTO : 28|2@1+ (1,0) [0|3] "" Vector__XXX
 SG_ DslPrtcltFltrActvRgnrtnInhbtdDTA : 26|2@1+ (1,0) [0|3] "" Vector__XXX
 SG_ DslPrtcltFltrActvRgnrtnInhbtdDTP : 24|2@1+ (1,0) [0|3] "" Vector__XXX
 SG_ DslPrtcltFltrActvRgnrtnInhbtdDTS : 22|2@1+ (1,0) [0|3] "" Vector__XXX
 SG_ DslPrtcltFltrActvRgnrtnInhbtdDTC : 20|2@1+ (1,0) [0|3] "" Vector__XXX
 SG_ DslPrtcltFltrActvRgnrtnInhbtdDTI : 18|2@1+ (1,0) [0|3] "" Vector__XXX
 SG_ DslPrtcltFltrActvRgnrtnInhbtdStt : 16|2@1+ (1,0) [0|3] "" Vector__XXX
 SG_ AFTDPFStatus : 12|3@1+ (1,0) [0|7] "" Vector__XXX
 SG_ AFTDPFActiveRegenStatus : 10|2@1+ (1,0) [0|3] "" Vector__XXX
 SG_ AFTDPFPassiveRegenStatus : 8|2@1+ (1,0) [0|3] "" Vector__XXX
 SG_ DieselParticulateFilterLampCmd : 0|3@1+ (1,0) [0|7] "" Vector__XXX

BO_ 217070078 EASI: 8 Vector__XXX
 SG_ FuelSys2TotalInMassAirFlowRate : 32|16@1+ (0.0009765625,0) [0|62.74902344] "kg/s" Vector__XXX
 SG_ EngTotalIntakeMassAirFlowRate : 16|16@1+ (0.0009765625,0) [0|62.74902344] "kg/s" Vector__XXX
 SG_ EngDesiredAirFuelRatio : 0|16@1+ (0.001,0) [0|64.255] "" Vector__XXX

BO_ 419357694 EC1: 40 Vector__XXX
 SG_ DefaultIdleTrqLmt : 312|8@1+ (1,-125) [0|125] "%" Vector__XXX
 SG_ SupportTSC1CtrlPurposeGroup4 : 304|8@1+ (1,0) [0|255] "" Vector__XXX
 SG_ SupportTSC1CtrlPurposeGroup3 : 296|8@1+ (1,0) [0|255] "" Vector__XXX
 SG_ SupportTSC1CtrlPurposeGroup2 : 288|8@1+ (1,0) [0|255] "" Vector__XXX
 SG_ SupportTSC1CtrlPurposeGroup1 : 280|8@1+ (1,0) [0|255] "" Vector__XXX
 SG_ SupportVariableRateTSC1Message : 272|8@1+ (1,0) [0|255] "" Vector__XXX
 SG_ EngDefaultTorqueLimit : 256|16@1+ (1,0) [0|64255] "Nm" Vector__XXX
 SG_ EngMomentOfInertia : 240|16@1+ (0.004,0) [0|257.02] "kg�m�" Vector__XXX
 SG_ EngExRngRqstdSpdCtrlRngUpprLimit : 224|16@1+ (0.125,0) [0|8031.875] "rpm" Vector__XXX
 SG_ EngRqstdTrqueCtrlRangeUpperLimit : 216|8@1+ (1,-125) [0|125] "%" Vector__XXX
 SG_ EngRqstdTrqueCtrlRangeLowerLimit : 208|8@1+ (1,-125) [0|125] "%" Vector__XXX
 SG_ EngRqstdSpeedCtrlRangeUpperLimit : 200|8@1+ (10,0) [0|2500] "rpm" Vector__XXX
 SG_ EngRqstdSpeedCtrlRangeLowerLimit : 192|8@1+ (10,0) [0|2500] "rpm" Vector__XXX
 SG_ EngMaxMomentaryOverrideTimeLimit : 184|8@1+ (0.1,0) [0|25] "s" Vector__XXX
 SG_ EngMxMmentaryOverrideSpeedPoint7 : 168|16@1+ (0.125,0) [0|8031.875] "rpm" Vector__XXX
 SG_ EngReferenceTorque : 152|16@1+ (1,0) [0|64255] "Nm" Vector__XXX
 SG_ EngGain : 136|16@1+ (0.00078125,0) [0|50.2] "%/rpm" Vector__XXX
 SG_ EngSpeedAtHighIdlePoint6 : 120|16@1+ (0.125,0) [0|8031.875] "rpm" Vector__XXX
 SG_ EngPercentTorqueAtPoint5 : 112|8@1+ (1,-125) [0|125] "%" Vector__XXX
 SG_ EngSpeedAtPoint5 : 96|16@1+ (0.125,0) [0|8031.875] "rpm" Vector__XXX
 SG_ EngPercentTorqueAtPoint4 : 88|8@1+ (1,-125) [0|125] "%" Vector__XXX
 SG_ EngSpeedAtPoint4 : 72|16@1+ (0.125,0) [0|8031.875] "rpm" Vector__XXX
 SG_ EngPercentTorqueAtPoint3 : 64|8@1+ (1,-125) [0|125] "%" Vector__XXX
 SG_ EngSpeedAtPoint3 : 48|16@1+ (0.125,0) [0|8031.875] "rpm" Vector__XXX
 SG_ EngPercentTorqueAtPoint2 : 40|8@1+ (1,-125) [0|125] "%" Vector__XXX
 SG_ EngSpeedAtPoint2 : 24|16@1+ (0.125,0) [0|8031.875] "rpm" Vector__XXX
 SG_ EngPercentTorqueAtIdlePoint1 : 16|8@1+ (1,-125) [0|125] "%" Vector__XXX
 SG_ EngSpeedAtIdlePoint1 : 0|16@1+ (0.125,0) [0|8031.875] "rpm" Vector__XXX

BO_ 419356670 EEC3: 8 Vector__XXX
 SG_ AFT2ExhDewPoint : 62|2@1+ (1,0) [0|3] "" Vector__XXX
 SG_ AFT2InDewPoint : 60|2@1+ (1,0) [0|3] "" Vector__XXX
 SG_ AFT1ExhDewPoint : 58|2@1+ (1,0) [0|3] "" Vector__XXX
 SG_ AFT1InDewPoint : 56|2@1+ (1,0) [0|3] "" Vector__XXX
 SG_ AFT1ExhGasMFR : 40|16@1+ (0.2,0) [0|12851] "kg/h" Vector__XXX
 SG_ EstEngPrsiticLossesPercentTorque : 32|8@1+ (1,-125) [0|125] "%" Vector__XXX
 SG_ EngnsDsrdOprtngSpdAsymmtryAdjstm : 24|8@1+ (1,0) [0|250] "" Vector__XXX
 SG_ EnginesDesiredOperatingSpeed : 8|16@1+ (0.125,0) [0|8031.875] "rpm" Vector__XXX
 SG_ NominalFrictionPercentTorque : 0|8@1+ (1,-125) [-125|125] "%" Vector__XXX

BO_ 217058046 EGF1: 8 Vector__XXX
 SG_ TargetFreshAirMassFlow : 48|16@1+ (0.05,0) [0|3212.75] "kg/h" Vector__XXX
 SG_ EngExhstGsRcrcltion2MassFlowRate : 32|16@1+ (0.05,0) [0|3212.75] "kg/h" Vector__XXX
 SG_ EngIntakeAirMassFlowRate : 16|16@1+ (0.05,0) [0|3212.75] "kg/h" Vector__XXX
 SG_ EngExhstGsRcrcltion1MassFlowRate : 0|16@1+ (0.05,0) [0|3212.75] "kg/h" Vector__XXX

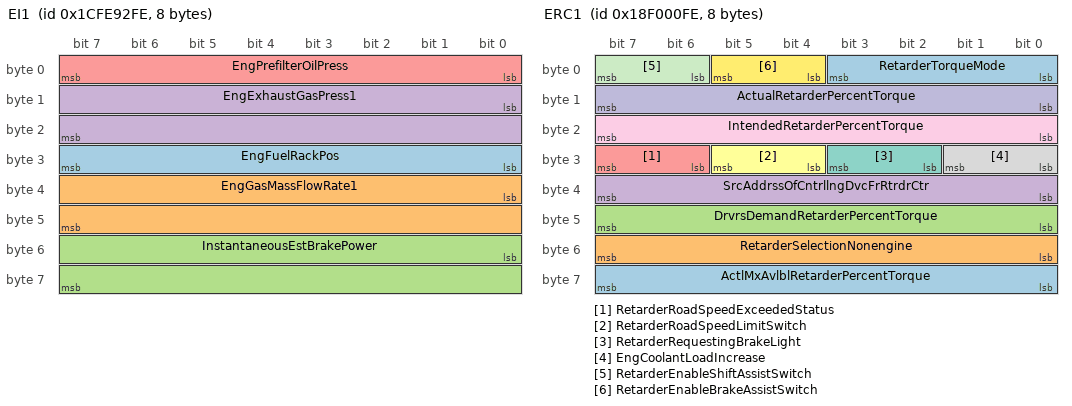
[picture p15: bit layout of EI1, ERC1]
BO_ 486445822 EI1: 8 Vector__XXX
 SG_ EngFuelRackPos : 24|8@1+ (0.4,0) [0|100] "%" Vector__XXX
 SG_ EngGasMassFlowRate1 : 32|16@1+ (0.05,0) [0|3212.75] "kg/h" Vector__XXX
 SG_ InstantaneousEstBrakePower : 48|16@1+ (0.5,0) [0|32127.5] "kW" Vector__XXX
 SG_ EngExhaustGasPress1 : 8|16@1+ (0.0078125,-250) [-250|251.99] "kPa" Vector__XXX
 SG_ EngPrefilterOilPress : 0|8@1+ (4,0) [0|1000] "kPa" Vector__XXX

BO_ 418382078 ERC1: 8 Vector__XXX
 SG_ ActlMxAvlblRetarderPercentTorque : 56|8@1+ (1,-125) [-125|0] "%" Vector__XXX
 SG_ RetarderSelectionNonengine : 48|8@1+ (0.4,0) [0|100] "%" Vector__XXX
 SG_ DrvrsDemandRetarderPercentTorque : 40|8@1+ (1,-125) [-125|0] "%" Vector__XXX
 SG_ SrcAddrssOfCntrllngDvcFrRtrdrCtr : 32|8@1+ (1,0) [0|253] "" Vector__XXX
 SG_ RetarderRoadSpeedExceededStatus : 30|2@1+ (1,0) [0|3] "" Vector__XXX
 SG_ RetarderRoadSpeedLimitSwitch : 28|2@1+ (1,0) [0|3] "" Vector__XXX
 SG_ RetarderRequestingBrakeLight : 26|2@1+ (1,0) [0|3] "" Vector__XXX
 SG_ EngCoolantLoadIncrease : 24|2@1+ (1,0) [0|3] "" Vector__XXX
 SG_ IntendedRetarderPercentTorque : 16|8@1+ (1,-125) [-125|0] "%" Vector__XXX
 SG_ ActualRetarderPercentTorque : 8|8@1+ (1,-125) [-125|0] "%" Vector__XXX
 SG_ RetarderEnableShiftAssistSwitch : 6|2@1+ (1,0) [0|3] "" Vector__XXX
 SG_ RetarderEnableBrakeAssistSwitch : 4|2@1+ (1,0) [0|3] "" Vector__XXX
 SG_ RetarderTorqueMode : 0|4@1+ (1,0) [0|15] "" Vector__XXX

BO_ 419341566 ET2: 8 Vector__XXX
 SG_ EngExhaustGasRecirculation1Temp : 48|16@1+ (0.03125,-273) [-273|1734.96875] "�C" Vector__XXX
 SG_ EngExhstGsRcirculation1DiffPress : 32|16@1+ (0.0078125,-250) [-250|251.99] "kPa" Vector__XXX
 SG_ EngECUTemp : 16|16@1+ (0.03125,-273) [-273|1734.96875] "�C" Vector__XXX
 SG_ EngOilTemp2 : 0|16@1+ (0.03125,-273) [-273|1734.96875] "�C" Vector__XXX

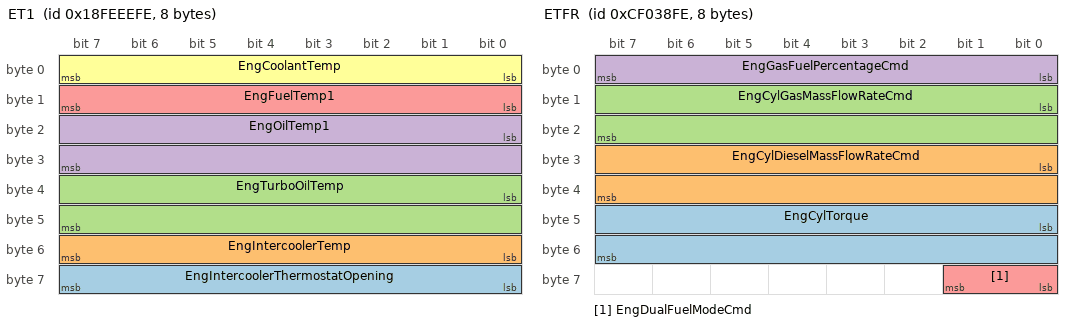
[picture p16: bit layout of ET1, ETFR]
BO_ 419360510 ET1: 8 Vector__XXX
 SG_ EngIntercoolerThermostatOpening : 56|8@1+ (0.4,0) [0|100] "%" Vector__XXX
 SG_ EngIntercoolerTemp : 48|8@1+ (1,-40) [-40|210] "�C" Vector__XXX
 SG_ EngTurboOilTemp : 32|16@1+ (0.03125,-273) [-273|1734.96875] "�C" Vector__XXX
 SG_ EngOilTemp1 : 16|16@1+ (0.03125,-273) [-273|1734.96875] "�C" Vector__XXX
 SG_ EngFuelTemp1 : 8|8@1+ (1,-40) [-40|210] "�C" Vector__XXX
 SG_ EngCoolantTemp : 0|8@1+ (1,-40) [-40|210] "�C" Vector__XXX

BO_ 217069822 ETFR: 8 Vector__XXX
 SG_ EngCylTorque : 40|16@1+ (1,0) [0|64255] "Nm" Vector__XXX
 SG_ EngCylDieselMassFlowRateCmd : 24|16@1+ (6.103515625E-05,0) [0|3.921813965] "kg/s" Vector__XXX
 SG_ EngCylGasMassFlowRateCmd : 8|16@1+ (6.103515625E-05,0) [0|3.921813965] "kg/s" Vector__XXX
 SG_ EngGasFuelPercentageCmd : 0|8@1+ (0.5,0) [0|100] "%" Vector__XXX
 SG_ EngDualFuelModeCmd : 56|2@1+ (1,0) [0|100] "" Vector__XXX

BO_ 419358206 HOURS: 8 Vector__XXX
 SG_ EngTotalRevolutions : 32|32@1+ (1000,0) [0|4211081215000] "r" Vector__XXX
 SG_ EngTotalHoursOfOperation : 0|32@1+ (0.05,0) [0|210554060.75] "h" Vector__XXX

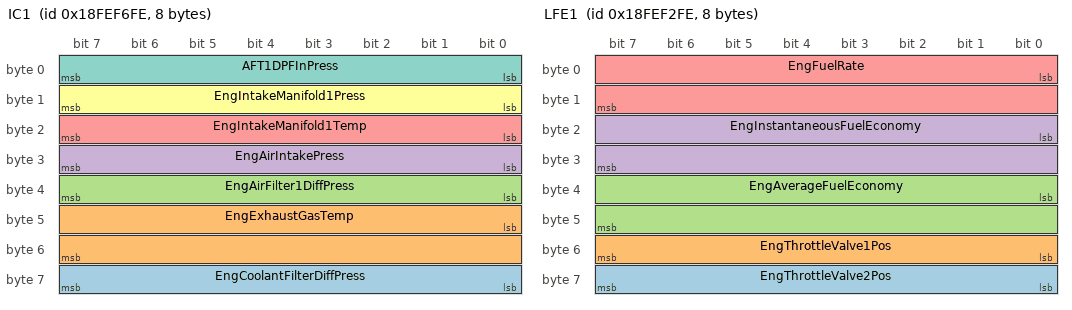
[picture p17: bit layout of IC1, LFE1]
BO_ 419362558 IC1: 8 Vector__XXX
 SG_ EngCoolantFilterDiffPress : 56|8@1+ (0.5,0) [0|125] "kPa" Vector__XXX
 SG_ EngExhaustGasTemp : 40|16@1+ (0.03125,-273) [-273|1734.96875] "�C" Vector__XXX
 SG_ EngAirFilter1DiffPress : 32|8@1+ (0.05,0) [0|12.5] "kPa" Vector__XXX
 SG_ EngAirIntakePress : 24|8@1+ (2,0) [0|500] "kPa" Vector__XXX
 SG_ EngIntakeManifold1Temp : 16|8@1+ (1,-40) [-40|210] "�C" Vector__XXX
 SG_ EngIntakeManifold1Press : 8|8@1+ (2,0) [0|500] "kPa" Vector__XXX
 SG_ AFT1DPFInPress : 0|8@1+ (0.5,0) [0|125] "kPa" Vector__XXX

BO_ 419361534 LFE1: 8 Vector__XXX
 SG_ EngThrottleValve2Pos : 56|8@1+ (0.4,0) [0|100] "%" Vector__XXX
 SG_ EngThrottleValve1Pos : 48|8@1+ (0.4,0) [0|100] "%" Vector__XXX
 SG_ EngAverageFuelEconomy : 32|16@1+ (0.001953125,0) [0|125.49804688] "km/L" Vector__XXX
 SG_ EngInstantaneousFuelEconomy : 16|16@1+ (0.001953125,0) [0|125.49804688] "km/L" Vector__XXX
 SG_ EngFuelRate : 0|16@1+ (0.05,0) [0|3212.75] "l/h" Vector__XXX

BO_ 419359230 LFC1: 8 Vector__XXX
 SG_ EngTotalFuelUsed : 32|32@1+ (0.5,0) [0|2105540607.5] "l" Vector__XXX
 SG_ EngTripFuel : 0|32@1+ (0.5,0) [0|2105540607.5] "l" Vector__XXX

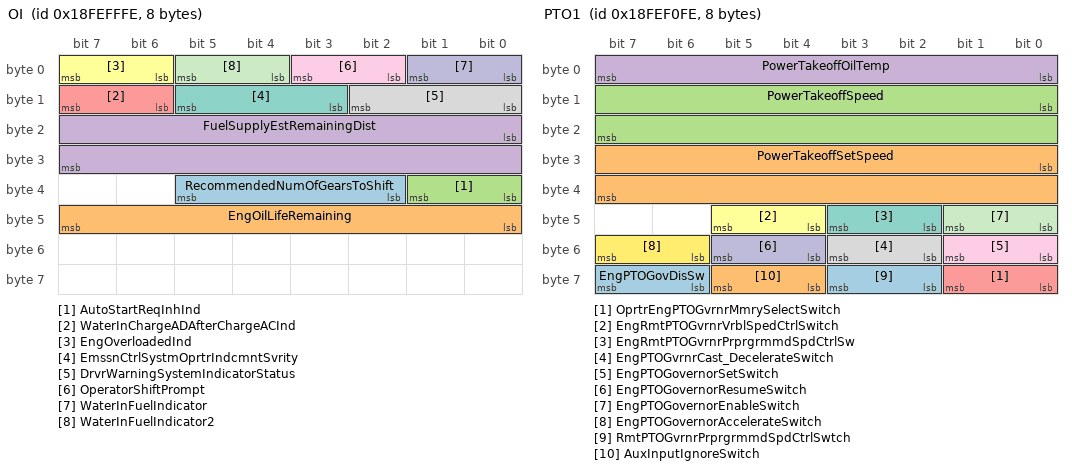
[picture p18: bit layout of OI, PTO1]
BO_ 419364862 OI: 8 Vector__XXX
 SG_ RecommendedNumOfGearsToShift : 34|4@1+ (1,0) [0|13] "" Vector__XXX
 SG_ EngOilLifeRemaining : 40|8@1+ (0.4,0) [0|100] "%" Vector__XXX
 SG_ AutoStartReqInhInd : 32|2@1+ (1,0) [0|3] "" Vector__XXX
 SG_ FuelSupplyEstRemainingDist : 16|16@1+ (1,0) [0|64255] "km" Vector__XXX
 SG_ WaterInChargeADAfterChargeACInd : 14|2@1+ (1,0) [0|3] "" Vector__XXX
 SG_ EngOverloadedInd : 6|2@1+ (1,0) [0|3] "" Vector__XXX
 SG_ EmssnCtrlSystmOprtrIndcmntSvrity : 11|3@1+ (1,0) [0|7] "" Vector__XXX
 SG_ DrvrWarningSystemIndicatorStatus : 8|3@1+ (1,0) [0|7] "" Vector__XXX
 SG_ OperatorShiftPrompt : 2|2@1+ (1,0) [0|3] "" Vector__XXX
 SG_ WaterInFuelIndicator : 0|2@1+ (1,0) [0|3] "" Vector__XXX
 SG_ WaterInFuelIndicator2 : 4|2@1+ (1,0) [0|3] "" Vector__XXX

BO_ 419361022 PTO1: 8 Vector__XXX
 SG_ EngPTOGovDisSw : 62|2@1+ (1,0) [0|3] "" Vector__XXX
 SG_ PowerTakeoffSetSpeed : 24|16@1+ (0.125,0) [0|8031.875] "rpm" Vector__XXX
 SG_ PowerTakeoffSpeed : 8|16@1+ (0.125,0) [0|8031.875] "rpm" Vector__XXX
 SG_ PowerTakeoffOilTemp : 0|8@1+ (1,-40) [-40|210] "�C" Vector__XXX
 SG_ OprtrEngPTOGvrnrMmrySelectSwitch : 56|2@1+ (1,0) [0|3] "" Vector__XXX
 SG_ EngRmtPTOGvrnrVrblSpedCtrlSwitch : 44|2@1+ (1,0) [0|3] "" Vector__XXX
 SG_ EngRmtPTOGvrnrPrprgrmmdSpdCtrlSw : 42|2@1+ (1,0) [0|3] "" Vector__XXX
 SG_ EngPTOGvrnrCast_DecelerateSwitch : 50|2@1+ (1,0) [0|3] "" Vector__XXX
 SG_ EngPTOGovernorSetSwitch : 48|2@1+ (1,0) [0|3] "" Vector__XXX
 SG_ EngPTOGovernorResumeSwitch : 52|2@1+ (1,0) [0|3] "" Vector__XXX
 SG_ EngPTOGovernorEnableSwitch : 40|2@1+ (1,0) [0|3] "" Vector__XXX
 SG_ EngPTOGovernorAccelerateSwitch : 54|2@1+ (1,0) [0|3] "" Vector__XXX
 SG_ RmtPTOGvrnrPrprgrmmdSpdCtrlSwtch : 58|2@1+ (1,0) [0|3] "" Vector__XXX
 SG_ AuxInputIgnoreSwitch : 60|2@1+ (1,0) [0|3] "" Vector__XXX

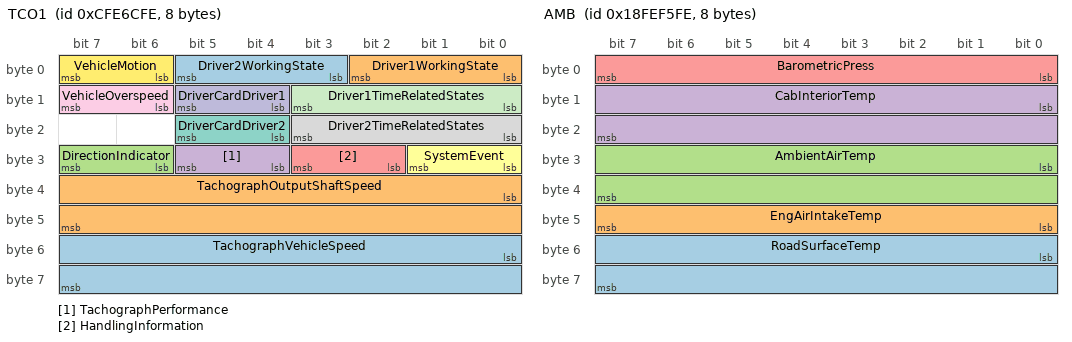
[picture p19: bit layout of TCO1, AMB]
BO_ 218000638 TCO1: 8 Vector__XXX
 SG_ TachographVehicleSpeed : 48|16@1+ (0.00390625,0) [0|250.996] "km/h" Vector__XXX
 SG_ TachographOutputShaftSpeed : 32|16@1+ (0.125,0) [0|8031.875] "rpm" Vector__XXX
 SG_ DirectionIndicator : 30|2@1+ (1,0) [0|3] "" Vector__XXX
 SG_ TachographPerformance : 28|2@1+ (1,0) [0|3] "" Vector__XXX
 SG_ HandlingInformation : 26|2@1+ (1,0) [0|3] "" Vector__XXX
 SG_ SystemEvent : 24|2@1+ (1,0) [0|3] "" Vector__XXX
 SG_ DriverCardDriver2 : 20|2@1+ (1,0) [0|3] "" Vector__XXX
 SG_ Driver2TimeRelatedStates : 16|4@1+ (1,0) [0|15] "" Vector__XXX
 SG_ VehicleOverspeed : 14|2@1+ (1,0) [0|3] "" Vector__XXX
 SG_ DriverCardDriver1 : 12|2@1+ (1,0) [0|3] "" Vector__XXX
 SG_ Driver1TimeRelatedStates : 8|4@1+ (1,0) [0|15] "" Vector__XXX
 SG_ VehicleMotion : 6|2@1+ (1,0) [0|3] "" Vector__XXX
 SG_ Driver2WorkingState : 3|3@1+ (1,0) [0|7] "" Vector__XXX
 SG_ Driver1WorkingState : 0|3@1+ (1,0) [0|7] "" Vector__XXX

BO_ 418184958 TPCMxx: 8 Vector__XXX
 SG_ TotalNumberOfPacketsEoMA m19 : 24|8@1+ (1,0) [0|255] "" Vector__XXX
 SG_ TotalMessageSizeEoMA m19 : 8|16@1+ (1,0) [0|64255] "" Vector__XXX
 SG_ TotalMessageSizeBAM m32 : 8|16@1+ (1,0) [0|64255] "" Vector__XXX
 SG_ TotalNumberOfPacketsBAM m32 : 24|8@1+ (1,0) [0|255] "" Vector__XXX
 SG_ ConnectionAbortReason m255 : 8|8@1+ (1,0) [0|255] "" Vector__XXX
 SG_ NextPacketNumberToBeSent m17 : 16|8@1+ (1,0) [0|255] "" Vector__XXX
 SG_ NumberOfPacketsThatCanBeSent m17 : 8|8@1+ (1,0) [0|255] "" Vector__XXX
 SG_ PGNumber : 40|24@1+ (1,0) [0|16777200] "" Vector__XXX
 SG_ MaximumNumberOfPackets m16 : 32|8@1+ (1,0) [0|255] "" Vector__XXX
 SG_ TotalNumberOfPackets m16 : 24|8@1+ (1,0) [0|255] "" Vector__XXX
 SG_ TotalMessageSize m16 : 8|16@1+ (1,0) [0|64255] "" Vector__XXX
 SG_ ControlByte M : 0|8@1+ (1,0) [0|255] "" Vector__XXX

BO_ 418119422 TPDT: 8 Vector__XXX
 SG_ SequenceNumber : 0|8@1+ (1,0) [0|255] "" Vector__XXX

BO_ 419362302 AMB: 8 Vector__XXX
 SG_ RoadSurfaceTemp : 48|16@1+ (0.03125,-273) [-273|1734.96875] "�C" Vector__XXX
 SG_ EngAirIntakeTemp : 40|8@1+ (1,-40) [-40|210] "�C" Vector__XXX
 SG_ AmbientAirTemp : 24|16@1+ (0.03125,-273) [-273|1734.96875] "�C" Vector__XXX
 SG_ CabInteriorTemp : 8|16@1+ (0.03125,-273) [-273|1734.96875] "�C" Vector__XXX
 SG_ BarometricPress : 0|8@1+ (0.5,0) [0|125] "kPa" Vector__XXX

CM_ SG_ 662 DET_RANGE_089 " measured position  of the detection";
CM_ SG_ 662 DET_RANGE_ERR_089 "RMSE or standard deviation of the measured angle  of the detection";
CM_ SG_ 662 DET_RANGE_VELOCITY_089 "Radial velocity of the detection positive in direction to the sensor";
CM_ SG_ 662 DET_RANGE_VELOCITY_ERR_089 "RMSE or standard deviation of the measure radial velocity of the detection";
CM_ SG_ 662 DET_AZIMUTH_089 "Measured angle  of the detection";
CM_ SG_ 662 DET_AZIMUTH_ERR_089 "RMSE or standard deviation of the measured angle  of the detection";
CM_ SG_ 662 DET_ELEVATION_089 "measured elevation of the detection";
CM_ SG_ 662 DET_ELEVATION_ERR_089 "RMSE or standard deviation of the measured elevation  of the detection";
CM_ SG_ 662 DET_RCS_089 "Radar Cross Section or Amplitude, is a measure of how detectable an object is by radar. A larger RCS indicates that an object is more easily detected.";
CM_ SG_ 662 DET_BI_STATIC_FLAG_089 "1 if detection is bi-static 0 otherwise";
CM_ SG_ 662 DET_SUPER_RES_TARGET_089 "flasg is set if the detection is super resolution target";
CM_ SG_ 662 DET_SNR_089 "The signal to noise ratio (SNR) of the radar detection";
CM_ SG_ 662 DET_EXISTENCE_PROB_089 "Existence probability of the detection not based on history. Value does  not depend on any past experience with similar detections.

ote Use as confidence measure where a low value means less confidence
and a high value indicates strong confidence.";
CM_ SG_ 662 DET_HVC_FLAG_089 "Core2 Vehicle clutter flag";
CM_ SG_ 662 DET_CONFD_AZIMUTH_089 "Define the Confidence of Azimuth for Detection ";
CM_ SG_ 662 DET_CONFD_ELEVATION_089 "Define the Confidence of Elevation for the Detection ";
CM_ SG_ 662 DET_BI_STATIC_FLAG_090 "1 if detection is bi-static 0 otherwise";
CM_ SG_ 662 DET_BI_STATIC_FLAG_091 "1 if detection is bi-static 0 otherwise";
CM_ SG_ 662 DET_BI_STATIC_FLAG_092 "1 if detection is bi-static 0 otherwise";
CM_ SG_ 662 DET_MH_SCAN_INDEX_4LSB_089_092 "Scan index of the measured detection";
CM_ SG_ 662 DET_MH_CYCLE_COUNTER_089_092 "Detection Alive Counter";
CM_ SG_ 663 DET_RANGE_093 " measured position  of the detection";
CM_ SG_ 663 DET_RANGE_ERR_093 "RMSE or standard deviation of the measured angle  of the detection";
CM_ SG_ 663 DET_RANGE_VELOCITY_093 "Radial velocity of the detection positive in direction to the sensor";
CM_ SG_ 663 DET_RANGE_VELOCITY_ERR_093 "RMSE or standard deviation of the measure radial velocity of the detection";
CM_ SG_ 663 DET_AZIMUTH_093 "Measured angle  of the detection";
CM_ SG_ 663 DET_AZIMUTH_ERR_093 "RMSE or standard deviation of the measured angle  of the detection";
CM_ SG_ 663 DET_ELEVATION_093 "measured elevation of the detection";
CM_ SG_ 663 DET_ELEVATION_ERR_093 "RMSE or standard deviation of the measured elevation  of the detection";
CM_ SG_ 663 DET_RCS_093 "Radar Cross Section or Amplitude, is a measure of how detectable an object is by radar. A larger RCS indicates that an object is more easily detected.";
CM_ SG_ 663 DET_BI_STATIC_FLAG_093 "1 if detection is bi-static 0 otherwise";
CM_ SG_ 663 DET_SUPER_RES_TARGET_093 "flasg is set if the detection is super resolution target";
CM_ SG_ 663 DET_SNR_093 "The signal to noise ratio (SNR) of the radar detection";
CM_ SG_ 663 DET_EXISTENCE_PROB_093 "Existence probability of the detection not based on history. Value does  not depend on any past experience with similar detections.

ote Use as confidence measure where a low value means less confidence
and a high value indicates strong confidence.";
CM_ SG_ 663 DET_HVC_FLAG_093 "Core2 Vehicle clutter flag";
CM_ SG_ 663 DET_CONFD_AZIMUTH_093 "Define the Confidence of Azimuth for Detection ";
CM_ SG_ 663 DET_CONFD_ELEVATION_093 "Define the Confidence of Elevation for the Detection ";
CM_ SG_ 663 DET_BI_STATIC_FLAG_094 "1 if detection is bi-static 0 otherwise";
CM_ SG_ 663 DET_BI_STATIC_FLAG_095 "1 if detection is bi-static 0 otherwise";
CM_ SG_ 663 DET_BI_STATIC_FLAG_096 "1 if detection is bi-static 0 otherwise";
CM_ SG_ 663 DET_MH_SCAN_INDEX_4LSB_093_096 "Scan index of the measured detection";
CM_ SG_ 663 DET_MH_CYCLE_COUNTER_093_096 "Detection Alive Counter";
CM_ SG_ 664 DET_RANGE_097 " measured position  of the detection";
CM_ SG_ 664 DET_RANGE_ERR_097 "RMSE or standard deviation of the measured angle  of the detection";
CM_ SG_ 664 DET_RANGE_VELOCITY_097 "Radial velocity of the detection positive in direction to the sensor";
CM_ SG_ 664 DET_RANGE_VELOCITY_ERR_097 "RMSE or standard deviation of the measure radial velocity of the detection";
CM_ SG_ 664 DET_AZIMUTH_097 "Measured angle  of the detection";
CM_ SG_ 664 DET_AZIMUTH_ERR_097 "RMSE or standard deviation of the measured angle  of the detection";
CM_ SG_ 664 DET_ELEVATION_097 "measured elevation of the detection";
CM_ SG_ 664 DET_ELEVATION_ERR_097 "RMSE or standard deviation of the measured elevation  of the detection";
CM_ SG_ 664 DET_RCS_097 "Radar Cross Section or Amplitude, is a measure of how detectable an object is by radar. A larger RCS indicates that an object is more easily detected.";
CM_ SG_ 664 DET_BI_STATIC_FLAG_097 "1 if detection is bi-static 0 otherwise";
CM_ SG_ 664 DET_SUPER_RES_TARGET_097 "flasg is set if the detection is super resolution target";
CM_ SG_ 664 DET_SNR_097 "The signal to noise ratio (SNR) of the radar detection";
CM_ SG_ 664 DET_EXISTENCE_PROB_097 "Existence probability of the detection not based on history. Value does  not depend on any past experience with similar detections.

ote Use as confidence measure where a low value means less confidence
and a high value indicates strong confidence.";
CM_ SG_ 664 DET_HVC_FLAG_097 "Core2 Vehicle clutter flag";
CM_ SG_ 664 DET_CONFD_AZIMUTH_097 "Define the Confidence of Azimuth for Detection ";
CM_ SG_ 664 DET_CONFD_ELEVATION_097 "Define the Confidence of Elevation for the Detection ";
CM_ SG_ 664 DET_BI_STATIC_FLAG_098 "1 if detection is bi-static 0 otherwise";
CM_ SG_ 664 DET_BI_STATIC_FLAG_099 "1 if detection is bi-static 0 otherwise";
CM_ SG_ 664 DET_BI_STATIC_FLAG_100 "1 if detection is bi-static 0 otherwise";
CM_ SG_ 664 DET_MH_SCAN_INDEX_4LSB_097_100 "Scan index of the measured detection";
CM_ SG_ 664 DET_MH_CYCLE_COUNTER_097_100 "Detection Alive Counter";
CM_ SG_ 665 DET_RANGE_101 " measured position  of the detection";
CM_ SG_ 665 DET_RANGE_ERR_101 "RMSE or standard deviation of the measured angle  of the detection";
CM_ SG_ 665 DET_RANGE_VELOCITY_101 "Radial velocity of the detection positive in direction to the sensor";
CM_ SG_ 665 DET_RANGE_VELOCITY_ERR_101 "RMSE or standard deviation of the measure radial velocity of the detection";
CM_ SG_ 665 DET_AZIMUTH_101 "Measured angle  of the detection";
CM_ SG_ 665 DET_AZIMUTH_ERR_101 "RMSE or standard deviation of the measured angle  of the detection";
CM_ SG_ 665 DET_ELEVATION_101 "measured elevation of the detection";
CM_ SG_ 665 DET_ELEVATION_ERR_101 "RMSE or standard deviation of the measured elevation  of the detection";
CM_ SG_ 665 DET_RCS_101 "Radar Cross Section or Amplitude, is a measure of how detectable an object is by radar. A larger RCS indicates that an object is more easily detected.";
CM_ SG_ 665 DET_BI_STATIC_FLAG_101 "1 if detection is bi-static 0 otherwise";
CM_ SG_ 665 DET_SUPER_RES_TARGET_101 "flasg is set if the detection is super resolution target";
CM_ SG_ 665 DET_SNR_101 "The signal to noise ratio (SNR) of the radar detection";
CM_ SG_ 665 DET_EXISTENCE_PROB_101 "Existence probability of the detection not based on history. Value does  not depend on any past experience with similar detections.

ote Use as confidence measure where a low value means less confidence
and a high value indicates strong confidence.";
CM_ SG_ 665 DET_HVC_FLAG_101 "Core2 Vehicle clutter flag";
CM_ SG_ 665 DET_CONFD_AZIMUTH_101 "Define the Confidence of Azimuth for Detection ";
CM_ SG_ 665 DET_CONFD_ELEVATION_101 "Define the Confidence of Elevation for the Detection ";
CM_ SG_ 665 DET_BI_STATIC_FLAG_102 "1 if detection is bi-static 0 otherwise";
CM_ SG_ 665 DET_BI_STATIC_FLAG_103 "1 if detection is bi-static 0 otherwise";
CM_ SG_ 665 DET_BI_STATIC_FLAG_104 "1 if detection is bi-static 0 otherwise";
CM_ SG_ 665 DET_MH_SCAN_INDEX_4LSB_101_104 "Scan index of the measured detection";
CM_ SG_ 665 DET_MH_CYCLE_COUNTER_101_104 "Detection Alive Counter";
CM_ SG_ 666 DET_RANGE_105 " measured position  of the detection";
CM_ SG_ 666 DET_RANGE_ERR_105 "RMSE or standard deviation of the measured angle  of the detection";
CM_ SG_ 666 DET_RANGE_VELOCITY_105 "Radial velocity of the detection positive in direction to the sensor";
CM_ SG_ 666 DET_RANGE_VELOCITY_ERR_105 "RMSE or standard deviation of the measure radial velocity of the detection";
CM_ SG_ 666 DET_AZIMUTH_105 "Measured angle  of the detection";
CM_ SG_ 666 DET_AZIMUTH_ERR_105 "RMSE or standard deviation of the measured angle  of the detection";
CM_ SG_ 666 DET_ELEVATION_105 "measured elevation of the detection";
CM_ SG_ 666 DET_ELEVATION_ERR_105 "RMSE or standard deviation of the measured elevation  of the detection";
CM_ SG_ 666 DET_RCS_105 "Radar Cross Section or Amplitude, is a measure of how detectable an object is by radar. A larger RCS indicates that an object is more easily detected.";
CM_ SG_ 666 DET_BI_STATIC_FLAG_105 "1 if detection is bi-static 0 otherwise";
CM_ SG_ 666 DET_SUPER_RES_TARGET_105 "flasg is set if the detection is super resolution target";
CM_ SG_ 666 DET_SNR_105 "The signal to noise ratio (SNR) of the radar detection";
CM_ SG_ 666 DET_EXISTENCE_PROB_105 "Existence probability of the detection not based on history. Value does  not depend on any past experience with similar detections.

ote Use as confidence measure where a low value means less confidence
and a high value indicates strong confidence.";
CM_ SG_ 666 DET_HVC_FLAG_105 "Core2 Vehicle clutter flag";
CM_ SG_ 666 DET_CONFD_AZIMUTH_105 "Define the Confidence of Azimuth for Detection ";
CM_ SG_ 666 DET_CONFD_ELEVATION_105 "Define the Confidence of Elevation for the Detection ";
CM_ SG_ 666 DET_BI_STATIC_FLAG_106 "1 if detection is bi-static 0 otherwise";
CM_ SG_ 666 DET_BI_STATIC_FLAG_107 "1 if detection is bi-static 0 otherwise";
CM_ SG_ 666 DET_BI_STATIC_FLAG_108 "1 if detection is bi-static 0 otherwise";
CM_ SG_ 666 DET_MH_SCAN_INDEX_4LSB_105_108 "Scan index of the measured detection";
CM_ SG_ 666 DET_MH_CYCLE_COUNTER_105_108 "Detection Alive Counter";
CM_ SG_ 667 DET_RANGE_109 " measured position  of the detection";
CM_ SG_ 667 DET_RANGE_ERR_109 "RMSE or standard deviation of the measured angle  of the detection";
CM_ SG_ 667 DET_RANGE_VELOCITY_109 "Radial velocity of the detection positive in direction to the sensor";
CM_ SG_ 667 DET_RANGE_VELOCITY_ERR_109 "RMSE or standard deviation of the measure radial velocity of the detection";
CM_ SG_ 667 DET_AZIMUTH_109 "Measured angle  of the detection";
CM_ SG_ 667 DET_AZIMUTH_ERR_109 "RMSE or standard deviation of the measured angle  of the detection";
CM_ SG_ 667 DET_ELEVATION_109 "measured elevation of the detection";
CM_ SG_ 667 DET_ELEVATION_ERR_109 "RMSE or standard deviation of the measured elevation  of the detection";
CM_ SG_ 667 DET_RCS_109 "Radar Cross Section or Amplitude, is a measure of how detectable an object is by radar. A larger RCS indicates that an object is more easily detected.";
CM_ SG_ 667 DET_BI_STATIC_FLAG_109 "1 if detection is bi-static 0 otherwise";
CM_ SG_ 667 DET_SUPER_RES_TARGET_109 "flasg is set if the detection is super resolution target";
CM_ SG_ 667 DET_SNR_109 "The signal to noise ratio (SNR) of the radar detection";
CM_ SG_ 667 DET_EXISTENCE_PROB_109 "Existence probability of the detection not based on history. Value does  not depend on any past experience with similar detections.

ote Use as confidence measure where a low value means less confidence
and a high value indicates strong confidence.";
CM_ SG_ 667 DET_HVC_FLAG_109 "Core2 Vehicle clutter flag";
CM_ SG_ 667 DET_CONFD_AZIMUTH_109 "Define the Confidence of Azimuth for Detection ";
CM_ SG_ 667 DET_CONFD_ELEVATION_109 "Define the Confidence of Elevation for the Detection ";
CM_ SG_ 667 DET_BI_STATIC_FLAG_110 "1 if detection is bi-static 0 otherwise";
CM_ SG_ 667 DET_BI_STATIC_FLAG_111 "1 if detection is bi-static 0 otherwise";
CM_ SG_ 667 DET_BI_STATIC_FLAG_112 "1 if detection is bi-static 0 otherwise";
CM_ SG_ 667 DET_MH_SCAN_INDEX_4LSB_109_112 "Scan index of the measured detection";
CM_ SG_ 667 DET_MH_CYCLE_COUNTER_109_112 "Detection Alive Counter";
CM_ SG_ 668 DET_RANGE_113 " measured position  of the detection";
CM_ SG_ 668 DET_RANGE_ERR_113 "RMSE or standard deviation of the measured angle  of the detection";
CM_ SG_ 668 DET_RANGE_VELOCITY_113 "Radial velocity of the detection positive in direction to the sensor";
CM_ SG_ 668 DET_RANGE_VELOCITY_ERR_113 "RMSE or standard deviation of the measure radial velocity of the detection";
CM_ SG_ 668 DET_AZIMUTH_113 "Measured angle  of the detection";
CM_ SG_ 668 DET_AZIMUTH_ERR_113 "RMSE or standard deviation of the measured angle  of the detection";
CM_ SG_ 668 DET_ELEVATION_113 "measured elevation of the detection";
CM_ SG_ 668 DET_ELEVATION_ERR_113 "RMSE or standard deviation of the measured elevation  of the detection";
CM_ SG_ 668 DET_RCS_113 "Radar Cross Section or Amplitude, is a measure of how detectable an object is by radar. A larger RCS indicates that an object is more easily detected.";
CM_ SG_ 668 DET_BI_STATIC_FLAG_113 "1 if detection is bi-static 0 otherwise";
CM_ SG_ 668 DET_SUPER_RES_TARGET_113 "flasg is set if the detection is super resolution target";
CM_ SG_ 668 DET_SNR_113 "The signal to noise ratio (SNR) of the radar detection";
CM_ SG_ 668 DET_EXISTENCE_PROB_113 "Existence probability of the detection not based on history. Value does  not depend on any past experience with similar detections.

ote Use as confidence measure where a low value means less confidence
and a high value indicates strong confidence.";
CM_ SG_ 668 DET_HVC_FLAG_113 "Core2 Vehicle clutter flag";
CM_ SG_ 668 DET_CONFD_AZIMUTH_113 "Define the Confidence of Azimuth for Detection ";
CM_ SG_ 668 DET_CONFD_ELEVATION_113 "Define the Confidence of Elevation for the Detection ";
CM_ SG_ 668 DET_BI_STATIC_FLAG_114 "1 if detection is bi-static 0 otherwise";
CM_ SG_ 668 DET_BI_STATIC_FLAG_115 "1 if detection is bi-static 0 otherwise";
CM_ SG_ 668 DET_BI_STATIC_FLAG_116 "1 if detection is bi-static 0 otherwise";
CM_ SG_ 668 DET_MH_SCAN_INDEX_4LSB_113_116 "Scan index of the measured detection";
CM_ SG_ 668 DET_MH_CYCLE_COUNTER_113_116 "Detection Alive Counter";
CM_ SG_ 669 DET_RANGE_117 " measured position  of the detection";
CM_ SG_ 669 DET_RANGE_ERR_117 "RMSE or standard deviation of the measured angle  of the detection";
CM_ SG_ 669 DET_RANGE_VELOCITY_117 "Radial velocity of the detection positive in direction to the sensor";
CM_ SG_ 669 DET_RANGE_VELOCITY_ERR_117 "RMSE or standard deviation of the measure radial velocity of the detection";
CM_ SG_ 669 DET_AZIMUTH_117 "Measured angle  of the detection";
CM_ SG_ 669 DET_AZIMUTH_ERR_117 "RMSE or standard deviation of the measured angle  of the detection";
CM_ SG_ 669 DET_ELEVATION_117 "measured elevation of the detection";
CM_ SG_ 669 DET_ELEVATION_ERR_117 "RMSE or standard deviation of the measured elevation  of the detection";
CM_ SG_ 669 DET_RCS_117 "Radar Cross Section or Amplitude, is a measure of how detectable an object is by radar. A larger RCS indicates that an object is more easily detected.";
CM_ SG_ 669 DET_BI_STATIC_FLAG_117 "1 if detection is bi-static 0 otherwise";
CM_ SG_ 669 DET_SUPER_RES_TARGET_117 "flasg is set if the detection is super resolution target";
CM_ SG_ 669 DET_SNR_117 "The signal to noise ratio (SNR) of the radar detection";
CM_ SG_ 669 DET_EXISTENCE_PROB_117 "Existence probability of the detection not based on history. Value does  not depend on any past experience with similar detections.

ote Use as confidence measure where a low value means less confidence
and a high value indicates strong confidence.";
CM_ SG_ 669 DET_HVC_FLAG_117 "Core2 Vehicle clutter flag";
CM_ SG_ 669 DET_CONFD_AZIMUTH_117 "Define the Confidence of Azimuth for Detection ";
CM_ SG_ 669 DET_CONFD_ELEVATION_117 "Define the Confidence of Elevation for the Detection ";
CM_ SG_ 669 DET_BI_STATIC_FLAG_118 "1 if detection is bi-static 0 otherwise";
CM_ SG_ 669 DET_BI_STATIC_FLAG_119 "1 if detection is bi-static 0 otherwise";
CM_ SG_ 669 DET_BI_STATIC_FLAG_120 "1 if detection is bi-static 0 otherwise";
CM_ SG_ 669 DET_MH_SCAN_INDEX_4LSB_117_120 "Scan index of the measured detection";
CM_ SG_ 669 DET_MH_CYCLE_COUNTER_117_120 "Detection Alive Counter";
CM_ SG_ 670 DET_RANGE_121 " measured position  of the detection";
CM_ SG_ 670 DET_RANGE_ERR_121 "RMSE or standard deviation of the measured angle  of the detection";
CM_ SG_ 670 DET_RANGE_VELOCITY_121 "Radial velocity of the detection positive in direction to the sensor";
CM_ SG_ 670 DET_RANGE_VELOCITY_ERR_121 "RMSE or standard deviation of the measure radial velocity of the detection";
CM_ SG_ 670 DET_AZIMUTH_121 "Measured angle  of the detection";
CM_ SG_ 670 DET_AZIMUTH_ERR_121 "RMSE or standard deviation of the measured angle  of the detection";
CM_ SG_ 670 DET_ELEVATION_121 "measured elevation of the detection";
CM_ SG_ 670 DET_ELEVATION_ERR_121 "RMSE or standard deviation of the measured elevation  of the detection";
CM_ SG_ 670 DET_RCS_121 "Radar Cross Section or Amplitude, is a measure of how detectable an object is by radar. A larger RCS indicates that an object is more easily detected.";
CM_ SG_ 670 DET_BI_STATIC_FLAG_121 "1 if detection is bi-static 0 otherwise";
CM_ SG_ 670 DET_SUPER_RES_TARGET_121 "flasg is set if the detection is super resolution target";
CM_ SG_ 670 DET_SNR_121 "The signal to noise ratio (SNR) of the radar detection";
CM_ SG_ 670 DET_EXISTENCE_PROB_121 "Existence probability of the detection not based on history. Value does  not depend on any past experience with similar detections.

ote Use as confidence measure where a low value means less confidence
and a high value indicates strong confidence.";
CM_ SG_ 670 DET_HVC_FLAG_121 "Core2 Vehicle clutter flag";
CM_ SG_ 670 DET_CONFD_AZIMUTH_121 "Define the Confidence of Azimuth for Detection ";
CM_ SG_ 670 DET_CONFD_ELEVATION_121 "Define the Confidence of Elevation for the Detection ";
CM_ SG_ 670 DET_BI_STATIC_FLAG_122 "1 if detection is bi-static 0 otherwise";
CM_ SG_ 670 DET_BI_STATIC_FLAG_123 "1 if detection is bi-static 0 otherwise";
CM_ SG_ 670 DET_BI_STATIC_FLAG_124 "1 if detection is bi-static 0 otherwise";
CM_ SG_ 670 DET_MH_SCAN_INDEX_4LSB_121_124 "Scan index of the measured detection";
CM_ SG_ 670 DET_MH_CYCLE_COUNTER_121_124 "Detection Alive Counter";
CM_ SG_ 671 DET_RANGE_125 " measured position  of the detection";
CM_ SG_ 671 DET_RANGE_ERR_125 "RMSE or standard deviation of the measured angle  of the detection";
CM_ SG_ 671 DET_RANGE_VELOCITY_125 "Radial velocity of the detection positive in direction to the sensor";
CM_ SG_ 671 DET_RANGE_VELOCITY_ERR_125 "RMSE or standard deviation of the measure radial velocity of the detection";
CM_ SG_ 671 DET_AZIMUTH_125 "Measured angle  of the detection";
CM_ SG_ 671 DET_AZIMUTH_ERR_125 "RMSE or standard deviation of the measured angle  of the detection";
CM_ SG_ 671 DET_ELEVATION_125 "measured elevation of the detection";
CM_ SG_ 671 DET_ELEVATION_ERR_125 "RMSE or standard deviation of the measured elevation  of the detection";
CM_ SG_ 671 DET_RCS_125 "Radar Cross Section or Amplitude, is a measure of how detectable an object is by radar. A larger RCS indicates that an object is more easily detected.";
CM_ SG_ 671 DET_BI_STATIC_FLAG_125 "1 if detection is bi-static 0 otherwise";
CM_ SG_ 671 DET_SUPER_RES_TARGET_125 "flasg is set if the detection is super resolution target";
CM_ SG_ 671 DET_SNR_125 "The signal to noise ratio (SNR) of the radar detection";
CM_ SG_ 671 DET_EXISTENCE_PROB_125 "Existence probability of the detection not based on history. Value does  not depend on any past experience with similar detections.

ote Use as confidence measure where a low value means less confidence
and a high value indicates strong confidence.";
CM_ SG_ 671 DET_HVC_FLAG_125 "Core2 Vehicle clutter flag";
CM_ SG_ 671 DET_CONFD_AZIMUTH_125 "Define the Confidence of Azimuth for Detection ";
CM_ SG_ 671 DET_CONFD_ELEVATION_125 "Define the Confidence of Elevation for the Detection ";
CM_ SG_ 671 DET_BI_STATIC_FLAG_126 "1 if detection is bi-static 0 otherwise";
CM_ SG_ 671 DET_BI_STATIC_FLAG_127 "1 if detection is bi-static 0 otherwise";
CM_ SG_ 671 DET_BI_STATIC_FLAG_128 "1 if detection is bi-static 0 otherwise";
CM_ SG_ 671 DET_MH_SCAN_INDEX_4LSB_125_128 "Scan index of the measured detection";
CM_ SG_ 671 DET_MH_CYCLE_COUNTER_125_128 "Detection Alive Counter";
BA_DEF_ BO_  "CanTpBs" INT 0 255;
BA_DEF_ BO_  "DiagRequest" ENUM  "No","Yes";
BA_DEF_ BO_  "DiagResponse" ENUM  "No","Yes";
BA_DEF_ BO_  "E2EDataId" INT 0 65535;
BA_DEF_ BO_  "E2EDataLength" INT 0 65535;
BA_DEF_ BO_  "E2EProfile" STRING ;
BA_DEF_ BO_  "EventRateOfChange" INT 10 10000;
BA_DEF_ BO_  "GenMsgCycleTime" INT 0 100000;
BA_DEF_ BO_  "GenMsgILSupport" ENUM  "No","Yes";
BA_DEF_ BO_  "GenMsgNrOfRepetition" INT 0 100;
BA_DEF_ BO_  "GenMsgSendType" ENUM  "FixedPeriodic","Event","EnabledPeriodic","NotUsed","NotUsed","EventPeriodic","NotUsed","NotUsed","NoMsgSendType";
BA_DEF_ BO_  "MessageGateway" ENUM  "No","Yes";
BA_DEF_ BO_  "NetworkInitialization" ENUM  "No","Yes";
BA_DEF_ BO_  "SCP_AuthInfoTxLength" INT 0 512;
BA_DEF_ BO_  "SCP_DataId" INT 0 65535;
BA_DEF_ BO_  "SCP_FreshnessValueId" INT 0 65535;
BA_DEF_ BO_  "SCP_FreshnessValueLength" INT 0 512;
BA_DEF_ BO_  "SCP_FreshnessValueTxLength" INT 0 512;
BA_DEF_ BO_  "SC_Message" ENUM  "No","Yes","Yes, split message";
BA_DEF_ BO_  "VFrameFormat" ENUM  "StandardCAN","ExtendedCAN","reserved","reserved","reserved","reserved","reserved","reserved","reserved","reserved","reserved","reserved","reserved","reserved","StandardCAN_FD","ExtendedCAN_FD";
BA_DEF_ SG_  "GenSigCmt" STRING ;
BA_DEF_ SG_  "GenSigCycleTime" INT 0 0;
BA_DEF_ SG_  "GenSigSendType" ENUM  "Cyclic","OnWrite","vector_leerstring","OnChange","vector_leerstring","IfActive","vector_leerstring","NoSigSendType";
BA_DEF_ SG_  "GenSigStartValue" INT 0 1000000000;
BA_DEF_ SG_  "GenSigTimeoutTime" INT 0 0;
BA_DEF_ SG_  "InvalidValue" STRING ;
BA_DEF_DEF_  "CanTpBs" 255;
BA_DEF_DEF_  "DiagRequest" "No";
BA_DEF_DEF_  "DiagResponse" "No";
BA_DEF_DEF_  "E2EDataId" 0;
BA_DEF_DEF_  "E2EDataLength" 0;
BA_DEF_DEF_  "E2EProfile" "";
BA_DEF_DEF_  "EventRateOfChange" 10000;
BA_DEF_DEF_  "GenMsgCycleTime" 0;
BA_DEF_DEF_  "GenMsgILSupport" "Yes";
BA_DEF_DEF_  "GenMsgNrOfRepetition" 0;
BA_DEF_DEF_  "GenMsgSendType" "NoMsgSendType";
BA_DEF_DEF_  "MessageGateway" "No";
BA_DEF_DEF_  "NetworkInitialization" "Yes";
BA_DEF_DEF_  "SCP_AuthInfoTxLength" 28;
BA_DEF_DEF_  "SCP_DataId" 0;
BA_DEF_DEF_  "SCP_FreshnessValueId" 0;
BA_DEF_DEF_  "SCP_FreshnessValueLength" 48;
BA_DEF_DEF_  "SCP_FreshnessValueTxLength" 4;
BA_DEF_DEF_  "SC_Message" "No";
BA_DEF_DEF_  "VFrameFormat" "StandardCAN_FD";
BA_DEF_DEF_  "GenSigCmt" "";
BA_DEF_DEF_  "GenSigCycleTime" 0;
BA_DEF_DEF_  "GenSigSendType" "NoSigSendType";
BA_DEF_DEF_  "GenSigStartValue" 0;
BA_DEF_DEF_  "GenSigTimeoutTime" 0;
BA_DEF_DEF_  "InvalidValue" "";
BA_ "GenMsgSendType" BO_ 662 1;
BA_ "GenMsgSendType" BO_ 663 1;
BA_ "GenMsgSendType" BO_ 664 1;
BA_ "GenMsgSendType" BO_ 665 1;
BA_ "GenMsgSendType" BO_ 666 1;
BA_ "GenMsgSendType" BO_ 667 1;
BA_ "GenMsgSendType" BO_ 668 1;
BA_ "GenMsgSendType" BO_ 669 1;
BA_ "GenMsgSendType" BO_ 670 1;
BA_ "GenMsgSendType" BO_ 671 1;
BA_ "DiagRequest" BO_ 2564469232 1;
BA_ "GenMsgSendType" BO_ 2564469232 1;
BA_ "VFrameFormat" BO_ 2564469232 15;
BA_ "DiagRequest" BO_ 2564469233 1;
BA_ "GenMsgSendType" BO_ 2564469233 1;
BA_ "VFrameFormat" BO_ 2564469233 15;
BA_ "GenMsgSendType" BO_ 40 1;
BA_ "GenMsgCycleTime" BO_ 2566834865 1000;
BA_ "GenMsgSendType" BO_ 2566834865 0;
BA_ "VFrameFormat" BO_ 2566834865 3;
BA_ "GenMsgCycleTime" BO_ 2566834864 1000;
BA_ "GenMsgSendType" BO_ 2566834864 0;
BA_ "VFrameFormat" BO_ 2566834864 3;
BA_ "GenMsgCycleTime" BO_ 2566834896 1000;
BA_ "GenMsgSendType" BO_ 2566834896 0;
BA_ "VFrameFormat" BO_ 2566834896 3;
BA_ "GenMsgCycleTime" BO_ 2566834920 1000;
BA_ "GenMsgSendType" BO_ 2566834920 0;
BA_ "VFrameFormat" BO_ 2566834920 3;
BA_ "GenMsgCycleTime" BO_ 2566834848 1000;
BA_ "GenMsgSendType" BO_ 2566834848 0;
BA_ "VFrameFormat" BO_ 2566834848 3;
BA_ "GenMsgCycleTime" BO_ 2566832407 1000;
BA_ "GenMsgSendType" BO_ 2566832407 0;
BA_ "VFrameFormat" BO_ 2566832407 3;
BA_ "GenMsgCycleTime" BO_ 2564882209 1000;
BA_ "GenMsgSendType" BO_ 2564882209 0;
BA_ "VFrameFormat" BO_ 2564882209 3;
BA_ "MessageGateway" BO_ 2365443095 1;
BA_ "GenMsgCycleTime" BO_ 2365443095 1000;
BA_ "GenMsgSendType" BO_ 2365443095 0;
BA_ "VFrameFormat" BO_ 2365443095 3;
BA_ "GenMsgCycleTime" BO_ 2565867787 10;
BA_ "GenMsgSendType" BO_ 2565867787 0;
BA_ "VFrameFormat" BO_ 2565867787 3;
BA_ "GenMsgCycleTime" BO_ 2566803211 100;
BA_ "GenMsgSendType" BO_ 2566803211 0;
BA_ "VFrameFormat" BO_ 2566803211 3;
BA_ "GenMsgCycleTime" BO_ 2298375691 20;
BA_ "GenMsgSendType" BO_ 2298375691 0;
BA_ "VFrameFormat" BO_ 2298375691 3;
BA_ "GenMsgCycleTime" BO_ 2566767627 100;
BA_ "GenMsgSendType" BO_ 2566767627 0;
BA_ "VFrameFormat" BO_ 2566767627 3;
BA_ "GenMsgCycleTime" BO_ 2566831883 100;
BA_ "GenMsgSendType" BO_ 2566831883 0;
BA_ "VFrameFormat" BO_ 2566831883 3;
BA_ "GenMsgCycleTime" BO_ 2565865739 100;
BA_ "GenMsgSendType" BO_ 2565865739 0;
BA_ "VFrameFormat" BO_ 2565865739 3;
BA_ "GenMsgCycleTime" BO_ 2565866752 100;
BA_ "GenMsgSendType" BO_ 2565866752 0;
BA_ "VFrameFormat" BO_ 2565866752 3;
BA_ "GenMsgCycleTime" BO_ 2565866755 100;
BA_ "GenMsgSendType" BO_ 2565866755 0;
BA_ "VFrameFormat" BO_ 2565866755 3;
BA_ "GenMsgCycleTime" BO_ 2364539648 50;
BA_ "GenMsgSendType" BO_ 2364539648 0;
BA_ "VFrameFormat" BO_ 2364539648 3;
BA_ "GenMsgCycleTime" BO_ 2364539904 10;
BA_ "GenMsgSendType" BO_ 2364539904 0;
BA_ "VFrameFormat" BO_ 2364539904 3;
BA_ "GenMsgCycleTime" BO_ 2566844672 20;
BA_ "GenMsgSendType" BO_ 2566844672 0;
BA_ "VFrameFormat" BO_ 2566844672 3;
BA_ "GenMsgCycleTime" BO_ 2566769991 200;
BA_ "GenMsgSendType" BO_ 2566769991 0;
BA_ "VFrameFormat" BO_ 2566769991 3;
BA_ "GenMsgSendType" BO_ 2561277511 7;
BA_ "VFrameFormat" BO_ 2561277511 3;
BA_ "GenMsgCycleTime" BO_ 2349596231 50;
BA_ "GenMsgSendType" BO_ 2349596231 0;
BA_ "VFrameFormat" BO_ 2349596231 3;
BA_ "VFrameFormat" BO_ 2164214480 1;
BA_ "GenMsgCycleTime" BO_ 2164214480 50;
BA_ "GenMsgSendType" BO_ 2164214480 0;
BA_ "GenMsgCycleTime" BO_ 2364671665 50;
BA_ "GenMsgSendType" BO_ 2364671665 0;
BA_ "VFrameFormat" BO_ 2364671665 3;
BA_ "GenMsgCycleTime" BO_ 2364671664 50;
BA_ "GenMsgSendType" BO_ 2364671664 0;
BA_ "VFrameFormat" BO_ 2364671664 3;
BA_ "GenMsgCycleTime" BO_ 2566890672 50;
BA_ "GenMsgSendType" BO_ 2566890672 0;
BA_ "VFrameFormat" BO_ 2566890672 3;
BA_ "GenMsgCycleTime" BO_ 2566806526 100;
BA_ "GenMsgSendType" BO_ 2566806526 0;
BA_ "VFrameFormat" BO_ 2566806526 3;
BA_ "GenMsgCycleTime" BO_ 284166120 50;
BA_ "GenMsgSendType" BO_ 284166120 0;
BA_ "GenSigStartValue" SG_ 662 DET_RANGE_VELOCITY_089 16384;
BA_ "GenSigStartValue" SG_ 662 DET_RCS_089 128;
BA_ "GenSigStartValue" SG_ 662 DET_RANGE_VELOCITY_090 16384;
BA_ "GenSigStartValue" SG_ 662 DET_RCS_090 128;
BA_ "GenSigStartValue" SG_ 662 DET_RANGE_VELOCITY_091 16384;
BA_ "GenSigStartValue" SG_ 662 DET_RCS_091 128;
BA_ "GenSigStartValue" SG_ 662 DET_RANGE_VELOCITY_092 16384;
BA_ "GenSigStartValue" SG_ 662 DET_RCS_092 128;
BA_ "GenSigStartValue" SG_ 663 DET_RANGE_VELOCITY_093 16384;
BA_ "GenSigStartValue" SG_ 663 DET_RCS_093 128;
BA_ "GenSigStartValue" SG_ 663 DET_RANGE_VELOCITY_094 16384;
BA_ "GenSigStartValue" SG_ 663 DET_RCS_094 128;
BA_ "GenSigStartValue" SG_ 663 DET_RANGE_VELOCITY_095 16384;
BA_ "GenSigStartValue" SG_ 663 DET_RCS_095 128;
BA_ "GenSigStartValue" SG_ 663 DET_RANGE_VELOCITY_096 16384;
BA_ "GenSigStartValue" SG_ 663 DET_RCS_096 128;
BA_ "GenSigStartValue" SG_ 664 DET_RANGE_VELOCITY_097 16384;
BA_ "GenSigStartValue" SG_ 664 DET_RCS_097 128;
BA_ "GenSigStartValue" SG_ 664 DET_RANGE_VELOCITY_098 16384;
BA_ "GenSigStartValue" SG_ 664 DET_RCS_098 128;
BA_ "GenSigStartValue" SG_ 664 DET_RANGE_VELOCITY_099 16384;
BA_ "GenSigStartValue" SG_ 664 DET_RCS_099 128;
BA_ "GenSigStartValue" SG_ 664 DET_RANGE_VELOCITY_100 16384;
BA_ "GenSigStartValue" SG_ 664 DET_RCS_100 128;
BA_ "GenSigStartValue" SG_ 665 DET_RANGE_VELOCITY_101 16384;
BA_ "GenSigStartValue" SG_ 665 DET_RCS_101 128;
BA_ "GenSigStartValue" SG_ 665 DET_RANGE_VELOCITY_102 16384;
BA_ "GenSigStartValue" SG_ 665 DET_RCS_102 128;
BA_ "GenSigStartValue" SG_ 665 DET_RANGE_VELOCITY_103 16384;
BA_ "GenSigStartValue" SG_ 665 DET_RCS_103 128;
BA_ "GenSigStartValue" SG_ 665 DET_RANGE_VELOCITY_104 16384;
BA_ "GenSigStartValue" SG_ 665 DET_RCS_104 128;
BA_ "GenSigStartValue" SG_ 666 DET_RANGE_VELOCITY_105 16384;
BA_ "GenSigStartValue" SG_ 666 DET_RCS_105 128;
BA_ "GenSigStartValue" SG_ 666 DET_RANGE_VELOCITY_106 16384;
BA_ "GenSigStartValue" SG_ 666 DET_RCS_106 128;
BA_ "GenSigStartValue" SG_ 666 DET_RANGE_VELOCITY_107 16384;
BA_ "GenSigStartValue" SG_ 666 DET_RCS_107 128;
BA_ "GenSigStartValue" SG_ 666 DET_RANGE_VELOCITY_108 16384;
BA_ "GenSigStartValue" SG_ 666 DET_RCS_108 128;
BA_ "GenSigStartValue" SG_ 667 DET_RANGE_VELOCITY_109 16384;
BA_ "GenSigStartValue" SG_ 667 DET_RCS_109 128;
BA_ "GenSigStartValue" SG_ 667 DET_RANGE_VELOCITY_110 16384;
BA_ "GenSigStartValue" SG_ 667 DET_RCS_110 128;
BA_ "GenSigStartValue" SG_ 667 DET_RANGE_VELOCITY_111 16384;
BA_ "GenSigStartValue" SG_ 667 DET_RCS_111 128;
BA_ "GenSigStartValue" SG_ 667 DET_RANGE_VELOCITY_112 16384;
BA_ "GenSigStartValue" SG_ 667 DET_RCS_112 128;
BA_ "GenSigStartValue" SG_ 668 DET_RANGE_VELOCITY_113 16384;
BA_ "GenSigStartValue" SG_ 668 DET_RCS_113 128;
BA_ "GenSigStartValue" SG_ 668 DET_RANGE_VELOCITY_114 16384;
BA_ "GenSigStartValue" SG_ 668 DET_RCS_114 128;
BA_ "GenSigStartValue" SG_ 668 DET_RANGE_VELOCITY_115 16384;
BA_ "GenSigStartValue" SG_ 668 DET_RCS_115 128;
BA_ "GenSigStartValue" SG_ 668 DET_RANGE_VELOCITY_116 16384;
BA_ "GenSigStartValue" SG_ 668 DET_RCS_116 128;
BA_ "GenSigStartValue" SG_ 669 DET_RANGE_VELOCITY_117 16384;
BA_ "GenSigStartValue" SG_ 669 DET_RCS_117 128;
BA_ "GenSigStartValue" SG_ 669 DET_RANGE_VELOCITY_118 16384;
BA_ "GenSigStartValue" SG_ 669 DET_RCS_118 128;
BA_ "GenSigStartValue" SG_ 669 DET_RANGE_VELOCITY_119 16384;
BA_ "GenSigStartValue" SG_ 669 DET_RCS_119 128;
BA_ "GenSigStartValue" SG_ 669 DET_RANGE_VELOCITY_120 16384;
BA_ "GenSigStartValue" SG_ 669 DET_RCS_120 128;
BA_ "GenSigStartValue" SG_ 670 DET_RANGE_VELOCITY_121 16384;
BA_ "GenSigStartValue" SG_ 670 DET_RCS_121 128;
BA_ "GenSigStartValue" SG_ 670 DET_RANGE_VELOCITY_122 16384;
BA_ "GenSigStartValue" SG_ 670 DET_RCS_122 128;
BA_ "GenSigStartValue" SG_ 670 DET_RANGE_VELOCITY_123 16384;
BA_ "GenSigStartValue" SG_ 670 DET_RCS_123 128;
BA_ "GenSigStartValue" SG_ 670 DET_RANGE_VELOCITY_124 16384;
BA_ "GenSigStartValue" SG_ 670 DET_RCS_124 128;
BA_ "GenSigStartValue" SG_ 671 DET_RANGE_VELOCITY_125 16384;
BA_ "GenSigStartValue" SG_ 671 DET_RCS_125 128;
BA_ "GenSigStartValue" SG_ 671 DET_RANGE_VELOCITY_126 16384;
BA_ "GenSigStartValue" SG_ 671 DET_RCS_126 128;
BA_ "GenSigStartValue" SG_ 671 DET_RANGE_VELOCITY_127 16384;
BA_ "GenSigStartValue" SG_ 671 DET_RCS_127 128;
BA_ "GenSigStartValue" SG_ 671 DET_RANGE_VELOCITY_128 16384;
BA_ "GenSigStartValue" SG_ 671 DET_RCS_128 128;
VAL_ 662 DET_CONFD_AZIMUTH_089 0 "High" 1 "MidHigh" 2 "MidLow" 3 "Low" ;
VAL_ 662 DET_CONFD_ELEVATION_089 0 "High" 1 "MidHigh" 2 "MidLow" 3 "Low" ;
VAL_ 662 DET_IDM_089 0 "Not_IDM_Output" 1 "IDM_Output" ;
VAL_ 662 DET_MTD_089 0 "Not_MTD_Output" 1 "MTD_Output" ;
VAL_ 662 DET_BELOW_RAIN_THOLD_089 0 "DetBelowRainThold" 1 "DetAboveRainThold" ;
VAL_ 662 DET_CONFD_AZIMUTH_090 0 "High" 1 "MidHigh" 2 "MidLow" 3 "Low" ;
VAL_ 662 DET_CONFD_ELEVATION_090 0 "High" 1 "MidHigh" 2 "MidLow" 3 "Low" ;
VAL_ 662 DET_IDM_090 0 "Not_IDM_Output" 1 "IDM_Output" ;
VAL_ 662 DET_MTD_090 0 "Not_MTD_Output" 1 "MTD_Output" ;
VAL_ 662 DET_BELOW_RAIN_THOLD_090 0 "DetBelowRainThold" 1 "DetAboveRainThold" ;
VAL_ 662 DET_CONFD_AZIMUTH_091 0 "High" 1 "MidHigh" 2 "MidLow" 3 "Low" ;
VAL_ 662 DET_CONFD_ELEVATION_091 0 "High" 1 "MidHigh" 2 "MidLow" 3 "Low" ;
VAL_ 662 DET_IDM_091 0 "Not_IDM_Output" 1 "IDM_Output" ;
VAL_ 662 DET_MTD_091 0 "Not_MTD_Output" 1 "MTD_Output" ;
VAL_ 662 DET_BELOW_RAIN_THOLD_091 0 "DetBelowRainThold" 1 "DetAboveRainThold" ;
VAL_ 662 DET_IDM_092 0 "Not_IDM_Output" 1 "IDM_Output" ;
VAL_ 662 DET_MTD_092 0 "Not_MTD_Output" 1 "MTD_Output" ;
VAL_ 662 DET_BELOW_RAIN_THOLD_092 0 "DetBelowRainThold" 1 "DetAboveRainThold" ;
VAL_ 663 DET_CONFD_AZIMUTH_093 0 "High" 1 "MidHigh" 2 "MidLow" 3 "Low" ;
VAL_ 663 DET_CONFD_ELEVATION_093 0 "High" 1 "MidHigh" 2 "MidLow" 3 "Low" ;
VAL_ 663 DET_IDM_093 0 "Not_IDM_Output" 1 "IDM_Output" ;
VAL_ 663 DET_MTD_093 0 "Not_MTD_Output" 1 "MTD_Output" ;
VAL_ 663 DET_BELOW_RAIN_THOLD_093 0 "DetBelowRainThold" 1 "DetAboveRainThold" ;
VAL_ 663 DET_CONFD_AZIMUTH_094 0 "High" 1 "MidHigh" 2 "MidLow" 3 "Low" ;
VAL_ 663 DET_CONFD_ELEVATION_094 0 "High" 1 "MidHigh" 2 "MidLow" 3 "Low" ;
VAL_ 663 DET_IDM_094 0 "Not_IDM_Output" 1 "IDM_Output" ;
VAL_ 663 DET_MTD_094 0 "Not_MTD_Output" 1 "MTD_Output" ;
VAL_ 663 DET_BELOW_RAIN_THOLD_094 0 "DetBelowRainThold" 1 "DetAboveRainThold" ;
VAL_ 663 DET_CONFD_AZIMUTH_095 0 "High" 1 "MidHigh" 2 "MidLow" 3 "Low" ;
VAL_ 663 DET_CONFD_ELEVATION_095 0 "High" 1 "MidHigh" 2 "MidLow" 3 "Low" ;
VAL_ 663 DET_IDM_095 0 "Not_IDM_Output" 1 "IDM_Output" ;
VAL_ 663 DET_MTD_095 0 "Not_MTD_Output" 1 "MTD_Output" ;
VAL_ 663 DET_BELOW_RAIN_THOLD_095 0 "DetBelowRainThold" 1 "DetAboveRainThold" ;
VAL_ 663 DET_IDM_096 0 "Not_IDM_Output" 1 "IDM_Output" ;
VAL_ 663 DET_MTD_096 0 "Not_MTD_Output" 1 "MTD_Output" ;
VAL_ 663 DET_BELOW_RAIN_THOLD_096 0 "DetBelowRainThold" 1 "DetAboveRainThold" ;
VAL_ 664 DET_CONFD_AZIMUTH_097 0 "High" 1 "MidHigh" 2 "MidLow" 3 "Low" ;
VAL_ 664 DET_CONFD_ELEVATION_097 0 "High" 1 "MidHigh" 2 "MidLow" 3 "Low" ;
VAL_ 664 DET_IDM_097 0 "Not_IDM_Output" 1 "IDM_Output" ;
VAL_ 664 DET_MTD_097 0 "Not_MTD_Output" 1 "MTD_Output" ;
VAL_ 664 DET_BELOW_RAIN_THOLD_097 0 "DetBelowRainThold" 1 "DetAboveRainThold" ;
VAL_ 664 DET_CONFD_AZIMUTH_098 0 "High" 1 "MidHigh" 2 "MidLow" 3 "Low" ;
VAL_ 664 DET_CONFD_ELEVATION_098 0 "High" 1 "MidHigh" 2 "MidLow" 3 "Low" ;
VAL_ 664 DET_IDM_098 0 "Not_IDM_Output" 1 "IDM_Output" ;
VAL_ 664 DET_MTD_098 0 "Not_MTD_Output" 1 "MTD_Output" ;
VAL_ 664 DET_BELOW_RAIN_THOLD_098 0 "DetBelowRainThold" 1 "DetAboveRainThold" ;
VAL_ 664 DET_CONFD_AZIMUTH_099 0 "High" 1 "MidHigh" 2 "MidLow" 3 "Low" ;
VAL_ 664 DET_CONFD_ELEVATION_099 0 "High" 1 "MidHigh" 2 "MidLow" 3 "Low" ;
VAL_ 664 DET_IDM_099 0 "Not_IDM_Output" 1 "IDM_Output" ;
VAL_ 664 DET_MTD_099 0 "Not_MTD_Output" 1 "MTD_Output" ;
VAL_ 664 DET_BELOW_RAIN_THOLD_099 0 "DetBelowRainThold" 1 "DetAboveRainThold" ;
VAL_ 664 DET_IDM_100 0 "Not_IDM_Output" 1 "IDM_Output" ;
VAL_ 664 DET_MTD_100 0 "Not_MTD_Output" 1 "MTD_Output" ;
VAL_ 664 DET_BELOW_RAIN_THOLD_100 0 "DetBelowRainThold" 1 "DetAboveRainThold" ;
VAL_ 665 DET_CONFD_AZIMUTH_101 0 "High" 1 "MidHigh" 2 "MidLow" 3 "Low" ;
VAL_ 665 DET_CONFD_ELEVATION_101 0 "High" 1 "MidHigh" 2 "MidLow" 3 "Low" ;
VAL_ 665 DET_IDM_101 0 "Not_IDM_Output" 1 "IDM_Output" ;
VAL_ 665 DET_MTD_101 0 "Not_MTD_Output" 1 "MTD_Output" ;
VAL_ 665 DET_BELOW_RAIN_THOLD_101 0 "DetBelowRainThold" 1 "DetAboveRainThold" ;
VAL_ 665 DET_CONFD_AZIMUTH_102 0 "High" 1 "MidHigh" 2 "MidLow" 3 "Low" ;
VAL_ 665 DET_CONFD_ELEVATION_102 0 "High" 1 "MidHigh" 2 "MidLow" 3 "Low" ;
VAL_ 665 DET_IDM_102 0 "Not_IDM_Output" 1 "IDM_Output" ;
VAL_ 665 DET_MTD_102 0 "Not_MTD_Output" 1 "MTD_Output" ;
VAL_ 665 DET_BELOW_RAIN_THOLD_102 0 "DetBelowRainThold" 1 "DetAboveRainThold" ;
VAL_ 665 DET_CONFD_AZIMUTH_103 0 "High" 1 "MidHigh" 2 "MidLow" 3 "Low" ;
VAL_ 665 DET_CONFD_ELEVATION_103 0 "High" 1 "MidHigh" 2 "MidLow" 3 "Low" ;
VAL_ 665 DET_IDM_103 0 "Not_IDM_Output" 1 "IDM_Output" ;
VAL_ 665 DET_MTD_103 0 "Not_MTD_Output" 1 "MTD_Output" ;
VAL_ 665 DET_BELOW_RAIN_THOLD_103 0 "DetBelowRainThold" 1 "DetAboveRainThold" ;
VAL_ 665 DET_IDM_104 0 "Not_IDM_Output" 1 "IDM_Output" ;
VAL_ 665 DET_MTD_104 0 "Not_MTD_Output" 1 "MTD_Output" ;
VAL_ 665 DET_BELOW_RAIN_THOLD_104 0 "DetBelowRainThold" 1 "DetAboveRainThold" ;
VAL_ 666 DET_CONFD_AZIMUTH_105 0 "High" 1 "MidHigh" 2 "MidLow" 3 "Low" ;
VAL_ 666 DET_CONFD_ELEVATION_105 0 "High" 1 "MidHigh" 2 "MidLow" 3 "Low" ;
VAL_ 666 DET_IDM_105 0 "Not_IDM_Output" 1 "IDM_Output" ;
VAL_ 666 DET_MTD_105 0 "Not_MTD_Output" 1 "MTD_Output" ;
VAL_ 666 DET_BELOW_RAIN_THOLD_105 0 "DetBelowRainThold" 1 "DetAboveRainThold" ;
VAL_ 666 DET_CONFD_AZIMUTH_106 0 "High" 1 "MidHigh" 2 "MidLow" 3 "Low" ;
VAL_ 666 DET_CONFD_ELEVATION_106 0 "High" 1 "MidHigh" 2 "MidLow" 3 "Low" ;
VAL_ 666 DET_IDM_106 0 "Not_IDM_Output" 1 "IDM_Output" ;
VAL_ 666 DET_MTD_106 0 "Not_MTD_Output" 1 "MTD_Output" ;
VAL_ 666 DET_BELOW_RAIN_THOLD_106 0 "DetBelowRainThold" 1 "DetAboveRainThold" ;
VAL_ 666 DET_CONFD_AZIMUTH_107 0 "High" 1 "MidHigh" 2 "MidLow" 3 "Low" ;
VAL_ 666 DET_CONFD_ELEVATION_107 0 "High" 1 "MidHigh" 2 "MidLow" 3 "Low" ;
VAL_ 666 DET_IDM_107 0 "Not_IDM_Output" 1 "IDM_Output" ;
VAL_ 666 DET_MTD_107 0 "Not_MTD_Output" 1 "MTD_Output" ;
VAL_ 666 DET_BELOW_RAIN_THOLD_107 0 "DetBelowRainThold" 1 "DetAboveRainThold" ;
VAL_ 666 DET_IDM_108 0 "Not_IDM_Output" 1 "IDM_Output" ;
VAL_ 666 DET_MTD_108 0 "Not_MTD_Output" 1 "MTD_Output" ;
VAL_ 666 DET_BELOW_RAIN_THOLD_108 0 "DetBelowRainThold" 1 "DetAboveRainThold" ;
VAL_ 667 DET_CONFD_AZIMUTH_109 0 "High" 1 "MidHigh" 2 "MidLow" 3 "Low" ;
VAL_ 667 DET_CONFD_ELEVATION_109 0 "High" 1 "MidHigh" 2 "MidLow" 3 "Low" ;
VAL_ 667 DET_IDM_109 0 "Not_IDM_Output" 1 "IDM_Output" ;
VAL_ 667 DET_MTD_109 0 "Not_MTD_Output" 1 "MTD_Output" ;
VAL_ 667 DET_BELOW_RAIN_THOLD_109 0 "DetBelowRainThold" 1 "DetAboveRainThold" ;
VAL_ 667 DET_CONFD_AZIMUTH_110 0 "High" 1 "MidHigh" 2 "MidLow" 3 "Low" ;
VAL_ 667 DET_CONFD_ELEVATION_110 0 "High" 1 "MidHigh" 2 "MidLow" 3 "Low" ;
VAL_ 667 DET_IDM_110 0 "Not_IDM_Output" 1 "IDM_Output" ;
VAL_ 667 DET_MTD_110 0 "Not_MTD_Output" 1 "MTD_Output" ;
VAL_ 667 DET_BELOW_RAIN_THOLD_110 0 "DetBelowRainThold" 1 "DetAboveRainThold" ;
VAL_ 667 DET_CONFD_AZIMUTH_111 0 "High" 1 "MidHigh" 2 "MidLow" 3 "Low" ;
VAL_ 667 DET_CONFD_ELEVATION_111 0 "High" 1 "MidHigh" 2 "MidLow" 3 "Low" ;
VAL_ 667 DET_IDM_111 0 "Not_IDM_Output" 1 "IDM_Output" ;
VAL_ 667 DET_MTD_111 0 "Not_MTD_Output" 1 "MTD_Output" ;
VAL_ 667 DET_BELOW_RAIN_THOLD_111 0 "DetBelowRainThold" 1 "DetAboveRainThold" ;
VAL_ 667 DET_IDM_112 0 "Not_IDM_Output" 1 "IDM_Output" ;
VAL_ 667 DET_MTD_112 0 "Not_MTD_Output" 1 "MTD_Output" ;
VAL_ 667 DET_BELOW_RAIN_THOLD_112 0 "DetBelowRainThold" 1 "DetAboveRainThold" ;
VAL_ 668 DET_CONFD_AZIMUTH_113 0 "High" 1 "MidHigh" 2 "MidLow" 3 "Low" ;
VAL_ 668 DET_CONFD_ELEVATION_113 0 "High" 1 "MidHigh" 2 "MidLow" 3 "Low" ;
VAL_ 668 DET_IDM_113 0 "Not_IDM_Output" 1 "IDM_Output" ;
VAL_ 668 DET_MTD_113 0 "Not_MTD_Output" 1 "MTD_Output" ;
VAL_ 668 DET_BELOW_RAIN_THOLD_113 0 "DetBelowRainThold" 1 "DetAboveRainThold" ;
VAL_ 668 DET_CONFD_AZIMUTH_114 0 "High" 1 "MidHigh" 2 "MidLow" 3 "Low" ;
VAL_ 668 DET_CONFD_ELEVATION_114 0 "High" 1 "MidHigh" 2 "MidLow" 3 "Low" ;
VAL_ 668 DET_IDM_114 0 "Not_IDM_Output" 1 "IDM_Output" ;
VAL_ 668 DET_MTD_114 0 "Not_MTD_Output" 1 "MTD_Output" ;
VAL_ 668 DET_BELOW_RAIN_THOLD_114 0 "DetBelowRainThold" 1 "DetAboveRainThold" ;
VAL_ 668 DET_CONFD_AZIMUTH_115 0 "High" 1 "MidHigh" 2 "MidLow" 3 "Low" ;
VAL_ 668 DET_CONFD_ELEVATION_115 0 "High" 1 "MidHigh" 2 "MidLow" 3 "Low" ;
VAL_ 668 DET_IDM_115 0 "Not_IDM_Output" 1 "IDM_Output" ;
VAL_ 668 DET_MTD_115 0 "Not_MTD_Output" 1 "MTD_Output" ;
VAL_ 668 DET_BELOW_RAIN_THOLD_115 0 "DetBelowRainThold" 1 "DetAboveRainThold" ;
VAL_ 668 DET_IDM_116 0 "Not_IDM_Output" 1 "IDM_Output" ;
VAL_ 668 DET_MTD_116 0 "Not_MTD_Output" 1 "MTD_Output" ;
VAL_ 668 DET_BELOW_RAIN_THOLD_116 0 "DetBelowRainThold" 1 "DetAboveRainThold" ;
VAL_ 669 DET_CONFD_AZIMUTH_117 0 "High" 1 "MidHigh" 2 "MidLow" 3 "Low" ;
VAL_ 669 DET_CONFD_ELEVATION_117 0 "High" 1 "MidHigh" 2 "MidLow" 3 "Low" ;
VAL_ 669 DET_IDM_117 0 "Not_IDM_Output" 1 "IDM_Output" ;
VAL_ 669 DET_MTD_117 0 "Not_MTD_Output" 1 "MTD_Output" ;
VAL_ 669 DET_BELOW_RAIN_THOLD_117 0 "DetBelowRainThold" 1 "DetAboveRainThold" ;
VAL_ 669 DET_CONFD_AZIMUTH_118 0 "High" 1 "MidHigh" 2 "MidLow" 3 "Low" ;
VAL_ 669 DET_CONFD_ELEVATION_118 0 "High" 1 "MidHigh" 2 "MidLow" 3 "Low" ;
VAL_ 669 DET_IDM_118 0 "Not_IDM_Output" 1 "IDM_Output" ;
VAL_ 669 DET_MTD_118 0 "Not_MTD_Output" 1 "MTD_Output" ;
VAL_ 669 DET_BELOW_RAIN_THOLD_118 0 "DetBelowRainThold" 1 "DetAboveRainThold" ;
VAL_ 669 DET_CONFD_AZIMUTH_119 0 "High" 1 "MidHigh" 2 "MidLow" 3 "Low" ;
VAL_ 669 DET_CONFD_ELEVATION_119 0 "High" 1 "MidHigh" 2 "MidLow" 3 "Low" ;
VAL_ 669 DET_IDM_119 0 "Not_IDM_Output" 1 "IDM_Output" ;
VAL_ 669 DET_MTD_119 0 "Not_MTD_Output" 1 "MTD_Output" ;
VAL_ 669 DET_BELOW_RAIN_THOLD_119 0 "DetBelowRainThold" 1 "DetAboveRainThold" ;
VAL_ 669 DET_IDM_120 0 "Not_IDM_Output" 1 "IDM_Output" ;
VAL_ 669 DET_MTD_120 0 "Not_MTD_Output" 1 "MTD_Output" ;
VAL_ 669 DET_BELOW_RAIN_THOLD_120 0 "DetBelowRainThold" 1 "DetAboveRainThold" ;
VAL_ 670 DET_CONFD_AZIMUTH_121 0 "High" 1 "MidHigh" 2 "MidLow" 3 "Low" ;
VAL_ 670 DET_CONFD_ELEVATION_121 0 "High" 1 "MidHigh" 2 "MidLow" 3 "Low" ;
VAL_ 670 DET_IDM_121 0 "Not_IDM_Output" 1 "IDM_Output" ;
VAL_ 670 DET_MTD_121 0 "Not_MTD_Output" 1 "MTD_Output" ;
VAL_ 670 DET_BELOW_RAIN_THOLD_121 0 "DetBelowRainThold" 1 "DetAboveRainThold" ;
VAL_ 670 DET_CONFD_AZIMUTH_122 0 "High" 1 "MidHigh" 2 "MidLow" 3 "Low" ;
VAL_ 670 DET_CONFD_ELEVATION_122 0 "High" 1 "MidHigh" 2 "MidLow" 3 "Low" ;
VAL_ 670 DET_IDM_122 0 "Not_IDM_Output" 1 "IDM_Output" ;
VAL_ 670 DET_MTD_122 0 "Not_MTD_Output" 1 "MTD_Output" ;
VAL_ 670 DET_BELOW_RAIN_THOLD_122 0 "DetBelowRainThold" 1 "DetAboveRainThold" ;
VAL_ 670 DET_CONFD_AZIMUTH_123 0 "High" 1 "MidHigh" 2 "MidLow" 3 "Low" ;
VAL_ 670 DET_CONFD_ELEVATION_123 0 "High" 1 "MidHigh" 2 "MidLow" 3 "Low" ;
VAL_ 670 DET_IDM_123 0 "Not_IDM_Output" 1 "IDM_Output" ;
VAL_ 670 DET_MTD_123 0 "Not_MTD_Output" 1 "MTD_Output" ;
VAL_ 670 DET_BELOW_RAIN_THOLD_123 0 "DetBelowRainThold" 1 "DetAboveRainThold" ;
VAL_ 670 DET_IDM_124 0 "Not_IDM_Output" 1 "IDM_Output" ;
VAL_ 670 DET_MTD_124 0 "Not_MTD_Output" 1 "MTD_Output" ;
VAL_ 670 DET_BELOW_RAIN_THOLD_124 0 "DetBelowRainThold" 1 "DetAboveRainThold" ;
VAL_ 671 DET_CONFD_AZIMUTH_125 0 "High" 1 "MidHigh" 2 "MidLow" 3 "Low" ;
VAL_ 671 DET_CONFD_ELEVATION_125 0 "High" 1 "MidHigh" 2 "MidLow" 3 "Low" ;
VAL_ 671 DET_IDM_125 0 "Not_IDM_Output" 1 "IDM_Output" ;
VAL_ 671 DET_MTD_125 0 "Not_MTD_Output" 1 "MTD_Output" ;
VAL_ 671 DET_BELOW_RAIN_THOLD_125 0 "DetBelowRainThold" 1 "DetAboveRainThold" ;
VAL_ 671 DET_CONFD_AZIMUTH_126 0 "High" 1 "MidHigh" 2 "MidLow" 3 "Low" ;
VAL_ 671 DET_CONFD_ELEVATION_126 0 "High" 1 "MidHigh" 2 "MidLow" 3 "Low" ;
VAL_ 671 DET_IDM_126 0 "Not_IDM_Output" 1 "IDM_Output" ;
VAL_ 671 DET_MTD_126 0 "Not_MTD_Output" 1 "MTD_Output" ;
VAL_ 671 DET_BELOW_RAIN_THOLD_126 0 "DetBelowRainThold" 1 "DetAboveRainThold" ;
VAL_ 671 DET_CONFD_AZIMUTH_127 0 "High" 1 "MidHigh" 2 "MidLow" 3 "Low" ;
VAL_ 671 DET_CONFD_ELEVATION_127 0 "High" 1 "MidHigh" 2 "MidLow" 3 "Low" ;
VAL_ 671 DET_IDM_127 0 "Not_IDM_Output" 1 "IDM_Output" ;
VAL_ 671 DET_MTD_127 0 "Not_MTD_Output" 1 "MTD_Output" ;
VAL_ 671 DET_BELOW_RAIN_THOLD_127 0 "DetBelowRainThold" 1 "DetAboveRainThold" ;
VAL_ 671 DET_IDM_128 0 "Not_IDM_Output" 1 "IDM_Output" ;
VAL_ 671 DET_MTD_128 0 "Not_MTD_Output" 1 "MTD_Output" ;
VAL_ 671 DET_BELOW_RAIN_THOLD_128 0 "DetBelowRainThold" 1 "DetAboveRainThold" ;
SIG_GROUP_ 662 SRR_FL_Detections_089_092 1 : DET_PROB_1STAZHYPO_089 DET_PROB_1STAZHYPO_090 DET_PROB_1STAZHYPO_091 DET_PROB_1STAZHYPO_092 DET_IDM_089 DET_IDM_090 DET_IDM_091 DET_IDM_092 DET_MTD_092 DET_MTD_091 DET_MTD_090 DET_MTD_089 DET_BELOW_RAIN_THOLD_092 DET_BELOW_RAIN_THOLD_091 DET_BELOW_RAIN_THOLD_090 DET_BELOW_RAIN_THOLD_089 DET_MH_CRC16_089_092 DET_MH_CYCLE_COUNTER_089_092 DET_MH_SCAN_INDEX_4LSB_089_092 DET_CONFD_ELEVATION_089 DET_CONFD_AZIMUTH_089 DET_HVC_FLAG_089 DET_EXISTENCE_PROB_089 DET_SNR_089 DET_SUPER_RES_TARGET_089 DET_BI_STATIC_FLAG_089 DET_RCS_089 DET_ELEVATION_ERR_089 DET_ELEVATION_089 DET_AZIMUTH_ERR_089 DET_AZIMUTH_089 DET_RANGE_VELOCITY_ERR_089 DET_RANGE_VELOCITY_089 DET_RANGE_ERR_089 DET_RANGE_089 DET_CONFD_ELEVATION_090 DET_CONFD_AZIMUTH_090 DET_HVC_FLAG_090 DET_EXISTENCE_PROB_090 DET_SNR_090 DET_SUPER_RES_TARGET_090 DET_BI_STATIC_FLAG_090 DET_RCS_090 DET_ELEVATION_ERR_090 DET_ELEVATION_090 DET_AZIMUTH_ERR_090 DET_AZIMUTH_090 DET_RANGE_VELOCITY_ERR_090 DET_RANGE_VELOCITY_090 DET_RANGE_ERR_090 DET_RANGE_090 DET_CONFD_ELEVATION_091 DET_CONFD_AZIMUTH_091 DET_HVC_FLAG_091 DET_EXISTENCE_PROB_091 DET_SNR_091 DET_SUPER_RES_TARGET_091 DET_BI_STATIC_FLAG_091 DET_RCS_091 DET_ELEVATION_ERR_091 DET_ELEVATION_091 DET_AZIMUTH_ERR_091 DET_AZIMUTH_091 DET_RANGE_VELOCITY_ERR_091 DET_RANGE_VELOCITY_091 DET_RANGE_ERR_091 DET_RANGE_091 DET_CONFD_ELEVATION_092 DET_CONFD_AZIMUTH_092 DET_HVC_FLAG_092 DET_EXISTENCE_PROB_092 DET_SNR_092 DET_SUPER_RES_TARGET_092 DET_BI_STATIC_FLAG_092 DET_RCS_092 DET_ELEVATION_ERR_092 DET_ELEVATION_092 DET_AZIMUTH_ERR_092 DET_AZIMUTH_092 DET_RANGE_VELOCITY_ERR_092 DET_RANGE_VELOCITY_092 DET_RANGE_ERR_092 DET_RANGE_092;
SIG_GROUP_ 663 SRR_FL_Detections_093_096 1 : DET_PROB_1STAZHYPO_093 DET_PROB_1STAZHYPO_094 DET_PROB_1STAZHYPO_095 DET_PROB_1STAZHYPO_096 DET_IDM_093 DET_IDM_094 DET_IDM_095 DET_IDM_096 DET_MTD_096 DET_MTD_095 DET_MTD_094 DET_MTD_093 DET_BELOW_RAIN_THOLD_096 DET_BELOW_RAIN_THOLD_095 DET_BELOW_RAIN_THOLD_094 DET_BELOW_RAIN_THOLD_093 DET_MH_CRC16_093_096 DET_MH_CYCLE_COUNTER_093_096 DET_MH_SCAN_INDEX_4LSB_093_096 DET_CONFD_ELEVATION_093 DET_CONFD_AZIMUTH_093 DET_HVC_FLAG_093 DET_EXISTENCE_PROB_093 DET_SNR_093 DET_SUPER_RES_TARGET_093 DET_BI_STATIC_FLAG_093 DET_RCS_093 DET_ELEVATION_ERR_093 DET_ELEVATION_093 DET_AZIMUTH_ERR_093 DET_AZIMUTH_093 DET_RANGE_VELOCITY_ERR_093 DET_RANGE_VELOCITY_093 DET_RANGE_ERR_093 DET_RANGE_093 DET_CONFD_ELEVATION_094 DET_CONFD_AZIMUTH_094 DET_HVC_FLAG_094 DET_EXISTENCE_PROB_094 DET_SNR_094 DET_SUPER_RES_TARGET_094 DET_BI_STATIC_FLAG_094 DET_RCS_094 DET_ELEVATION_ERR_094 DET_ELEVATION_094 DET_AZIMUTH_ERR_094 DET_AZIMUTH_094 DET_RANGE_VELOCITY_ERR_094 DET_RANGE_VELOCITY_094 DET_RANGE_ERR_094 DET_RANGE_094 DET_CONFD_ELEVATION_095 DET_CONFD_AZIMUTH_095 DET_HVC_FLAG_095 DET_EXISTENCE_PROB_095 DET_SNR_095 DET_SUPER_RES_TARGET_095 DET_BI_STATIC_FLAG_095 DET_RCS_095 DET_ELEVATION_ERR_095 DET_ELEVATION_095 DET_AZIMUTH_ERR_095 DET_AZIMUTH_095 DET_RANGE_VELOCITY_ERR_095 DET_RANGE_VELOCITY_095 DET_RANGE_ERR_095 DET_RANGE_095 DET_CONFD_ELEVATION_096 DET_CONFD_AZIMUTH_096 DET_HVC_FLAG_096 DET_EXISTENCE_PROB_096 DET_SNR_096 DET_SUPER_RES_TARGET_096 DET_BI_STATIC_FLAG_096 DET_RCS_096 DET_ELEVATION_ERR_096 DET_ELEVATION_096 DET_AZIMUTH_ERR_096 DET_AZIMUTH_096 DET_RANGE_VELOCITY_ERR_096 DET_RANGE_VELOCITY_096 DET_RANGE_ERR_096 DET_RANGE_096;
SIG_GROUP_ 664 SRR_FL_Detections_097_100 1 : DET_PROB_1STAZHYPO_097 DET_PROB_1STAZHYPO_098 DET_PROB_1STAZHYPO_099 DET_PROB_1STAZHYPO_100 DET_IDM_097 DET_IDM_098 DET_IDM_099 DET_IDM_100 DET_MTD_100 DET_MTD_099 DET_MTD_098 DET_MTD_097 DET_BELOW_RAIN_THOLD_100 DET_BELOW_RAIN_THOLD_099 DET_BELOW_RAIN_THOLD_098 DET_BELOW_RAIN_THOLD_097 DET_MH_CRC16_097_100 DET_MH_CYCLE_COUNTER_097_100 DET_MH_SCAN_INDEX_4LSB_097_100 DET_CONFD_ELEVATION_097 DET_CONFD_AZIMUTH_097 DET_HVC_FLAG_097 DET_EXISTENCE_PROB_097 DET_SNR_097 DET_SUPER_RES_TARGET_097 DET_BI_STATIC_FLAG_097 DET_RCS_097 DET_ELEVATION_ERR_097 DET_ELEVATION_097 DET_AZIMUTH_ERR_097 DET_AZIMUTH_097 DET_RANGE_VELOCITY_ERR_097 DET_RANGE_VELOCITY_097 DET_RANGE_ERR_097 DET_RANGE_097 DET_CONFD_ELEVATION_098 DET_CONFD_AZIMUTH_098 DET_HVC_FLAG_098 DET_EXISTENCE_PROB_098 DET_SNR_098 DET_SUPER_RES_TARGET_098 DET_BI_STATIC_FLAG_098 DET_RCS_098 DET_ELEVATION_ERR_098 DET_ELEVATION_098 DET_AZIMUTH_ERR_098 DET_AZIMUTH_098 DET_RANGE_VELOCITY_ERR_098 DET_RANGE_VELOCITY_098 DET_RANGE_ERR_098 DET_RANGE_098 DET_CONFD_ELEVATION_099 DET_CONFD_AZIMUTH_099 DET_HVC_FLAG_099 DET_EXISTENCE_PROB_099 DET_SNR_099 DET_SUPER_RES_TARGET_099 DET_BI_STATIC_FLAG_099 DET_RCS_099 DET_ELEVATION_ERR_099 DET_ELEVATION_099 DET_AZIMUTH_ERR_099 DET_AZIMUTH_099 DET_RANGE_VELOCITY_ERR_099 DET_RANGE_VELOCITY_099 DET_RANGE_ERR_099 DET_RANGE_099 DET_CONFD_ELEVATION_100 DET_CONFD_AZIMUTH_100 DET_HVC_FLAG_100 DET_EXISTENCE_PROB_100 DET_SNR_100 DET_SUPER_RES_TARGET_100 DET_BI_STATIC_FLAG_100 DET_RCS_100 DET_ELEVATION_ERR_100 DET_ELEVATION_100 DET_AZIMUTH_ERR_100 DET_AZIMUTH_100 DET_RANGE_VELOCITY_ERR_100 DET_RANGE_VELOCITY_100 DET_RANGE_ERR_100 DET_RANGE_100;
SIG_GROUP_ 665 SRR_FL_Detections_101_104 1 : DET_PROB_1STAZHYPO_101 DET_PROB_1STAZHYPO_102 DET_PROB_1STAZHYPO_103 DET_PROB_1STAZHYPO_104 DET_IDM_101 DET_IDM_102 DET_IDM_103 DET_IDM_104 DET_MTD_104 DET_MTD_103 DET_MTD_102 DET_MTD_101 DET_BELOW_RAIN_THOLD_104 DET_BELOW_RAIN_THOLD_103 DET_BELOW_RAIN_THOLD_102 DET_BELOW_RAIN_THOLD_101 DET_MH_CRC16_101_104 DET_MH_CYCLE_COUNTER_101_104 DET_MH_SCAN_INDEX_4LSB_101_104 DET_CONFD_ELEVATION_101 DET_CONFD_AZIMUTH_101 DET_HVC_FLAG_101 DET_EXISTENCE_PROB_101 DET_SNR_101 DET_SUPER_RES_TARGET_101 DET_BI_STATIC_FLAG_101 DET_RCS_101 DET_ELEVATION_ERR_101 DET_ELEVATION_101 DET_AZIMUTH_ERR_101 DET_AZIMUTH_101 DET_RANGE_VELOCITY_ERR_101 DET_RANGE_VELOCITY_101 DET_RANGE_ERR_101 DET_RANGE_101 DET_CONFD_ELEVATION_102 DET_CONFD_AZIMUTH_102 DET_HVC_FLAG_102 DET_EXISTENCE_PROB_102 DET_SNR_102 DET_SUPER_RES_TARGET_102 DET_BI_STATIC_FLAG_102 DET_RCS_102 DET_ELEVATION_ERR_102 DET_ELEVATION_102 DET_AZIMUTH_ERR_102 DET_AZIMUTH_102 DET_RANGE_VELOCITY_ERR_102 DET_RANGE_VELOCITY_102 DET_RANGE_ERR_102 DET_RANGE_102 DET_CONFD_ELEVATION_103 DET_CONFD_AZIMUTH_103 DET_HVC_FLAG_103 DET_EXISTENCE_PROB_103 DET_SNR_103 DET_SUPER_RES_TARGET_103 DET_BI_STATIC_FLAG_103 DET_RCS_103 DET_ELEVATION_ERR_103 DET_ELEVATION_103 DET_AZIMUTH_ERR_103 DET_AZIMUTH_103 DET_RANGE_VELOCITY_ERR_103 DET_RANGE_VELOCITY_103 DET_RANGE_ERR_103 DET_RANGE_103 DET_CONFD_ELEVATION_104 DET_CONFD_AZIMUTH_104 DET_HVC_FLAG_104 DET_EXISTENCE_PROB_104 DET_SNR_104 DET_SUPER_RES_TARGET_104 DET_BI_STATIC_FLAG_104 DET_RCS_104 DET_ELEVATION_ERR_104 DET_ELEVATION_104 DET_AZIMUTH_ERR_104 DET_AZIMUTH_104 DET_RANGE_VELOCITY_ERR_104 DET_RANGE_VELOCITY_104 DET_RANGE_ERR_104 DET_RANGE_104;
SIG_GROUP_ 666 SRR_FL_Detections_105_108 1 : DET_PROB_1STAZHYPO_105 DET_PROB_1STAZHYPO_106 DET_PROB_1STAZHYPO_107 DET_PROB_1STAZHYPO_108 DET_IDM_105 DET_IDM_106 DET_IDM_107 DET_IDM_108 DET_MTD_108 DET_MTD_107 DET_MTD_106 DET_MTD_105 DET_BELOW_RAIN_THOLD_108 DET_BELOW_RAIN_THOLD_107 DET_BELOW_RAIN_THOLD_106 DET_BELOW_RAIN_THOLD_105 DET_MH_CRC16_105_108 DET_MH_CYCLE_COUNTER_105_108 DET_MH_SCAN_INDEX_4LSB_105_108 DET_CONFD_ELEVATION_105 DET_CONFD_AZIMUTH_105 DET_HVC_FLAG_105 DET_EXISTENCE_PROB_105 DET_SNR_105 DET_SUPER_RES_TARGET_105 DET_BI_STATIC_FLAG_105 DET_RCS_105 DET_ELEVATION_ERR_105 DET_ELEVATION_105 DET_AZIMUTH_ERR_105 DET_AZIMUTH_105 DET_RANGE_VELOCITY_ERR_105 DET_RANGE_VELOCITY_105 DET_RANGE_ERR_105 DET_RANGE_105 DET_CONFD_ELEVATION_106 DET_CONFD_AZIMUTH_106 DET_HVC_FLAG_106 DET_EXISTENCE_PROB_106 DET_SNR_106 DET_SUPER_RES_TARGET_106 DET_BI_STATIC_FLAG_106 DET_RCS_106 DET_ELEVATION_ERR_106 DET_ELEVATION_106 DET_AZIMUTH_ERR_106 DET_AZIMUTH_106 DET_RANGE_VELOCITY_ERR_106 DET_RANGE_VELOCITY_106 DET_RANGE_ERR_106 DET_RANGE_106 DET_CONFD_ELEVATION_107 DET_CONFD_AZIMUTH_107 DET_HVC_FLAG_107 DET_EXISTENCE_PROB_107 DET_SNR_107 DET_SUPER_RES_TARGET_107 DET_BI_STATIC_FLAG_107 DET_RCS_107 DET_ELEVATION_ERR_107 DET_ELEVATION_107 DET_AZIMUTH_ERR_107 DET_AZIMUTH_107 DET_RANGE_VELOCITY_ERR_107 DET_RANGE_VELOCITY_107 DET_RANGE_ERR_107 DET_RANGE_107 DET_CONFD_ELEVATION_108 DET_CONFD_AZIMUTH_108 DET_HVC_FLAG_108 DET_EXISTENCE_PROB_108 DET_SNR_108 DET_SUPER_RES_TARGET_108 DET_BI_STATIC_FLAG_108 DET_RCS_108 DET_ELEVATION_ERR_108 DET_ELEVATION_108 DET_AZIMUTH_ERR_108 DET_AZIMUTH_108 DET_RANGE_VELOCITY_ERR_108 DET_RANGE_VELOCITY_108 DET_RANGE_ERR_108 DET_RANGE_108;
SIG_GROUP_ 667 SRR_FL_Detections_109_112 1 : DET_PROB_1STAZHYPO_109 DET_PROB_1STAZHYPO_110 DET_PROB_1STAZHYPO_111 DET_PROB_1STAZHYPO_112 DET_IDM_109 DET_IDM_110 DET_IDM_111 DET_IDM_112 DET_MTD_112 DET_MTD_111 DET_MTD_110 DET_MTD_109 DET_BELOW_RAIN_THOLD_112 DET_BELOW_RAIN_THOLD_111 DET_BELOW_RAIN_THOLD_110 DET_BELOW_RAIN_THOLD_109 DET_MH_CRC16_109_112 DET_MH_CYCLE_COUNTER_109_112 DET_MH_SCAN_INDEX_4LSB_109_112 DET_CONFD_ELEVATION_109 DET_CONFD_AZIMUTH_109 DET_HVC_FLAG_109 DET_EXISTENCE_PROB_109 DET_SNR_109 DET_SUPER_RES_TARGET_109 DET_BI_STATIC_FLAG_109 DET_RCS_109 DET_ELEVATION_ERR_109 DET_ELEVATION_109 DET_AZIMUTH_ERR_109 DET_AZIMUTH_109 DET_RANGE_VELOCITY_ERR_109 DET_RANGE_VELOCITY_109 DET_RANGE_ERR_109 DET_RANGE_109 DET_CONFD_ELEVATION_110 DET_CONFD_AZIMUTH_110 DET_HVC_FLAG_110 DET_EXISTENCE_PROB_110 DET_SNR_110 DET_SUPER_RES_TARGET_110 DET_BI_STATIC_FLAG_110 DET_RCS_110 DET_ELEVATION_ERR_110 DET_ELEVATION_110 DET_AZIMUTH_ERR_110 DET_AZIMUTH_110 DET_RANGE_VELOCITY_ERR_110 DET_RANGE_VELOCITY_110 DET_RANGE_ERR_110 DET_RANGE_110 DET_CONFD_ELEVATION_111 DET_CONFD_AZIMUTH_111 DET_HVC_FLAG_111 DET_EXISTENCE_PROB_111 DET_SNR_111 DET_SUPER_RES_TARGET_111 DET_BI_STATIC_FLAG_111 DET_RCS_111 DET_ELEVATION_ERR_111 DET_ELEVATION_111 DET_AZIMUTH_ERR_111 DET_AZIMUTH_111 DET_RANGE_VELOCITY_ERR_111 DET_RANGE_VELOCITY_111 DET_RANGE_ERR_111 DET_RANGE_111 DET_CONFD_ELEVATION_112 DET_CONFD_AZIMUTH_112 DET_HVC_FLAG_112 DET_EXISTENCE_PROB_112 DET_SNR_112 DET_SUPER_RES_TARGET_112 DET_BI_STATIC_FLAG_112 DET_RCS_112 DET_ELEVATION_ERR_112 DET_ELEVATION_112 DET_AZIMUTH_ERR_112 DET_AZIMUTH_112 DET_RANGE_VELOCITY_ERR_112 DET_RANGE_VELOCITY_112 DET_RANGE_ERR_112 DET_RANGE_112;
SIG_GROUP_ 668 SRR_FL_Detections_113_116 1 : DET_PROB_1STAZHYPO_113 DET_PROB_1STAZHYPO_114 DET_PROB_1STAZHYPO_115 DET_PROB_1STAZHYPO_116 DET_IDM_113 DET_IDM_114 DET_IDM_115 DET_IDM_116 DET_MTD_116 DET_MTD_115 DET_MTD_114 DET_MTD_113 DET_BELOW_RAIN_THOLD_116 DET_BELOW_RAIN_THOLD_115 DET_BELOW_RAIN_THOLD_114 DET_BELOW_RAIN_THOLD_113 DET_MH_CRC16_113_116 DET_MH_CYCLE_COUNTER_113_116 DET_MH_SCAN_INDEX_4LSB_113_116 DET_CONFD_ELEVATION_113 DET_CONFD_AZIMUTH_113 DET_HVC_FLAG_113 DET_EXISTENCE_PROB_113 DET_SNR_113 DET_SUPER_RES_TARGET_113 DET_BI_STATIC_FLAG_113 DET_RCS_113 DET_ELEVATION_ERR_113 DET_ELEVATION_113 DET_AZIMUTH_ERR_113 DET_AZIMUTH_113 DET_RANGE_VELOCITY_ERR_113 DET_RANGE_VELOCITY_113 DET_RANGE_ERR_113 DET_RANGE_113 DET_CONFD_ELEVATION_114 DET_CONFD_AZIMUTH_114 DET_HVC_FLAG_114 DET_EXISTENCE_PROB_114 DET_SNR_114 DET_SUPER_RES_TARGET_114 DET_BI_STATIC_FLAG_114 DET_RCS_114 DET_ELEVATION_ERR_114 DET_ELEVATION_114 DET_AZIMUTH_ERR_114 DET_AZIMUTH_114 DET_RANGE_VELOCITY_ERR_114 DET_RANGE_VELOCITY_114 DET_RANGE_ERR_114 DET_RANGE_114 DET_CONFD_ELEVATION_115 DET_CONFD_AZIMUTH_115 DET_HVC_FLAG_115 DET_EXISTENCE_PROB_115 DET_SNR_115 DET_SUPER_RES_TARGET_115 DET_BI_STATIC_FLAG_115 DET_RCS_115 DET_ELEVATION_ERR_115 DET_ELEVATION_115 DET_AZIMUTH_ERR_115 DET_AZIMUTH_115 DET_RANGE_VELOCITY_ERR_115 DET_RANGE_VELOCITY_115 DET_RANGE_ERR_115 DET_RANGE_115 DET_CONFD_ELEVATION_116 DET_CONFD_AZIMUTH_116 DET_HVC_FLAG_116 DET_EXISTENCE_PROB_116 DET_SNR_116 DET_SUPER_RES_TARGET_116 DET_BI_STATIC_FLAG_116 DET_RCS_116 DET_ELEVATION_ERR_116 DET_ELEVATION_116 DET_AZIMUTH_ERR_116 DET_AZIMUTH_116 DET_RANGE_VELOCITY_ERR_116 DET_RANGE_VELOCITY_116 DET_RANGE_ERR_116 DET_RANGE_116;
SIG_GROUP_ 669 SRR_FL_Detections_117_120 1 : DET_PROB_1STAZHYPO_117 DET_PROB_1STAZHYPO_118 DET_PROB_1STAZHYPO_119 DET_PROB_1STAZHYPO_120 DET_IDM_117 DET_IDM_118 DET_IDM_119 DET_IDM_120 DET_MTD_120 DET_MTD_119 DET_MTD_118 DET_MTD_117 DET_BELOW_RAIN_THOLD_120 DET_BELOW_RAIN_THOLD_119 DET_BELOW_RAIN_THOLD_118 DET_BELOW_RAIN_THOLD_117 DET_MH_CRC16_117_120 DET_MH_CYCLE_COUNTER_117_120 DET_MH_SCAN_INDEX_4LSB_117_120 DET_CONFD_ELEVATION_117 DET_CONFD_AZIMUTH_117 DET_HVC_FLAG_117 DET_EXISTENCE_PROB_117 DET_SNR_117 DET_SUPER_RES_TARGET_117 DET_BI_STATIC_FLAG_117 DET_RCS_117 DET_ELEVATION_ERR_117 DET_ELEVATION_117 DET_AZIMUTH_ERR_117 DET_AZIMUTH_117 DET_RANGE_VELOCITY_ERR_117 DET_RANGE_VELOCITY_117 DET_RANGE_ERR_117 DET_RANGE_117 DET_CONFD_ELEVATION_118 DET_CONFD_AZIMUTH_118 DET_HVC_FLAG_118 DET_EXISTENCE_PROB_118 DET_SNR_118 DET_SUPER_RES_TARGET_118 DET_BI_STATIC_FLAG_118 DET_RCS_118 DET_ELEVATION_ERR_118 DET_ELEVATION_118 DET_AZIMUTH_ERR_118 DET_AZIMUTH_118 DET_RANGE_VELOCITY_ERR_118 DET_RANGE_VELOCITY_118 DET_RANGE_ERR_118 DET_RANGE_118 DET_CONFD_ELEVATION_119 DET_CONFD_AZIMUTH_119 DET_HVC_FLAG_119 DET_EXISTENCE_PROB_119 DET_SNR_119 DET_SUPER_RES_TARGET_119 DET_BI_STATIC_FLAG_119 DET_RCS_119 DET_ELEVATION_ERR_119 DET_ELEVATION_119 DET_AZIMUTH_ERR_119 DET_AZIMUTH_119 DET_RANGE_VELOCITY_ERR_119 DET_RANGE_VELOCITY_119 DET_RANGE_ERR_119 DET_RANGE_119 DET_CONFD_ELEVATION_120 DET_CONFD_AZIMUTH_120 DET_HVC_FLAG_120 DET_EXISTENCE_PROB_120 DET_SNR_120 DET_SUPER_RES_TARGET_120 DET_BI_STATIC_FLAG_120 DET_RCS_120 DET_ELEVATION_ERR_120 DET_ELEVATION_120 DET_AZIMUTH_ERR_120 DET_AZIMUTH_120 DET_RANGE_VELOCITY_ERR_120 DET_RANGE_VELOCITY_120 DET_RANGE_ERR_120 DET_RANGE_120;
SIG_GROUP_ 670 SRR_FL_Detections_121_124 1 : DET_PROB_1STAZHYPO_121 DET_PROB_1STAZHYPO_122 DET_PROB_1STAZHYPO_123 DET_PROB_1STAZHYPO_124 DET_IDM_121 DET_IDM_122 DET_IDM_123 DET_IDM_124 DET_MTD_124 DET_MTD_123 DET_MTD_122 DET_MTD_121 DET_BELOW_RAIN_THOLD_124 DET_BELOW_RAIN_THOLD_123 DET_BELOW_RAIN_THOLD_122 DET_BELOW_RAIN_THOLD_121 DET_MH_CRC16_121_124 DET_MH_CYCLE_COUNTER_121_124 DET_MH_SCAN_INDEX_4LSB_121_124 DET_CONFD_ELEVATION_121 DET_CONFD_AZIMUTH_121 DET_HVC_FLAG_121 DET_EXISTENCE_PROB_121 DET_SNR_121 DET_SUPER_RES_TARGET_121 DET_BI_STATIC_FLAG_121 DET_RCS_121 DET_ELEVATION_ERR_121 DET_ELEVATION_121 DET_AZIMUTH_ERR_121 DET_AZIMUTH_121 DET_RANGE_VELOCITY_ERR_121 DET_RANGE_VELOCITY_121 DET_RANGE_ERR_121 DET_RANGE_121 DET_CONFD_ELEVATION_122 DET_CONFD_AZIMUTH_122 DET_HVC_FLAG_122 DET_EXISTENCE_PROB_122 DET_SNR_122 DET_SUPER_RES_TARGET_122 DET_BI_STATIC_FLAG_122 DET_RCS_122 DET_ELEVATION_ERR_122 DET_ELEVATION_122 DET_AZIMUTH_ERR_122 DET_AZIMUTH_122 DET_RANGE_VELOCITY_ERR_122 DET_RANGE_VELOCITY_122 DET_RANGE_ERR_122 DET_RANGE_122 DET_CONFD_ELEVATION_123 DET_CONFD_AZIMUTH_123 DET_HVC_FLAG_123 DET_EXISTENCE_PROB_123 DET_SNR_123 DET_SUPER_RES_TARGET_123 DET_BI_STATIC_FLAG_123 DET_RCS_123 DET_ELEVATION_ERR_123 DET_ELEVATION_123 DET_AZIMUTH_ERR_123 DET_AZIMUTH_123 DET_RANGE_VELOCITY_ERR_123 DET_RANGE_VELOCITY_123 DET_RANGE_ERR_123 DET_RANGE_123 DET_CONFD_ELEVATION_124 DET_CONFD_AZIMUTH_124 DET_HVC_FLAG_124 DET_EXISTENCE_PROB_124 DET_SNR_124 DET_SUPER_RES_TARGET_124 DET_BI_STATIC_FLAG_124 DET_RCS_124 DET_ELEVATION_ERR_124 DET_ELEVATION_124 DET_AZIMUTH_ERR_124 DET_AZIMUTH_124 DET_RANGE_VELOCITY_ERR_124 DET_RANGE_VELOCITY_124 DET_RANGE_ERR_124 DET_RANGE_124;
SIG_GROUP_ 671 SRR_FL_Detections_125_128 1 : DET_PROB_1STAZHYPO_125 DET_PROB_1STAZHYPO_126 DET_PROB_1STAZHYPO_127 DET_PROB_1STAZHYPO_128 DET_IDM_125 DET_IDM_126 DET_IDM_127 DET_IDM_128 DET_MTD_128 DET_MTD_127 DET_MTD_126 DET_MTD_125 DET_BELOW_RAIN_THOLD_128 DET_BELOW_RAIN_THOLD_127 DET_BELOW_RAIN_THOLD_126 DET_BELOW_RAIN_THOLD_125 DET_MH_CRC16_125_128 DET_MH_CYCLE_COUNTER_125_128 DET_MH_SCAN_INDEX_4LSB_125_128 DET_CONFD_ELEVATION_125 DET_CONFD_AZIMUTH_125 DET_HVC_FLAG_125 DET_EXISTENCE_PROB_125 DET_SNR_125 DET_SUPER_RES_TARGET_125 DET_BI_STATIC_FLAG_125 DET_RCS_125 DET_ELEVATION_ERR_125 DET_ELEVATION_125 DET_AZIMUTH_ERR_125 DET_AZIMUTH_125 DET_RANGE_VELOCITY_ERR_125 DET_RANGE_VELOCITY_125 DET_RANGE_ERR_125 DET_RANGE_125 DET_CONFD_ELEVATION_126 DET_CONFD_AZIMUTH_126 DET_HVC_FLAG_126 DET_EXISTENCE_PROB_126 DET_SNR_126 DET_SUPER_RES_TARGET_126 DET_BI_STATIC_FLAG_126 DET_RCS_126 DET_ELEVATION_ERR_126 DET_ELEVATION_126 DET_AZIMUTH_ERR_126 DET_AZIMUTH_126 DET_RANGE_VELOCITY_ERR_126 DET_RANGE_VELOCITY_126 DET_RANGE_ERR_126 DET_RANGE_126 DET_CONFD_ELEVATION_127 DET_CONFD_AZIMUTH_127 DET_HVC_FLAG_127 DET_EXISTENCE_PROB_127 DET_SNR_127 DET_SUPER_RES_TARGET_127 DET_BI_STATIC_FLAG_127 DET_RCS_127 DET_ELEVATION_ERR_127 DET_ELEVATION_127 DET_AZIMUTH_ERR_127 DET_AZIMUTH_127 DET_RANGE_VELOCITY_ERR_127 DET_RANGE_VELOCITY_127 DET_RANGE_ERR_127 DET_RANGE_127 DET_CONFD_ELEVATION_128 DET_CONFD_AZIMUTH_128 DET_HVC_FLAG_128 DET_EXISTENCE_PROB_128 DET_SNR_128 DET_SUPER_RES_TARGET_128 DET_BI_STATIC_FLAG_128 DET_RCS_128 DET_ELEVATION_ERR_128 DET_ELEVATION_128 DET_AZIMUTH_ERR_128 DET_AZIMUTH_128 DET_RANGE_VELOCITY_ERR_128 DET_RANGE_VELOCITY_128 DET_RANGE_ERR_128 DET_RANGE_128;
SIG_GROUP_ 40 SRR_FL_XcpCTOReq 1 : STS_XCP_REQ_CTO_Byte63 STS_XCP_REQ_CTO_Byte62 STS_XCP_REQ_CTO_Byte61 STS_XCP_REQ_CTO_Byte60 STS_XCP_REQ_CTO_Byte59 STS_XCP_REQ_CTO_Byte58 STS_XCP_REQ_CTO_Byte57 STS_XCP_REQ_CTO_Byte56 STS_XCP_REQ_CTO_Byte55 STS_XCP_REQ_CTO_Byte54 STS_XCP_REQ_CTO_Byte53 STS_XCP_REQ_CTO_Byte52 STS_XCP_REQ_CTO_Byte51 STS_XCP_REQ_CTO_Byte50 STS_XCP_REQ_CTO_Byte49 STS_XCP_REQ_CTO_Byte48 STS_XCP_REQ_CTO_Byte47 STS_XCP_REQ_CTO_Byte46 STS_XCP_REQ_CTO_Byte45 STS_XCP_REQ_CTO_Byte44 STS_XCP_REQ_CTO_Byte43 STS_XCP_REQ_CTO_Byte42 STS_XCP_REQ_CTO_Byte41 STS_XCP_REQ_CTO_Byte40 STS_XCP_REQ_CTO_Byte39 STS_XCP_REQ_CTO_Byte38 STS_XCP_REQ_CTO_Byte37 STS_XCP_REQ_CTO_Byte36 STS_XCP_REQ_CTO_Byte35 STS_XCP_REQ_CTO_Byte34 STS_XCP_REQ_CTO_Byte33 STS_XCP_REQ_CTO_Byte32 STS_PID STS_XCP_REQ_CTO_Byte1 STS_XCP_REQ_CTO_Byte2 STS_XCP_REQ_CTO_Byte3 STS_XCP_REQ_CTO_Byte4 STS_XCP_REQ_CTO_Byte5 STS_XCP_REQ_CTO_Byte6 STS_XCP_REQ_CTO_Byte7 STS_XCP_REQ_CTO_Byte8 STS_XCP_REQ_CTO_Byte9 STS_XCP_REQ_CTO_Byte10 STS_XCP_REQ_CTO_Byte11 STS_XCP_REQ_CTO_Byte12 STS_XCP_REQ_CTO_Byte13 STS_XCP_REQ_CTO_Byte14 STS_XCP_REQ_CTO_Byte15 STS_XCP_REQ_CTO_Byte16 STS_XCP_REQ_CTO_Byte17 STS_XCP_REQ_CTO_Byte18 STS_XCP_REQ_CTO_Byte19 STS_XCP_REQ_CTO_Byte20 STS_XCP_REQ_CTO_Byte21 STS_XCP_REQ_CTO_Byte22 STS_XCP_REQ_CTO_Byte23 STS_XCP_REQ_CTO_Byte24 STS_XCP_REQ_CTO_Byte25 STS_XCP_REQ_CTO_Byte26 STS_XCP_REQ_CTO_Byte27 STS_XCP_REQ_CTO_Byte28 STS_XCP_REQ_CTO_Byte29 STS_XCP_REQ_CTO_Byte30 STS_XCP_REQ_CTO_Byte31;
